VERSION ""

NS_ :

BS_:

BU_:

BO_ 2566785022 ET: 8 Vector__XXX
 SG_ EngnExhstMnfldBnk1Tmprtr1 : 16|16@1+ (0.03125,-273) [-273|1734.96875] "degC" Vector__XXX
 SG_ EngnExhstMnfldBnk1Tmprtr2 : 48|16@1+ (0.03125,-273) [-273|1734.96875] "degC" Vector__XXX
 SG_ EngnExhstMnfldBnk2Tmprtr1 : 0|16@1+ (0.03125,-273) [-273|1734.96875] "degC" Vector__XXX
 SG_ EngnExhstMnfldBnk2Tmprtr2 : 32|16@1+ (0.03125,-273) [-273|1734.96875] "degC" Vector__XXX

BO_ 2566799614 LD: 8 Vector__XXX
 SG_ AlternateBeamHeadLightData : 2|2@1+ (1,0) [0|3] "" Vector__XXX
 SG_ BackUpLightandAlarmHorn : 16|2@1+ (1,0) [0|3] "" Vector__XXX
 SG_ CenterStopLight : 18|2@1+ (1,0) [0|3] "" Vector__XXX
 SG_ HighBeamHeadLightData : 6|2@1+ (1,0) [0|3] "" Vector__XXX
 SG_ ImplementClearanceLight : 24|2@1+ (1,0) [0|3] "" Vector__XXX
 SG_ ImplementLeftFacingWorkLight : 60|2@1+ (1,0) [0|3] "" Vector__XXX
 SG_ ImplementLeftForwardWorkLight : 54|2@1+ (1,0) [0|3] "" Vector__XXX
 SG_ ImplementMarkerLight : 28|2@1+ (1,0) [0|3] "" Vector__XXX
 SG_ ImplementOEMOption1Light : 50|2@1+ (1,0) [0|3] "" Vector__XXX
 SG_ ImplementOEMOption2Light : 48|2@1+ (1,0) [0|3] "" Vector__XXX
 SG_ ImplementRearWorkLight : 62|2@1+ (1,0) [0|3] "" Vector__XXX
 SG_ ImplementRightFacingWorkLight : 52|2@1+ (1,0) [0|3] "" Vector__XXX
 SG_ ImplementRightForwardWorkLight : 58|2@1+ (1,0) [0|3] "" Vector__XXX
 SG_ LeftStopLight : 22|2@1+ (1,0) [0|3] "" Vector__XXX
 SG_ LeftTurnSignalLights : 14|2@1+ (1,0) [0|3] "" Vector__XXX
 SG_ LowBeamHeadLightData : 4|2@1+ (1,0) [0|3] "" Vector__XXX
 SG_ RearFogLights : 32|2@1+ (1,0) [0|3] "" Vector__XXX
 SG_ RightStopLight : 20|2@1+ (1,0) [0|3] "" Vector__XXX
 SG_ RightTurnSignalLights : 12|2@1+ (1,0) [0|3] "" Vector__XXX
 SG_ RotatingBeaconLight : 10|2@1+ (1,0) [0|3] "" Vector__XXX
 SG_ RunningLight : 0|2@1+ (1,0) [0|3] "" Vector__XXX
 SG_ TractorClearanceLight : 26|2@1+ (1,0) [0|3] "" Vector__XXX
 SG_ TractorFrontFogLights : 8|2@1+ (1,0) [0|3] "" Vector__XXX
 SG_ TractorMarkerLight : 30|2@1+ (1,0) [0|3] "" Vector__XXX
 SG_ TractorRearLowMountedWorkLights : 36|2@1+ (1,0) [0|3] "" Vector__XXX
 SG_ TractorSideLowMountedWorkLights : 40|2@1+ (1,0) [0|3] "" Vector__XXX
 SG_ TrtrFrntHghMntdWrkLghts : 46|2@1+ (1,0) [0|3] "" Vector__XXX
 SG_ TrtrFrntLwMntdWrkLghts : 44|2@1+ (1,0) [0|3] "" Vector__XXX
 SG_ TrtrRrHghMntdWrkLghts : 38|2@1+ (1,0) [0|3] "" Vector__XXX
 SG_ TrtrSdHghMntdWrkLghts : 42|2@1+ (1,0) [0|3] "" Vector__XXX
 SG_ TrtrUndrsdMntdWrkLghts : 34|2@1+ (1,0) [0|3] "" Vector__XXX

BO_ 2566802174 ETC7: 8 Vector__XXX
 SG_ ActiveShiftConsoleIndicator : 10|2@1+ (1,0) [0|3] "" Vector__XXX
 SG_ TransmissionEngineCrankEnable : 12|2@1+ (1,0) [0|3] "" Vector__XXX
 SG_ TransmissionManualModeIndicator : 54|2@1+ (1,0) [0|3] "" Vector__XXX
 SG_ TransmissionMode10Indicator : 46|2@1+ (1,0) [0|3] "" Vector__XXX
 SG_ TransmissionMode1Indicator : 22|2@1+ (1,0) [0|3] "" Vector__XXX
 SG_ TransmissionMode2Indicator : 20|2@1+ (1,0) [0|3] "" Vector__XXX
 SG_ TransmissionMode3Indicator : 18|2@1+ (1,0) [0|3] "" Vector__XXX
 SG_ TransmissionMode4Indicator : 16|2@1+ (1,0) [0|3] "" Vector__XXX
 SG_ TransmissionMode5Indicator : 32|2@1+ (1,0) [0|3] "" Vector__XXX
 SG_ TransmissionMode6Indicator : 34|2@1+ (1,0) [0|3] "" Vector__XXX
 SG_ TransmissionMode7Indicator : 36|2@1+ (1,0) [0|3] "" Vector__XXX
 SG_ TransmissionMode8Indicator : 38|2@1+ (1,0) [0|3] "" Vector__XXX
 SG_ TransmissionMode9Indicator : 44|2@1+ (1,0) [0|3] "" Vector__XXX
 SG_ TransmissionServiceIndicator : 2|2@1+ (1,0) [0|3] "" Vector__XXX
 SG_ TransmissionWarningIndicator : 42|2@1+ (1,0) [0|3] "" Vector__XXX
 SG_ TrnsmssnArSpplPrssrIndtr : 48|3@1+ (1,0) [0|7] "" Vector__XXX
 SG_ TrnsmssnAtNtrlMnlRtrnStt : 51|3@1+ (1,0) [0|7] "" Vector__XXX
 SG_ TrnsmssnCrrntRngDsplBlnkStt : 0|2@1+ (1,0) [0|3] "" Vector__XXX
 SG_ TrnsmssnRdfrBrkRls : 8|2@1+ (1,0) [0|3] "" Vector__XXX
 SG_ TrnsmssnRqstdGrFdk : 24|8@1+ (1,-125) [-125|125] "gear value" Vector__XXX
 SG_ TrnsmssnRqstdRngDsplBlnkStt : 4|2@1+ (1,0) [0|3] "" Vector__XXX
 SG_ TrnsmssnRqstdRngDsplFlshStt : 6|2@1+ (1,0) [0|3] "" Vector__XXX
 SG_ TrnsmssnRvrsGrShftInhtStts : 40|2@1+ (1,0) [0|3] "" Vector__XXX
 SG_ TrnsmssnShftInhtIndtr : 14|2@1+ (1,0) [0|3] "" Vector__XXX

BO_ 2566802430 TCFG2: 8 Vector__XXX
 SG_ TransmissionReferenceTorque : 16|16@1+ (1,0) [0|64255] "Nm" Vector__XXX
 SG_ TransmissionTorqueLimit : 0|16@1+ (1,0) [0|64255] "Nm" Vector__XXX
 SG_ TrnsmssnCmmntnsFlrIdlTrqLmt : 32|8@1+ (1,-125) [-125|125] "%" Vector__XXX

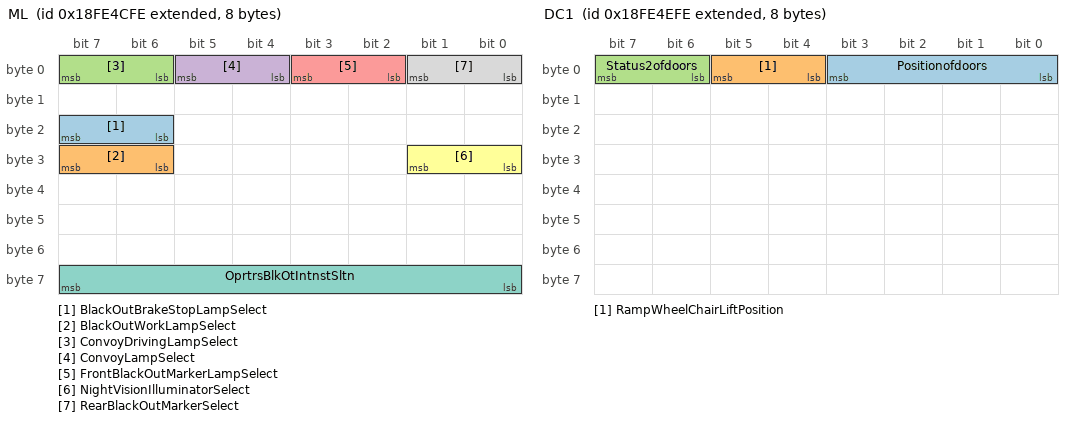
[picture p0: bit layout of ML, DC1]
BO_ 2566802686 ML: 8 Vector__XXX
 SG_ BlackOutBrakeStopLampSelect : 22|2@1+ (1,0) [0|3] "" Vector__XXX
 SG_ BlackOutWorkLampSelect : 30|2@1+ (1,0) [0|3] "" Vector__XXX
 SG_ ConvoyDrivingLampSelect : 6|2@1+ (1,0) [0|3] "" Vector__XXX
 SG_ ConvoyLampSelect : 4|2@1+ (1,0) [0|3] "" Vector__XXX
 SG_ FrontBlackOutMarkerLampSelect : 2|2@1+ (1,0) [0|3] "" Vector__XXX
 SG_ NightVisionIlluminatorSelect : 24|2@1+ (1,0) [0|3] "" Vector__XXX
 SG_ OprtrsBlkOtIntnstSltn : 56|8@1+ (0.4,0) [0|100] "%" Vector__XXX
 SG_ RearBlackOutMarkerSelect : 0|2@1+ (1,0) [0|3] "" Vector__XXX

BO_ 2566803198 DC1: 8 Vector__XXX
 SG_ Positionofdoors : 0|4@1+ (1,0) [0|15] "" Vector__XXX
 SG_ RampWheelChairLiftPosition : 4|2@1+ (1,0) [0|3] "" Vector__XXX
 SG_ Status2ofdoors : 6|2@1+ (1,0) [0|3] "" Vector__XXX

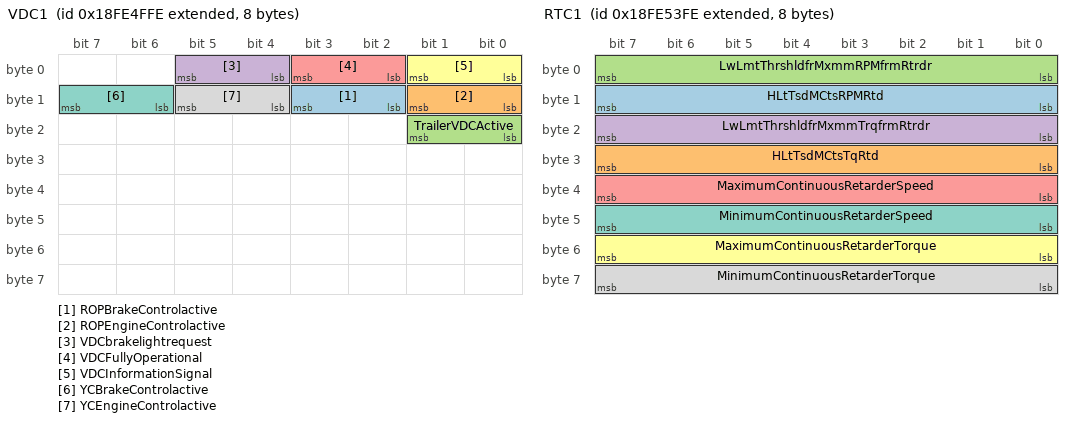
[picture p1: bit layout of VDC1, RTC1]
BO_ 2566803454 VDC1: 8 Vector__XXX
 SG_ ROPBrakeControlactive : 10|2@1+ (1,0) [0|3] "" Vector__XXX
 SG_ ROPEngineControlactive : 8|2@1+ (1,0) [0|3] "" Vector__XXX
 SG_ TrailerVDCActive : 16|2@1+ (1,0) [0|3] "" Vector__XXX
 SG_ VDCbrakelightrequest : 4|2@1+ (1,0) [0|3] "" Vector__XXX
 SG_ VDCFullyOperational : 2|2@1+ (1,0) [0|3] "" Vector__XXX
 SG_ VDCInformationSignal : 0|2@1+ (1,0) [0|3] "" Vector__XXX
 SG_ YCBrakeControlactive : 14|2@1+ (1,0) [0|3] "" Vector__XXX
 SG_ YCEngineControlactive : 12|2@1+ (1,0) [0|3] "" Vector__XXX

BO_ 2566803710 BT1: 8 Vector__XXX
 SG_ SLIBattery1Temperature : 0|8@1+ (1,-40) [-40|210] "degC" Vector__XXX
 SG_ SLIBattery2Temperature : 8|8@1+ (1,-40) [-40|210] "degC" Vector__XXX
 SG_ SLIBattery3Temperature : 16|8@1+ (1,-40) [-40|210] "degC" Vector__XXX
 SG_ SLIBattery4Temperature : 24|8@1+ (1,-40) [-40|210] "degC" Vector__XXX

BO_ 2566803966 ACC2: 8 Vector__XXX
 SG_ ACCusagedemand : 0|2@1+ (1,0) [0|3] "" Vector__XXX
 SG_ RequestedACCDistanceMode : 5|3@1+ (1,0) [0|7] "" Vector__XXX

BO_ 2566804222 VEP3: 8 Vector__XXX
 SG_ AltrntrCrrntHghRngRsltn : 0|16@1+ (0.05,-1600) [-1600|1612.75] "A" Vector__XXX
 SG_ SLIBattery2NetCurrent : 32|16@1+ (0.05,-1600) [-1600|1612.75] "A" Vector__XXX
 SG_ SLIBttr1NtCrrntHghRngRsltn : 16|16@1+ (0.05,-1600) [-1600|1612.75] "A" Vector__XXX

BO_ 2566804478 RTC1: 8 Vector__XXX
 SG_ HLtTsdMCtsRPMRtd : 8|8@1+ (32,0) [0|8000] "rpm" Vector__XXX
 SG_ HLtTsdMCtsTqRtd : 24|8@1+ (1,-125) [-125|125] "%" Vector__XXX
 SG_ LwLmtThrshldfrMxmmRPMfrmRtrdr : 0|8@1+ (32,0) [0|8000] "rpm" Vector__XXX
 SG_ LwLmtThrshldfrMxmmTrqfrmRtrdr : 16|8@1+ (1,-125) [-125|125] "%" Vector__XXX
 SG_ MaximumContinuousRetarderSpeed : 32|8@1+ (32,0) [0|8000] "rpm" Vector__XXX
 SG_ MaximumContinuousRetarderTorque : 48|8@1+ (1,-125) [-125|125] "%" Vector__XXX
 SG_ MinimumContinuousRetarderSpeed : 40|8@1+ (32,0) [0|8000] "rpm" Vector__XXX
 SG_ MinimumContinuousRetarderTorque : 56|8@1+ (1,-125) [-125|125] "%" Vector__XXX

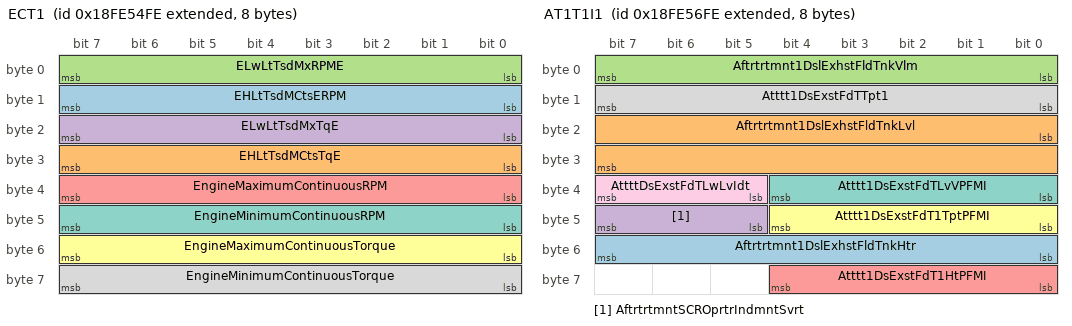
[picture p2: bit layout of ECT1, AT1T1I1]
BO_ 2566804734 ECT1: 8 Vector__XXX
 SG_ EHLtTsdMCtsERPM : 8|8@1+ (32,0) [0|8000] "rpm" Vector__XXX
 SG_ EHLtTsdMCtsTqE : 24|8@1+ (1,-125) [-125|125] "%" Vector__XXX
 SG_ ELwLtTsdMxRPME : 0|8@1+ (32,0) [0|8000] "rpm" Vector__XXX
 SG_ ELwLtTsdMxTqE : 16|8@1+ (1,-125) [-125|125] "%" Vector__XXX
 SG_ EngineMaximumContinuousRPM : 32|8@1+ (32,0) [0|8000] "rpm" Vector__XXX
 SG_ EngineMaximumContinuousTorque : 48|8@1+ (1,-125) [-125|125] "%" Vector__XXX
 SG_ EngineMinimumContinuousRPM : 40|8@1+ (32,0) [0|8000] "rpm" Vector__XXX
 SG_ EngineMinimumContinuousTorque : 56|8@1+ (1,-125) [-125|125] "%" Vector__XXX

BO_ 2566804990 GFD: 8 Vector__XXX
 SG_ Fuelenergycontent : 32|16@1+ (0.00390625,0) [0|250.996] "MJ/(Nm*Nm*Nm)" Vector__XXX
 SG_ ReferenceEngineGasMassFlowRate : 16|16@1+ (0.05,0) [0|3212.75] "kg/h" Vector__XXX
 SG_ SpecificHeatRatio : 0|16@1+ (0.001,0) [0|64.255] "Ratio" Vector__XXX

BO_ 2566805246 AT1T1I1: 8 Vector__XXX
 SG_ Aftrtrtmnt1DslExhstFldTnkHtr : 48|8@1+ (0.4,0) [0|100] "%" Vector__XXX
 SG_ Aftrtrtmnt1DslExhstFldTnkLvl : 16|16@1+ (0.1,0) [0|6425.5] "mm" Vector__XXX
 SG_ Aftrtrtmnt1DslExhstFldTnkVlm : 0|8@1+ (0.4,0) [0|100] "%" Vector__XXX
 SG_ AftrtrtmntSCROprtrIndmntSvrt : 45|3@1+ (1,0) [0|7] "" Vector__XXX
 SG_ Atttt1DsExstFdT1HtPFMI : 56|5@1+ (1,0) [0|31] "binary" Vector__XXX
 SG_ Atttt1DsExstFdT1TptPFMI : 40|5@1+ (1,0) [0|31] "binary" Vector__XXX
 SG_ Atttt1DsExstFdTLvVPFMI : 32|5@1+ (1,0) [0|31] "binary" Vector__XXX
 SG_ Atttt1DsExstFdTTpt1 : 8|8@1+ (1,-40) [-40|210] "degC" Vector__XXX
 SG_ AttttDsExstFdTLwLvIdt : 37|3@1+ (1,0) [0|7] "" Vector__XXX

BO_ 2566805758 ASC4: 8 Vector__XXX
 SG_ BellowPressureFrontAxleLeft : 0|16@1+ (0.1,0) [0|6425.5] "kPa" Vector__XXX
 SG_ BellowPressureFrontAxleRight : 16|16@1+ (0.1,0) [0|6425.5] "kPa" Vector__XXX
 SG_ BellowPressureRearAxleLeft : 32|16@1+ (0.1,0) [0|6425.5] "kPa" Vector__XXX
 SG_ BellowPressureRearAxleRight : 48|16@1+ (0.1,0) [0|6425.5] "kPa" Vector__XXX

BO_ 2566806014 ASC3: 8 Vector__XXX
 SG_ RelativeLevelFrontAxleLeft : 0|16@1+ (0.1,-3200) [-3200|3225.5] "mm" Vector__XXX
 SG_ RelativeLevelFrontAxleRight : 16|16@1+ (0.1,-3200) [-3200|3225.5] "mm" Vector__XXX
 SG_ RelativeLevelRearAxleLeft : 32|16@1+ (0.1,-3200) [-3200|3225.5] "mm" Vector__XXX
 SG_ RelativeLevelRearAxleRight : 48|16@1+ (0.1,-3200) [-3200|3225.5] "mm" Vector__XXX

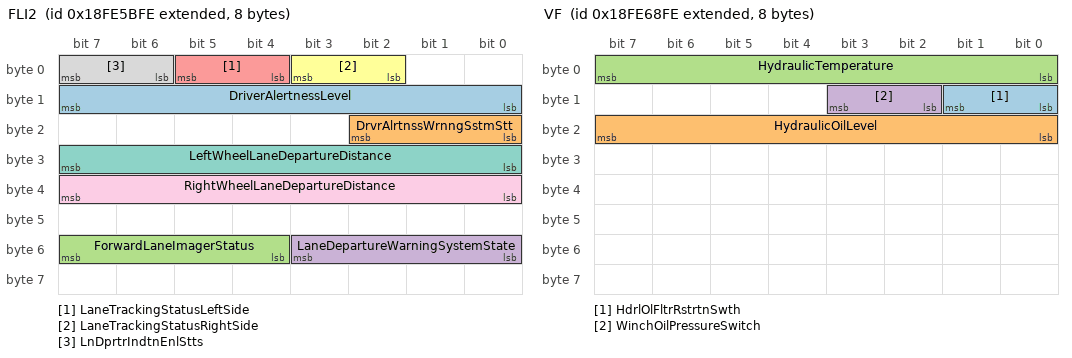
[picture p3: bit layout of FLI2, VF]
BO_ 2566806526 FLI2: 8 Vector__XXX
 SG_ DriverAlertnessLevel : 8|8@1+ (0.4,0) [0|100] "%" Vector__XXX
 SG_ DrvrAlrtnssWrnngSstmStt : 16|3@1+ (1,0) [0|7] "" Vector__XXX
 SG_ ForwardLaneImagerStatus : 52|4@1+ (1,0) [0|15] "" Vector__XXX
 SG_ LaneDepartureWarningSystemState : 48|4@1+ (1,0) [0|15] "" Vector__XXX
 SG_ LaneTrackingStatusLeftSide : 4|2@1+ (1,0) [0|3] "" Vector__XXX
 SG_ LaneTrackingStatusRightSide : 2|2@1+ (1,0) [0|3] "" Vector__XXX
 SG_ LeftWheelLaneDepartureDistance : 24|8@1+ (1,-125) [-125|125] "cm" Vector__XXX
 SG_ LnDprtrIndtnEnlStts : 6|2@1+ (1,0) [0|3] "" Vector__XXX
 SG_ RightWheelLaneDepartureDistance : 32|8@1+ (1,-125) [-125|125] "cm" Vector__XXX

BO_ 2566809342 BM: 8 Vector__XXX
 SG_ BatteryMainSwitchHoldState : 0|2@1+ (1,0) [0|3] "" Vector__XXX

BO_ 2566809598 CCC: 8 Vector__XXX
 SG_ AxlrHtrMxmmOtptPwr : 0|16@1+ (2,0) [0|128510] "W" Vector__XXX

BO_ 2566809854 VF: 8 Vector__XXX
 SG_ HdrlOlFltrRstrtnSwth : 8|2@1+ (1,0) [0|3] "" Vector__XXX
 SG_ HydraulicOilLevel : 16|8@1+ (0.4,0) [0|100] "%" Vector__XXX
 SG_ HydraulicTemperature : 0|8@1+ (1,-40) [-40|210] "degC" Vector__XXX
 SG_ WinchOilPressureSwitch : 10|2@1+ (1,0) [0|3] "" Vector__XXX

BO_ 2566810110 ET3: 8 Vector__XXX
 SG_ EngnChrgArClr1OtltTmprtr : 48|16@1+ (0.03125,-273) [-273|1734.96875] "degC" Vector__XXX
 SG_ EngnClntTmprtrHghRsltn : 16|16@1+ (0.03125,-273) [-273|1734.96875] "degC" Vector__XXX
 SG_ EngnIntkMnfld1TmprtrHghRsltn : 0|16@1+ (0.03125,-273) [-273|1734.96875] "degC" Vector__XXX
 SG_ EngnIntkVlvAttnSstmOlTmprtr : 32|16@1+ (0.03125,-273) [-273|1734.96875] "degC" Vector__XXX

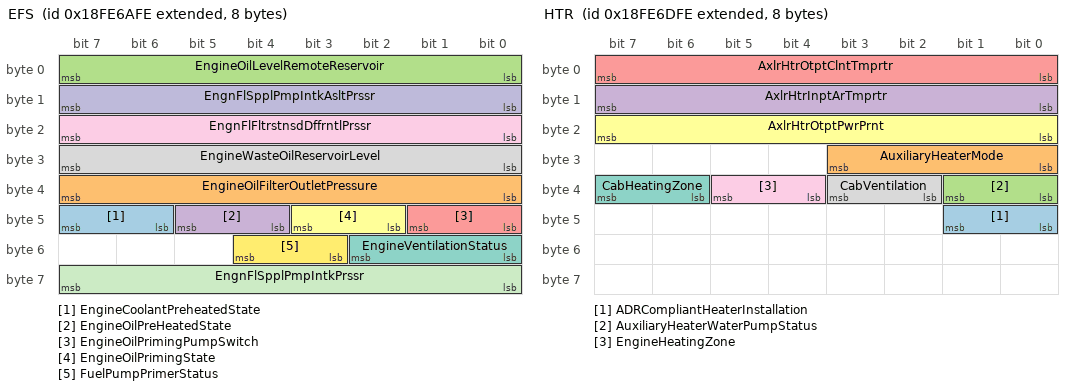
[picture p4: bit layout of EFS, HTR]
BO_ 2566810366 EFS: 8 Vector__XXX
 SG_ EngineCoolantPreheatedState : 46|2@1+ (1,0) [0|3] "" Vector__XXX
 SG_ EngineOilFilterOutletPressure : 32|8@1+ (4,0) [0|1000] "kPa" Vector__XXX
 SG_ EngineOilLevelRemoteReservoir : 0|8@1+ (0.4,0) [0|100] "%" Vector__XXX
 SG_ EngineOilPreHeatedState : 44|2@1+ (1,0) [0|3] "" Vector__XXX
 SG_ EngineOilPrimingPumpSwitch : 40|2@1+ (1,0) [0|3] "" Vector__XXX
 SG_ EngineOilPrimingState : 42|2@1+ (1,0) [0|3] "" Vector__XXX
 SG_ EngineVentilationStatus : 48|3@1+ (1,0) [0|7] "" Vector__XXX
 SG_ EngineWasteOilReservoirLevel : 24|8@1+ (0.4,0) [0|100] "%" Vector__XXX
 SG_ EngnFlFltrstnsdDffrntlPrssr : 16|8@1+ (2,0) [0|500] "kPa" Vector__XXX
 SG_ EngnFlSpplPmpIntkAsltPrssr : 8|8@1+ (2,0) [0|500] "kPa" Vector__XXX
 SG_ EngnFlSpplPmpIntkPrssr : 56|8@1+ (2,0) [0|500] "kPa" Vector__XXX
 SG_ FuelPumpPrimerStatus : 51|2@1+ (1,0) [0|3] "" Vector__XXX

BO_ 2566810622 DI: 8 Vector__XXX
 SG_ Driver1identification : 0|8@1+ (1,0) [0|255] "ASCII" Vector__XXX
 SG_ Driver2identification : 8|8@1+ (1,0) [0|255] "ASCII" Vector__XXX

BO_ 2566811134 HTR: 8 Vector__XXX
 SG_ ADRCompliantHeaterInstallation : 40|2@1+ (1,0) [0|3] "" Vector__XXX
 SG_ AuxiliaryHeaterMode : 24|4@1+ (1,0) [0|15] "" Vector__XXX
 SG_ AuxiliaryHeaterWaterPumpStatus : 32|2@1+ (1,0) [0|3] "" Vector__XXX
 SG_ AxlrHtrInptArTmprtr : 8|8@1+ (1,-40) [-40|210] "degC" Vector__XXX
 SG_ AxlrHtrOtptClntTmprtr : 0|8@1+ (1,-40) [-40|210] "degC" Vector__XXX
 SG_ AxlrHtrOtptPwrPrnt : 16|8@1+ (0.4,0) [0|100] "%" Vector__XXX
 SG_ CabHeatingZone : 38|2@1+ (1,0) [0|3] "" Vector__XXX
 SG_ CabVentilation : 34|2@1+ (1,0) [0|3] "" Vector__XXX
 SG_ EngineHeatingZone : 36|2@1+ (1,0) [0|3] "" Vector__XXX

BO_ 2566811902 CVW: 8 Vector__XXX
 SG_ GrossCombinationVehicleWeight : 16|16@1+ (10,0) [0|642550] "kg" Vector__XXX
 SG_ PoweredVehicleWeight : 0|16@1+ (10,0) [0|642550] "kg" Vector__XXX

BO_ 2566819326 VEP2: 8 Vector__XXX
 SG_ BatteryPotentialPowerInput2 : 0|16@1+ (0.05,0) [0|3212.75] "V" Vector__XXX
 SG_ ECUPowerOutputSupplyVoltage1 : 16|16@1+ (0.05,0) [0|3212.75] "V" Vector__XXX
 SG_ ECUPowerOutputSupplyVoltage2 : 32|16@1+ (0.05,0) [0|3212.75] "V" Vector__XXX
 SG_ ECUPowerOutputSupplyVoltage3 : 48|16@1+ (0.05,0) [0|3212.75] "V" Vector__XXX

BO_ 2566819838 SP2: 8 Vector__XXX
 SG_ EngnExtrnlShtdwnArSpplPrssr : 0|16@1+ (0.5,0) [0|32127.5] "kPa" Vector__XXX

BO_ 2566820094 ETH: 33 Vector__XXX
 SG_ CalibrationRecordDurationTime : 80|32@1+ (0.05,0) [0|210554060.75] "h" Vector__XXX
 SG_ CalibrationRecordStartDay : 64|8@1+ (0.25,0) [0|62.5] "days" Vector__XXX
 SG_ CalibrationRecordStartMonth : 56|8@1+ (1,0) [0|250] "months" Vector__XXX
 SG_ CalibrationRecordStartYear : 72|8@1+ (1,1985) [1985|2235] "years" Vector__XXX
 SG_ EnginePeakTorque1 : 24|16@1+ (1,0) [0|64255] "Nm" Vector__XXX
 SG_ EnginePeakTorque2 : 40|16@1+ (1,0) [0|64255] "Nm" Vector__XXX
 SG_ EnginePower : 8|16@1+ (0.5,0) [0|32127.5] "kW" Vector__XXX
 SG_ EngineTorqueLimit1Transmission : 136|16@1+ (1,0) [0|64255] "Nm" Vector__XXX
 SG_ EngineTorqueLimit2Transmission : 168|16@1+ (1,0) [0|64255] "Nm" Vector__XXX
 SG_ EngineTorqueLimit3Transmission : 200|16@1+ (1,0) [0|64255] "Nm" Vector__XXX
 SG_ EngineTorqueLimit4Transmission : 216|16@1+ (1,0) [0|64255] "Nm" Vector__XXX
 SG_ EngineTorqueLimit5Switch : 232|16@1+ (1,0) [0|64255] "Nm" Vector__XXX
 SG_ EngineTorqueLimit6AxleInput : 248|16@1+ (2,0) [0|128510] "Nm" Vector__XXX
 SG_ EngineTorqueLimitFeature : 114|3@1+ (1,0) [0|7] "" Vector__XXX
 SG_ NmrfEngnTrqHstrRrds : 0|8@1+ (1,0) [0|250] "Record" Vector__XXX
 SG_ TorqueLimitingFeatureStatus : 112|2@1+ (1,0) [0|3] "" Vector__XXX
 SG_ TransmissionGearRatio1 : 120|16@1+ (0.01,0) [0|642.55] "" Vector__XXX
 SG_ TransmissionGearRatio2 : 152|16@1+ (0.01,0) [0|642.55] "" Vector__XXX
 SG_ TransmissionGearRatio3 : 184|16@1+ (0.01,0) [0|642.55] "" Vector__XXX

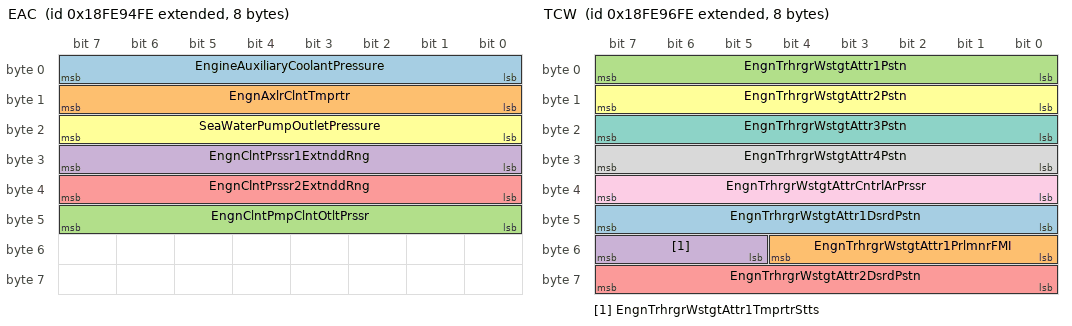
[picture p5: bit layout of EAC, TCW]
BO_ 2566821118 EAC: 8 Vector__XXX
 SG_ EngineAuxiliaryCoolantPressure : 0|8@1+ (4,0) [0|1000] "kPa" Vector__XXX
 SG_ EngnAxlrClntTmprtr : 8|8@1+ (1,-40) [-40|210] "degC" Vector__XXX
 SG_ EngnClntPmpClntOtltPrssr : 40|8@1+ (2,0) [0|500] "kPa" Vector__XXX
 SG_ EngnClntPrssr1ExtnddRng : 24|8@1+ (4,0) [0|1000] "kPa" Vector__XXX
 SG_ EngnClntPrssr2ExtnddRng : 32|8@1+ (4,0) [0|1000] "kPa" Vector__XXX
 SG_ SeaWaterPumpOutletPressure : 16|8@1+ (2,0) [0|500] "kPa" Vector__XXX

BO_ 2566821630 TCW: 8 Vector__XXX
 SG_ EngnTrhrgrWstgtAttr1DsrdPstn : 40|8@1+ (0.4,0) [0|100] "%" Vector__XXX
 SG_ EngnTrhrgrWstgtAttr1PrlmnrFMI : 48|5@1+ (1,0) [0|31] "binary" Vector__XXX
 SG_ EngnTrhrgrWstgtAttr1Pstn : 0|8@1+ (0.4,0) [0|100] "%" Vector__XXX
 SG_ EngnTrhrgrWstgtAttr1TmprtrStts : 53|3@1+ (1,0) [0|7] "" Vector__XXX
 SG_ EngnTrhrgrWstgtAttr2DsrdPstn : 56|8@1+ (0.4,0) [0|100] "%" Vector__XXX
 SG_ EngnTrhrgrWstgtAttr2Pstn : 8|8@1+ (0.4,0) [0|100] "%" Vector__XXX
 SG_ EngnTrhrgrWstgtAttr3Pstn : 16|8@1+ (0.4,0) [0|100] "%" Vector__XXX
 SG_ EngnTrhrgrWstgtAttr4Pstn : 24|8@1+ (0.4,0) [0|100] "%" Vector__XXX
 SG_ EngnTrhrgrWstgtAttrCntrlArPrssr : 32|8@1+ (4,0) [0|1000] "kPa" Vector__XXX

BO_ 2566821886 TCI5: 8 Vector__XXX
 SG_ EngnTrhrgr1TrnOtltTmprtr : 0|16@1+ (0.03125,-273) [-273|1734.96875] "degC" Vector__XXX
 SG_ EngnTrhrgr2TrnOtltTmprtr : 16|16@1+ (0.03125,-273) [-273|1734.96875] "degC" Vector__XXX
 SG_ EngnTrhrgr3TrnOtltTmprtr : 32|16@1+ (0.03125,-273) [-273|1734.96875] "degC" Vector__XXX
 SG_ EngnTrhrgr4TrnOtltTmprtr : 48|16@1+ (0.03125,-273) [-273|1734.96875] "degC" Vector__XXX

BO_ 2566822142 TCI4: 8 Vector__XXX
 SG_ EngnTrhrgr1TrnIntkTmprtr : 0|16@1+ (0.03125,-273) [-273|1734.96875] "degC" Vector__XXX
 SG_ EngnTrhrgr2TrnIntkTmprtr : 16|16@1+ (0.03125,-273) [-273|1734.96875] "degC" Vector__XXX
 SG_ EngnTrhrgr3TrnIntkTmprtr : 32|16@1+ (0.03125,-273) [-273|1734.96875] "degC" Vector__XXX
 SG_ EngnTrhrgr4TrnIntkTmprtr : 48|16@1+ (0.03125,-273) [-273|1734.96875] "degC" Vector__XXX

BO_ 2566822398 TCI3: 8 Vector__XXX
 SG_ EngnTrhrgr1CmprssrIntkPrssr : 0|16@1+ (0.0078125,-250) [-250|251.99] "kPa" Vector__XXX
 SG_ EngnTrhrgr2CmprssrIntkPrssr : 16|16@1+ (0.0078125,-250) [-250|251.99] "kPa" Vector__XXX
 SG_ EngnTrhrgr3CmprssrIntkPrssr : 32|16@1+ (0.0078125,-250) [-250|251.99] "kPa" Vector__XXX
 SG_ EngnTrhrgr4CmprssrIntkPrssr : 48|16@1+ (0.0078125,-250) [-250|251.99] "kPa" Vector__XXX

BO_ 2566822654 TCI2: 8 Vector__XXX
 SG_ EngnTrhrgr1CmprssrIntkTmprtr : 0|16@1+ (0.03125,-273) [-273|1734.96875] "degC" Vector__XXX
 SG_ EngnTrhrgr2CmprssrIntkTmprtr : 16|16@1+ (0.03125,-273) [-273|1734.96875] "degC" Vector__XXX
 SG_ EngnTrhrgr3CmprssrIntkTmprtr : 32|16@1+ (0.03125,-273) [-273|1734.96875] "degC" Vector__XXX
 SG_ EngnTrhrgr4CmprssrIntkTmprtr : 48|16@1+ (0.03125,-273) [-273|1734.96875] "degC" Vector__XXX

BO_ 2566823166 MBT3: 8 Vector__XXX
 SG_ EngineMainBearing10Temperature : 16|16@1+ (0.03125,-273) [-273|1734.96875] "degC" Vector__XXX
 SG_ EngineMainBearing11Temperature : 32|16@1+ (0.03125,-273) [-273|1734.96875] "degC" Vector__XXX
 SG_ EngineMainBearing12Temperature : 48|16@1+ (0.03125,-273) [-273|1734.96875] "degC" Vector__XXX
 SG_ EngineMainBearing9Temperature : 0|16@1+ (0.03125,-273) [-273|1734.96875] "degC" Vector__XXX

BO_ 2566823422 MBT2: 8 Vector__XXX
 SG_ EngineMainBearing5Temperature : 0|16@1+ (0.03125,-273) [-273|1734.96875] "degC" Vector__XXX
 SG_ EngineMainBearing6Temperature : 16|16@1+ (0.03125,-273) [-273|1734.96875] "degC" Vector__XXX
 SG_ EngineMainBearing7Temperature : 32|16@1+ (0.03125,-273) [-273|1734.96875] "degC" Vector__XXX
 SG_ EngineMainBearing8Temperature : 48|16@1+ (0.03125,-273) [-273|1734.96875] "degC" Vector__XXX

BO_ 2566823678 MBT1: 8 Vector__XXX
 SG_ EngineMainBearing1Temperature : 0|16@1+ (0.03125,-273) [-273|1734.96875] "degC" Vector__XXX
 SG_ EngineMainBearing2Temperature : 16|16@1+ (0.03125,-273) [-273|1734.96875] "degC" Vector__XXX
 SG_ EngineMainBearing3Temperature : 32|16@1+ (0.03125,-273) [-273|1734.96875] "degC" Vector__XXX
 SG_ EngineMainBearing4Temperature : 48|16@1+ (0.03125,-273) [-273|1734.96875] "degC" Vector__XXX

BO_ 2566824190 EPT4: 8 Vector__XXX
 SG_ EngnExhstGsPrt13Tmprtr : 0|16@1+ (0.03125,-273) [-273|1734.96875] "degC" Vector__XXX
 SG_ EngnExhstGsPrt14Tmprtr : 16|16@1+ (0.03125,-273) [-273|1734.96875] "degC" Vector__XXX
 SG_ EngnExhstGsPrt15Tmprtr : 32|16@1+ (0.03125,-273) [-273|1734.96875] "degC" Vector__XXX
 SG_ EngnExhstGsPrt16Tmprtr : 48|16@1+ (0.03125,-273) [-273|1734.96875] "degC" Vector__XXX

BO_ 2566825214 ET2: 8 Vector__XXX
 SG_ EngineECUTemperature : 16|16@1+ (0.03125,-273) [-273|1734.96875] "degC" Vector__XXX
 SG_ EngineOilTemperature2 : 0|16@1+ (0.03125,-273) [-273|1734.96875] "degC" Vector__XXX
 SG_ EngnExhstGsRrltn1DffrntlPrssr : 32|16@1+ (0.0078125,-250) [-250|251.99] "kPa" Vector__XXX
 SG_ EngnExhstGsRrltn1Tmprtr : 48|16@1+ (0.03125,-273) [-273|1734.96875] "degC" Vector__XXX

BO_ 2566825726 IMT1: 8 Vector__XXX
 SG_ EngnTrhrgr1BstPrssr : 0|16@1+ (0.125,0) [0|8031.875] "kPa" Vector__XXX
 SG_ EngnTrhrgr2BstPrssr : 16|16@1+ (0.125,0) [0|8031.875] "kPa" Vector__XXX
 SG_ EngnTrhrgr3BstPrssr : 32|16@1+ (0.125,0) [0|8031.875] "kPa" Vector__XXX
 SG_ EngnTrhrgr4BstPrssr : 48|16@1+ (0.125,0) [0|8031.875] "kPa" Vector__XXX

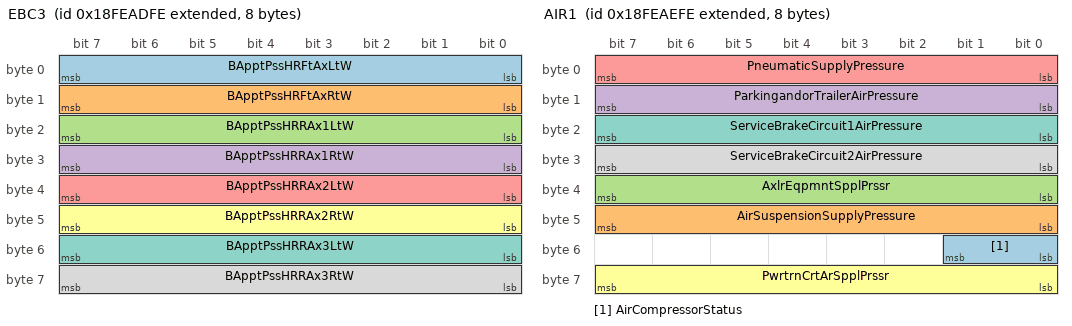
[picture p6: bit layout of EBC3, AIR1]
BO_ 2566827518 EBC3: 8 Vector__XXX
 SG_ BApptPssHRFtAxLtW : 0|8@1+ (5,0) [0|1250] "kPa" Vector__XXX
 SG_ BApptPssHRFtAxRtW : 8|8@1+ (5,0) [0|1250] "kPa" Vector__XXX
 SG_ BApptPssHRRAx1LtW : 16|8@1+ (5,0) [0|1250] "kPa" Vector__XXX
 SG_ BApptPssHRRAx1RtW : 24|8@1+ (5,0) [0|1250] "kPa" Vector__XXX
 SG_ BApptPssHRRAx2LtW : 32|8@1+ (5,0) [0|1250] "kPa" Vector__XXX
 SG_ BApptPssHRRAx2RtW : 40|8@1+ (5,0) [0|1250] "kPa" Vector__XXX
 SG_ BApptPssHRRAx3LtW : 48|8@1+ (5,0) [0|1250] "kPa" Vector__XXX
 SG_ BApptPssHRRAx3RtW : 56|8@1+ (5,0) [0|1250] "kPa" Vector__XXX

BO_ 2566827774 AIR1: 8 Vector__XXX
 SG_ AirCompressorStatus : 48|2@1+ (1,0) [0|3] "" Vector__XXX
 SG_ AirSuspensionSupplyPressure : 40|8@1+ (8,0) [0|2000] "kPa" Vector__XXX
 SG_ AxlrEqpmntSpplPrssr : 32|8@1+ (8,0) [0|2000] "kPa" Vector__XXX
 SG_ ParkingandorTrailerAirPressure : 8|8@1+ (8,0) [0|2000] "kPa" Vector__XXX
 SG_ PneumaticSupplyPressure : 0|8@1+ (8,0) [0|2000] "kPa" Vector__XXX
 SG_ PwrtrnCrtArSpplPrssr : 56|8@1+ (8,0) [0|2000] "kPa" Vector__XXX
 SG_ ServiceBrakeCircuit1AirPressure : 16|8@1+ (8,0) [0|2000] "kPa" Vector__XXX
 SG_ ServiceBrakeCircuit2AirPressure : 24|8@1+ (8,0) [0|2000] "kPa" Vector__XXX

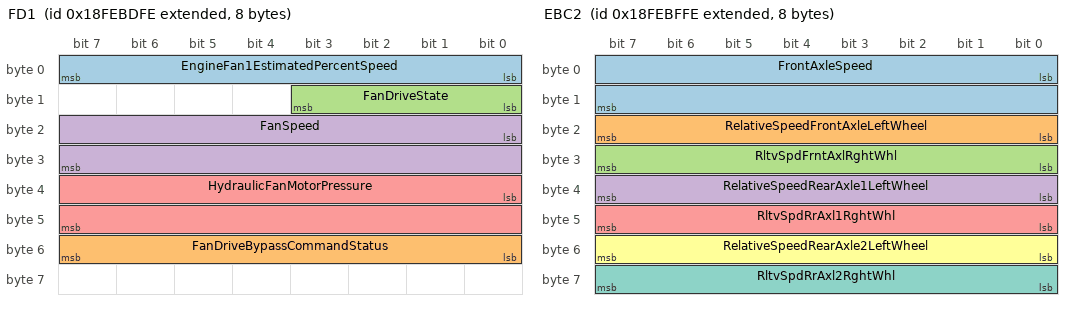
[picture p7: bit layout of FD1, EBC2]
BO_ 2566831614 FD1: 8 Vector__XXX
 SG_ EngineFan1EstimatedPercentSpeed : 0|8@1+ (0.4,0) [0|100] "%" Vector__XXX
 SG_ FanDriveBypassCommandStatus : 48|8@1+ (0.4,0) [0|100] "%" Vector__XXX
 SG_ FanDriveState : 8|4@1+ (1,0) [0|15] "" Vector__XXX
 SG_ FanSpeed : 16|16@1+ (0.125,0) [0|8031.875] "rpm" Vector__XXX
 SG_ HydraulicFanMotorPressure : 32|16@1+ (0.5,0) [0|32127.5] "kPa" Vector__XXX

BO_ 2566832126 EBC2: 8 Vector__XXX
 SG_ FrontAxleSpeed : 0|16@1+ (0.00390625,0) [0|250.996] "km/h" Vector__XXX
 SG_ RelativeSpeedFrontAxleLeftWheel : 16|8@1+ (0.0625,-7.8125) [-7.8125|7.8125] "km/h" Vector__XXX
 SG_ RltvSpdFrntAxlRghtWhl : 24|8@1+ (0.0625,-7.8125) [-7.8125|7.8125] "km/h" Vector__XXX
 SG_ RelativeSpeedRearAxle1LeftWheel : 32|8@1+ (0.0625,-7.8125) [-7.8125|7.8125] "km/h" Vector__XXX
 SG_ RltvSpdRrAxl1RghtWhl : 40|8@1+ (0.0625,-7.8125) [-7.8125|7.8125] "km/h" Vector__XXX
 SG_ RelativeSpeedRearAxle2LeftWheel : 48|8@1+ (0.0625,-7.8125) [-7.8125|7.8125] "km/h" Vector__XXX
 SG_ RltvSpdRrAxl2RghtWhl : 56|8@1+ (0.0625,-7.8125) [-7.8125|7.8125] "km/h" Vector__XXX

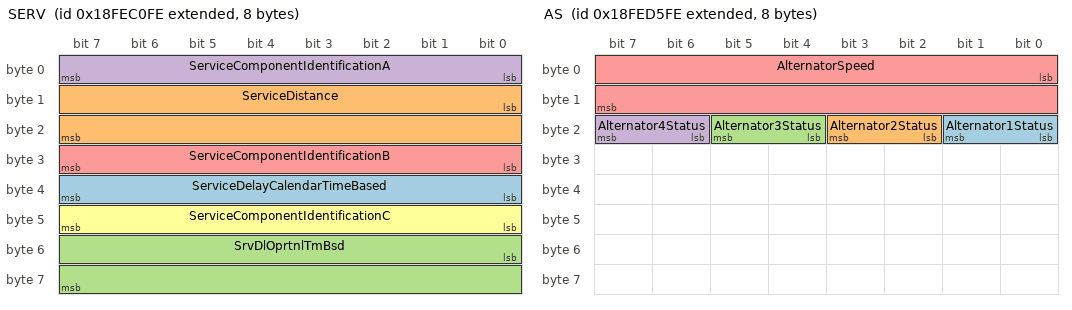
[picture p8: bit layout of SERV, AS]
BO_ 2566832382 SERV: 8 Vector__XXX
 SG_ ServiceDelayCalendarTimeBased : 32|8@1+ (1,-125) [-125|125] "weeks" Vector__XXX
 SG_ ServiceDistance : 8|16@1+ (5,-160635) [-160635|160640] "km" Vector__XXX
 SG_ SrvDlOprtnlTmBsd : 48|16@1+ (1,-32127) [-32127|32128] "h" Vector__XXX
 SG_ ServiceComponentIdentificationA : 0|8@1+ (1,0) [0|250] "ID" Vector__XXX
 SG_ ServiceComponentIdentificationB : 24|8@1+ (1,0) [0|250] "ID" Vector__XXX
 SG_ ServiceComponentIdentificationC : 40|8@1+ (1,0) [0|250] "ID" Vector__XXX

BO_ 2566832638 VDHR: 8 Vector__XXX
 SG_ TripDistanceHighResolution : 32|32@1+ (5,0) [0|21055406] "m" Vector__XXX
 SG_ TtlVhlDstnHghRsltn : 0|32@1+ (5,0) [0|21055406] "m" Vector__XXX

BO_ 2566837758 AS: 8 Vector__XXX
 SG_ Alternator1Status : 16|2@1+ (1,0) [0|3] "" Vector__XXX
 SG_ Alternator2Status : 18|2@1+ (1,0) [0|3] "" Vector__XXX
 SG_ Alternator3Status : 20|2@1+ (1,0) [0|3] "" Vector__XXX
 SG_ Alternator4Status : 22|2@1+ (1,0) [0|3] "" Vector__XXX
 SG_ AlternatorSpeed : 0|16@1+ (0.5,0) [0|32127.5] "rpm" Vector__XXX

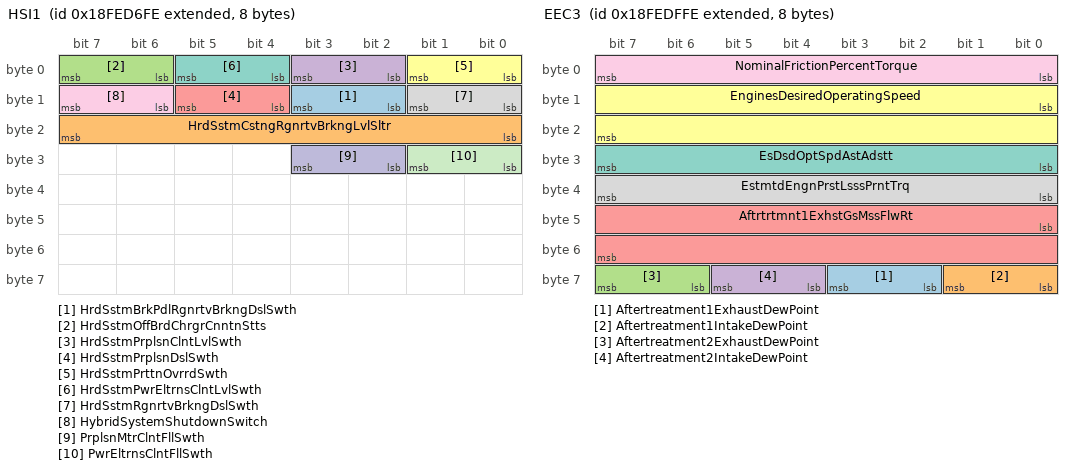
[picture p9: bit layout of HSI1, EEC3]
BO_ 2566838014 HSI1: 8 Vector__XXX
 SG_ HrdSstmBrkPdlRgnrtvBrkngDslSwth : 10|2@1+ (1,0) [0|3] "" Vector__XXX
 SG_ HrdSstmCstngRgnrtvBrkngLvlSltr : 16|8@1+ (0.4,0) [0|100] "%" Vector__XXX
 SG_ HrdSstmOffBrdChrgrCnntnStts : 6|2@1+ (1,0) [0|3] "" Vector__XXX
 SG_ HrdSstmPrplsnClntLvlSwth : 2|2@1+ (1,0) [0|3] "" Vector__XXX
 SG_ HrdSstmPrplsnDslSwth : 12|2@1+ (1,0) [0|3] "" Vector__XXX
 SG_ HrdSstmPrttnOvrrdSwth : 0|2@1+ (1,0) [0|3] "" Vector__XXX
 SG_ HrdSstmPwrEltrnsClntLvlSwth : 4|2@1+ (1,0) [0|3] "" Vector__XXX
 SG_ HrdSstmRgnrtvBrkngDslSwth : 8|2@1+ (1,0) [0|3] "" Vector__XXX
 SG_ HybridSystemShutdownSwitch : 14|2@1+ (1,0) [0|3] "" Vector__XXX
 SG_ PrplsnMtrClntFllSwth : 26|2@1+ (1,0) [0|3] "" Vector__XXX
 SG_ PwrEltrnsClntFllSwth : 24|2@1+ (1,0) [0|3] "" Vector__XXX

BO_ 2566838782 AUXIO1: 8 Vector__XXX
 SG_ AuxiliaryIO01 : 6|2@1+ (1,0) [0|3] "" Vector__XXX
 SG_ AuxiliaryIO02 : 4|2@1+ (1,0) [0|3] "" Vector__XXX
 SG_ AuxiliaryIO03 : 2|2@1+ (1,0) [0|3] "" Vector__XXX
 SG_ AuxiliaryIO04 : 0|2@1+ (1,0) [0|3] "" Vector__XXX
 SG_ AuxiliaryIO05 : 14|2@1+ (1,0) [0|3] "" Vector__XXX
 SG_ AuxiliaryIO06 : 12|2@1+ (1,0) [0|3] "" Vector__XXX
 SG_ AuxiliaryIO07 : 10|2@1+ (1,0) [0|3] "" Vector__XXX
 SG_ AuxiliaryIO08 : 8|2@1+ (1,0) [0|3] "" Vector__XXX
 SG_ AuxiliaryIO09 : 22|2@1+ (1,0) [0|3] "" Vector__XXX
 SG_ AuxiliaryIO10 : 20|2@1+ (1,0) [0|3] "" Vector__XXX
 SG_ AuxiliaryIO11 : 18|2@1+ (1,0) [0|3] "" Vector__XXX
 SG_ AuxiliaryIO12 : 16|2@1+ (1,0) [0|3] "" Vector__XXX
 SG_ AuxiliaryIO13 : 30|2@1+ (1,0) [0|3] "" Vector__XXX
 SG_ AuxiliaryIO14 : 28|2@1+ (1,0) [0|3] "" Vector__XXX
 SG_ AuxiliaryIO15 : 26|2@1+ (1,0) [0|3] "" Vector__XXX
 SG_ AuxiliaryIO16 : 24|2@1+ (1,0) [0|3] "" Vector__XXX
 SG_ AuxiliaryIOChannel1 : 32|16@1+ (1,0) [0|64255] "count" Vector__XXX
 SG_ AuxiliaryIOChannel2 : 48|16@1+ (1,0) [0|64255] "count" Vector__XXX

BO_ 2566839038 SOFT: 8 Vector__XXX
 SG_ NmrfSftwrIdntftnFlds : 0|8@1+ (1,0) [0|250] "step" Vector__XXX
 SG_ SoftwareIdentification : 8|8@1+ (1,0) [0|255] "ASCII" Vector__XXX

BO_ 2566839294 EFLP2: 8 Vector__XXX
 SG_ EngnFl1InjtrMtrngRl1Prssr : 16|16@1+ (0.00390625,0) [0|250.996] "MPa" Vector__XXX
 SG_ EngnFl1InjtrMtrngRl2Prssr : 48|16@1+ (0.00390625,0) [0|250.996] "MPa" Vector__XXX
 SG_ EngnFl1InjtrTmngRl1Prssr : 32|16@1+ (0.00390625,0) [0|250.996] "MPa" Vector__XXX
 SG_ EngnFlInjtnCntrlPrssr : 0|16@1+ (0.00390625,0) [0|250.996] "MPa" Vector__XXX

BO_ 2566839550 IO: 8 Vector__XXX
 SG_ EngineTotalIdleFuelUsed : 0|32@1+ (0.5,0) [0|2105540607.5] "l" Vector__XXX
 SG_ EngineTotalIdleHours : 32|32@1+ (0.05,0) [0|210554060.75] "h" Vector__XXX

BO_ 2566839806 TC: 8 Vector__XXX
 SG_ EngineTurbocharger1Speed : 8|16@1+ (4,0) [0|257020] "rpm" Vector__XXX
 SG_ EngnTrhrgrDffrntlSpd : 32|16@1+ (4,0) [0|257020] "rpm" Vector__XXX
 SG_ EngnTrhrgrLOlPrssr1 : 0|8@1+ (4,0) [0|1000] "kPa" Vector__XXX
 SG_ EngnTrhrgrOlLvlSwth : 30|2@1+ (1,0) [0|3] "" Vector__XXX

BO_ 2566840062 AIR2: 8 Vector__XXX
 SG_ EngineAirStartPressure : 0|8@1+ (4,0) [0|1000] "kPa" Vector__XXX
 SG_ EngineAirStopPressure : 16|8@1+ (4,0) [0|1000] "kPa" Vector__XXX
 SG_ EngnArStrtPrssrExtnddRng : 8|8@1+ (16,0) [0|4000] "kPa" Vector__XXX

BO_ 2566840318 EEC3: 8 Vector__XXX
 SG_ Aftertreatment1ExhaustDewPoint : 58|2@1+ (1,0) [0|3] "" Vector__XXX
 SG_ Aftertreatment1IntakeDewPoint : 56|2@1+ (1,0) [0|3] "" Vector__XXX
 SG_ Aftertreatment2ExhaustDewPoint : 62|2@1+ (1,0) [0|3] "" Vector__XXX
 SG_ Aftertreatment2IntakeDewPoint : 60|2@1+ (1,0) [0|3] "" Vector__XXX
 SG_ Aftrtrtmnt1ExhstGsMssFlwRt : 40|16@1+ (0.2,0) [0|12851] "kg/h" Vector__XXX
 SG_ EnginesDesiredOperatingSpeed : 8|16@1+ (0.125,0) [0|8031.875] "rpm" Vector__XXX
 SG_ EsDsdOptSpdAstAdstt : 24|8@1+ (1,0) [0|250] "Ratio" Vector__XXX
 SG_ EstmtdEngnPrstLsssPrntTrq : 32|8@1+ (1,-125) [-125|125] "%" Vector__XXX
 SG_ NominalFrictionPercentTorque : 0|8@1+ (1,-125) [-125|125] "%" Vector__XXX

BO_ 2566840574 VD: 8 Vector__XXX
 SG_ TotalVehicleDistance : 32|32@1+ (0.125,0) [0|526385151.875] "km" Vector__XXX
 SG_ TripDistance : 0|32@1+ (0.125,0) [0|526385151.875] "km" Vector__XXX

BO_ 2566840830 RC: 19 Vector__XXX
 SG_ MaximumRetarderSpeedPoint2 : 40|16@1+ (0.125,0) [0|8031.875] "rpm" Vector__XXX
 SG_ RetarderControlMethod : 8|8@1+ (1,0) [0|250] "step" Vector__XXX
 SG_ RetarderLocation : 4|4@1+ (1,0) [0|15] "" Vector__XXX
 SG_ RetarderPercentTorqueAtPoint3 : 80|8@1+ (1,-125) [-125|125] "%" Vector__XXX
 SG_ RetarderPercentTorqueAtPoint4 : 104|8@1+ (1,-125) [-125|125] "%" Vector__XXX
 SG_ RetarderReferenceTorque : 128|16@1+ (1,0) [0|64255] "Nm" Vector__XXX
 SG_ RetarderSpeedAtIdlePoint1 : 16|16@1+ (0.125,0) [0|8031.875] "rpm" Vector__XXX
 SG_ RetarderSpeedAtPeakTorquePoint5 : 112|16@1+ (0.125,0) [0|8031.875] "rpm" Vector__XXX
 SG_ RetarderSpeedAtPoint3 : 64|16@1+ (0.125,0) [0|8031.875] "rpm" Vector__XXX
 SG_ RetarderSpeedAtPoint4 : 88|16@1+ (0.125,0) [0|8031.875] "rpm" Vector__XXX
 SG_ RetarderType : 0|4@1+ (1,0) [0|15] "" Vector__XXX
 SG_ RtrdrPrntTrqAtIdlPnt1 : 32|8@1+ (1,-125) [-125|125] "%" Vector__XXX
 SG_ RtrdrPrntTrqAtMxmmSpdPnt2 : 56|8@1+ (1,-125) [-125|125] "%" Vector__XXX
 SG_ RtrdrPrntTrqAtPkTrqPnt5 : 144|8@1+ (1,-125) [-125|125] "%" Vector__XXX

BO_ 2566841086 TCFG: 8 Vector__XXX
 SG_ NumberofForwardGearRatios : 8|8@1+ (1,0) [0|250] "gear value" Vector__XXX
 SG_ NumberofReverseGearRatios : 0|8@1+ (1,0) [0|250] "gear value" Vector__XXX
 SG_ TransmissionGearRatio : 16|16@1+ (0.001,0) [0|64.255] "Ratio" Vector__XXX

BO_ 2566841342 EC1: 40 Vector__XXX
 SG_ EngineDefaultIdleTorqueLimit : 312|8@1+ (1,-125) [-125|125] "%" Vector__XXX
 SG_ EngineDefaultTorqueLimit : 256|16@1+ (1,0) [0|64255] "Nm" Vector__XXX
 SG_ EngineMomentofInertia : 240|16@1+ (0.004,0) [0|257.02] "kg*(m*m)" Vector__XXX
 SG_ EnginePercentTorqueAtIdlePoint1 : 16|8@1+ (1,-125) [-125|125] "%" Vector__XXX
 SG_ EnginePercentTorqueAtPoint2 : 40|8@1+ (1,-125) [-125|125] "%" Vector__XXX
 SG_ EnginePercentTorqueAtPoint3 : 64|8@1+ (1,-125) [-125|125] "%" Vector__XXX
 SG_ EnginePercentTorqueAtPoint4 : 88|8@1+ (1,-125) [-125|125] "%" Vector__XXX
 SG_ EnginePercentTorqueAtPoint5 : 112|8@1+ (1,-125) [-125|125] "%" Vector__XXX
 SG_ EngineReferenceTorque : 152|16@1+ (1,0) [0|64255] "Nm" Vector__XXX
 SG_ EngineSpeedAtHighIdlePoint6 : 120|16@1+ (0.125,0) [0|8031.875] "rpm" Vector__XXX
 SG_ EngineSpeedAtIdlePoint1 : 0|16@1+ (0.125,0) [0|8031.875] "rpm" Vector__XXX
 SG_ EngineSpeedAtPoint2 : 24|16@1+ (0.125,0) [0|8031.875] "rpm" Vector__XXX
 SG_ EngineSpeedAtPoint3 : 48|16@1+ (0.125,0) [0|8031.875] "rpm" Vector__XXX
 SG_ EngineSpeedAtPoint4 : 72|16@1+ (0.125,0) [0|8031.875] "rpm" Vector__XXX
 SG_ EngineSpeedAtPoint5 : 96|16@1+ (0.125,0) [0|8031.875] "rpm" Vector__XXX
 SG_ EngnGnKpOfThEndspdGvrnr : 136|16@1+ (0.00078125,0) [0|50.2] "%/rpm" Vector__XXX
 SG_ EngnMxmmMmntrOvrrdSpdPnt7 : 168|16@1+ (0.125,0) [0|8031.875] "rpm" Vector__XXX
 SG_ EngnMxmmMmntrOvrrdTmLmt : 184|8@1+ (0.1,0) [0|25] "s" Vector__XXX
 SG_ EngnRqstdSpdCntrlRngLwrLmt : 192|8@1+ (10,0) [0|2500] "rpm" Vector__XXX
 SG_ EngnRqstdSpdCntrlRngUpprLmt : 200|8@1+ (10,0) [0|2500] "rpm" Vector__XXX
 SG_ EngnRqstdTrqCntrlRngLwrLmt : 208|8@1+ (1,-125) [-125|125] "%" Vector__XXX
 SG_ EngnRqstdTrqCntrlRngUpprLmt : 216|8@1+ (1,-125) [-125|125] "%" Vector__XXX
 SG_ ERqstdSpdCtRUppLtExtddR : 224|16@1+ (0.125,0) [0|8031.875] "rpm" Vector__XXX
 SG_ SupportTSC1ControlPurposeGroup1 : 280|8@1+ (1,0) [0|255] "" Vector__XXX
 SG_ SupportTSC1ControlPurposeGroup2 : 288|8@1+ (1,0) [0|255] "" Vector__XXX
 SG_ SupportTSC1ControlPurposeGroup3 : 296|8@1+ (1,0) [0|255] "" Vector__XXX
 SG_ SupportTSC1ControlPurposeGroup4 : 304|8@1+ (1,0) [0|255] "" Vector__XXX
 SG_ SupportVariableRateTSC1Message : 272|8@1+ (1,0) [0|255] "" Vector__XXX

BO_ 2566841598 SHUTDN: 8 Vector__XXX
 SG_ ACHighPressureFanSwitch : 16|2@1+ (1,0) [0|3] "" Vector__XXX
 SG_ ClntLvlEngnPrttnShtdwnStts : 60|2@1+ (1,0) [0|3] "" Vector__XXX
 SG_ EngineAirShutoffCommandStatus : 52|2@1+ (1,0) [0|3] "" Vector__XXX
 SG_ EngineAirShutoffStatus : 56|2@1+ (1,0) [0|3] "" Vector__XXX
 SG_ EngineAlarmAcknowledge : 48|2@1+ (1,0) [0|3] "" Vector__XXX
 SG_ EngineAlarmOutputCommandStatus : 50|2@1+ (1,0) [0|3] "" Vector__XXX
 SG_ EngineIdleShutdownTimerFunction : 14|2@1+ (1,0) [0|3] "" Vector__XXX
 SG_ EngineIdleShutdownTimerOverride : 4|2@1+ (1,0) [0|3] "" Vector__XXX
 SG_ EngineIdleShutdownTimerState : 6|2@1+ (1,0) [0|3] "" Vector__XXX
 SG_ EngineOilPressureSwitch : 62|2@1+ (1,0) [0|3] "" Vector__XXX
 SG_ EngineOverspeedTest : 54|2@1+ (1,0) [0|3] "" Vector__XXX
 SG_ EngineWaittoStartLamp : 24|2@1+ (1,0) [0|3] "" Vector__XXX
 SG_ EngnIdlShtdwnDrvrAlrtMd : 2|2@1+ (1,0) [0|3] "" Vector__XXX
 SG_ EngnIdlShtdwnhsShtdwnEngn : 0|2@1+ (1,0) [0|3] "" Vector__XXX
 SG_ EngnPrttnSstmApprhngShtdwn : 34|2@1+ (1,0) [0|3] "" Vector__XXX
 SG_ EngnPrttnSstmCnfgrtn : 46|2@1+ (1,0) [0|3] "" Vector__XXX
 SG_ EngnPrttnSstmhsShtdwnEngn : 32|2@1+ (1,0) [0|3] "" Vector__XXX
 SG_ EngnPrttnSstmTmrOvrrd : 36|2@1+ (1,0) [0|3] "" Vector__XXX
 SG_ EngnPrttnSstmTmrStt : 38|2@1+ (1,0) [0|3] "" Vector__XXX
 SG_ PTOShutdownhasShutdownEngine : 58|2@1+ (1,0) [0|3] "" Vector__XXX
 SG_ RefrigerantHighPressureSwitch : 20|2@1+ (1,0) [0|3] "" Vector__XXX
 SG_ RefrigerantLowPressureSwitch : 18|2@1+ (1,0) [0|3] "" Vector__XXX

BO_ 2566841854 HOURS: 8 Vector__XXX
 SG_ EngineTotalHoursofOperation : 0|32@1+ (0.05,0) [0|210554060.75] "h" Vector__XXX
 SG_ EngineTotalRevolutions : 32|32@1+ (1000,0) [0|4E+12] "r" Vector__XXX

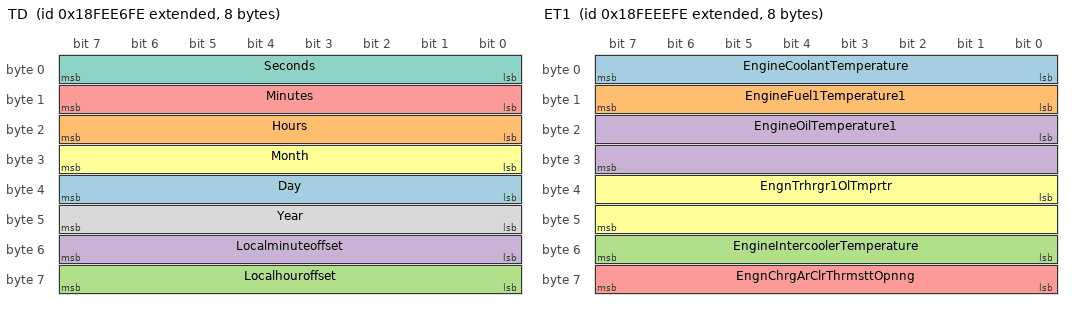
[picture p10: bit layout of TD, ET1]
BO_ 2566842110 TD: 8 Vector__XXX
 SG_ Day : 32|8@1+ (0.25,0) [0|62.5] "days" Vector__XXX
 SG_ Hours : 16|8@1+ (1,0) [0|250] "h" Vector__XXX
 SG_ Localhouroffset : 56|8@1+ (1,-125) [-125|125] "h" Vector__XXX
 SG_ Localminuteoffset : 48|8@1+ (1,-125) [-125|125] "min" Vector__XXX
 SG_ Minutes : 8|8@1+ (1,0) [0|250] "min" Vector__XXX
 SG_ Month : 24|8@1+ (1,0) [0|250] "months" Vector__XXX
 SG_ Seconds : 0|8@1+ (0.25,0) [0|62.5] "s" Vector__XXX
 SG_ Year : 40|8@1+ (1,1985) [1985|2235] "years" Vector__XXX

BO_ 2566842366 VH: 8 Vector__XXX
 SG_ TotalPowerTakeoffHours : 32|32@1+ (0.05,0) [0|210554060.75] "h" Vector__XXX
 SG_ TotalVehicleHours : 0|32@1+ (0.05,0) [0|210554060.75] "h" Vector__XXX

BO_ 2566842622 VDS: 8 Vector__XXX
 SG_ Altitude : 48|16@1+ (0.125,-2500) [-2500|5531.875] "m" Vector__XXX
 SG_ CompassBearing : 0|16@1+ (0.0078125,0) [0|501.99] "deg" Vector__XXX
 SG_ NavigationBasedVehicleSpeed : 16|16@1+ (0.00390625,0) [0|250.996] "km/h" Vector__XXX
 SG_ Pitch : 32|16@1+ (0.0078125,-200) [-200|301.99] "deg" Vector__XXX

BO_ 2566842878 LFC1: 8 Vector__XXX
 SG_ EngineTotalFuelUsed : 32|32@1+ (0.5,0) [0|2105540607.5] "l" Vector__XXX
 SG_ EngineTripFuel : 0|32@1+ (0.5,0) [0|2105540607.5] "l" Vector__XXX

BO_ 2566843134 VW: 8 Vector__XXX
 SG_ AxleLocation : 0|8@1+ (1,0) [0|255] "" Vector__XXX
 SG_ AxleWeight : 8|16@1+ (0.5,0) [0|32127.5] "kg" Vector__XXX
 SG_ CargoWeight : 40|16@1+ (2,0) [0|128510] "kg" Vector__XXX
 SG_ TrailerWeight : 24|16@1+ (2,0) [0|128510] "kg" Vector__XXX

BO_ 2566843390 CI: 8 Vector__XXX
 SG_ Make : 0|8@1+ (1,0) [0|255] "ASCII" Vector__XXX
 SG_ Model : 8|8@1+ (1,0) [0|255] "ASCII" Vector__XXX
 SG_ SerialNumber : 16|8@1+ (1,0) [0|255] "ASCII" Vector__XXX
 SG_ UnitNumberPowerUnit : 24|8@1+ (1,0) [0|255] "ASCII" Vector__XXX

BO_ 2566843646 VI: 8 Vector__XXX
 SG_ VehicleIdentificationNumber : 0|8@1+ (1,0) [0|255] "ASCII" Vector__XXX

BO_ 2566843902 CCSS: 8 Vector__XXX
 SG_ CruiseControlHighSetLimitSpeed : 8|8@1+ (1,0) [0|250] "km/h" Vector__XXX
 SG_ CruiseControlLowSetLimitSpeed : 16|8@1+ (1,0) [0|250] "km/h" Vector__XXX
 SG_ MaximumVehicleSpeedLimit : 0|8@1+ (1,0) [0|250] "km/h" Vector__XXX
 SG_ MxmmVhlSpdLmtHghRsltn : 24|16@1+ (0.00390625,0) [0|250.996] "km/h" Vector__XXX

BO_ 2566844158 ET1: 8 Vector__XXX
 SG_ EngineCoolantTemperature : 0|8@1+ (1,-40) [-40|210] "degC" Vector__XXX
 SG_ EngineFuel1Temperature1 : 8|8@1+ (1,-40) [-40|210] "degC" Vector__XXX
 SG_ EngineIntercoolerTemperature : 48|8@1+ (1,-40) [-40|210] "degC" Vector__XXX
 SG_ EngineOilTemperature1 : 16|16@1+ (0.03125,-273) [-273|1734.96875] "degC" Vector__XXX
 SG_ EngnChrgArClrThrmsttOpnng : 56|8@1+ (0.4,0) [0|100] "%" Vector__XXX
 SG_ EngnTrhrgr1OlTmprtr : 32|16@1+ (0.03125,-273) [-273|1734.96875] "degC" Vector__XXX

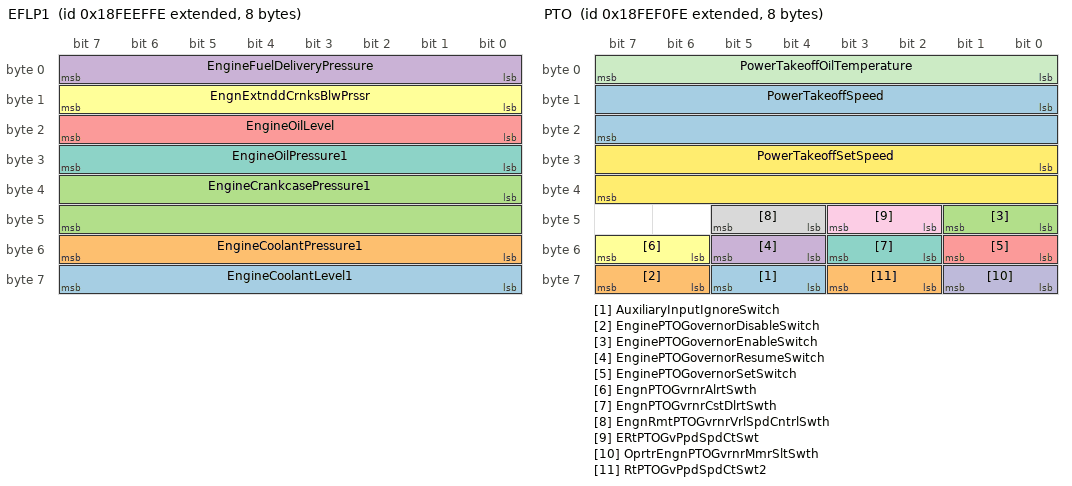
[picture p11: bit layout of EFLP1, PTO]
BO_ 2566844414 EFLP1: 8 Vector__XXX
 SG_ EngineCoolantLevel1 : 56|8@1+ (0.4,0) [0|100] "%" Vector__XXX
 SG_ EngineCoolantPressure1 : 48|8@1+ (2,0) [0|500] "kPa" Vector__XXX
 SG_ EngineCrankcasePressure1 : 32|16@1+ (0.0078125,-250) [-250|251.99] "kPa" Vector__XXX
 SG_ EngineFuelDeliveryPressure : 0|8@1+ (4,0) [0|1000] "kPa" Vector__XXX
 SG_ EngineOilLevel : 16|8@1+ (0.4,0) [0|100] "%" Vector__XXX
 SG_ EngnExtnddCrnksBlwPrssr : 8|8@1+ (0.05,0) [0|12.5] "kPa" Vector__XXX
 SG_ EngineOilPressure1 : 24|8@1+ (4,0) [0|1000] "kPa" Vector__XXX

BO_ 2566844670 PTO: 8 Vector__XXX
 SG_ AuxiliaryInputIgnoreSwitch : 60|2@1+ (1,0) [0|3] "" Vector__XXX
 SG_ EnginePTOGovernorDisableSwitch : 62|2@1+ (1,0) [0|3] "" Vector__XXX
 SG_ EnginePTOGovernorEnableSwitch : 40|2@1+ (1,0) [0|3] "" Vector__XXX
 SG_ EnginePTOGovernorResumeSwitch : 52|2@1+ (1,0) [0|3] "" Vector__XXX
 SG_ EnginePTOGovernorSetSwitch : 48|2@1+ (1,0) [0|3] "" Vector__XXX
 SG_ EngnPTOGvrnrAlrtSwth : 54|2@1+ (1,0) [0|3] "" Vector__XXX
 SG_ EngnPTOGvrnrCstDlrtSwth : 50|2@1+ (1,0) [0|3] "" Vector__XXX
 SG_ EngnRmtPTOGvrnrVrlSpdCntrlSwth : 44|2@1+ (1,0) [0|3] "" Vector__XXX
 SG_ ERtPTOGvPpdSpdCtSwt : 42|2@1+ (1,0) [0|3] "" Vector__XXX
 SG_ OprtrEngnPTOGvrnrMmrSltSwth : 56|2@1+ (1,0) [0|3] "" Vector__XXX
 SG_ PowerTakeoffOilTemperature : 0|8@1+ (1,-40) [-40|210] "degC" Vector__XXX
 SG_ PowerTakeoffSetSpeed : 24|16@1+ (0.125,0) [0|8031.875] "rpm" Vector__XXX
 SG_ PowerTakeoffSpeed : 8|16@1+ (0.125,0) [0|8031.875] "rpm" Vector__XXX
 SG_ RtPTOGvPpdSpdCtSwt2 : 58|2@1+ (1,0) [0|3] "" Vector__XXX

BO_ 2566844926 CCVS1: 8 Vector__XXX
 SG_ BrakeSwitch : 28|2@1+ (1,0) [0|3] "" Vector__XXX
 SG_ ClutchSwitch : 30|2@1+ (1,0) [0|3] "" Vector__XXX
 SG_ CrsCntrlCstDlrtSwth : 34|2@1+ (1,0) [0|3] "" Vector__XXX
 SG_ CruiseControlAccelerateSwitch : 38|2@1+ (1,0) [0|3] "" Vector__XXX
 SG_ CruiseControlActive : 24|2@1+ (1,0) [0|3] "" Vector__XXX
 SG_ CruiseControlEnableSwitch : 26|2@1+ (1,0) [0|3] "" Vector__XXX
 SG_ CruiseControlPauseSwitch : 4|2@1+ (1,0) [0|3] "" Vector__XXX
 SG_ CruiseControlResumeSwitch : 36|2@1+ (1,0) [0|3] "" Vector__XXX
 SG_ CruiseControlSetSpeed : 40|8@1+ (1,0) [0|250] "km/h" Vector__XXX
 SG_ CruiseControlSetSwitch : 32|2@1+ (1,0) [0|3] "" Vector__XXX
 SG_ CruiseControlStates : 53|3@1+ (1,0) [0|7] "" Vector__XXX
 SG_ EngineDiagnosticTestModeSwitch : 60|2@1+ (1,0) [0|3] "" Vector__XXX
 SG_ EngineIdleDecrementSwitch : 58|2@1+ (1,0) [0|3] "" Vector__XXX
 SG_ EngineIdleIncrementSwitch : 56|2@1+ (1,0) [0|3] "" Vector__XXX
 SG_ EngineShutdownOverrideSwitch : 62|2@1+ (1,0) [0|3] "" Vector__XXX
 SG_ ParkBrakeReleaseInhibitRequest : 6|2@1+ (1,0) [0|3] "" Vector__XXX
 SG_ ParkingBrakeSwitch : 2|2@1+ (1,0) [0|3] "" Vector__XXX
 SG_ PTOGovernorState : 48|5@1+ (1,0) [0|31] "" Vector__XXX
 SG_ TwoSpeedAxleSwitch : 0|2@1+ (1,0) [0|3] "" Vector__XXX
 SG_ WheelBasedVehicleSpeed : 8|16@1+ (0.00390625,0) [0|250.996] "km/h" Vector__XXX

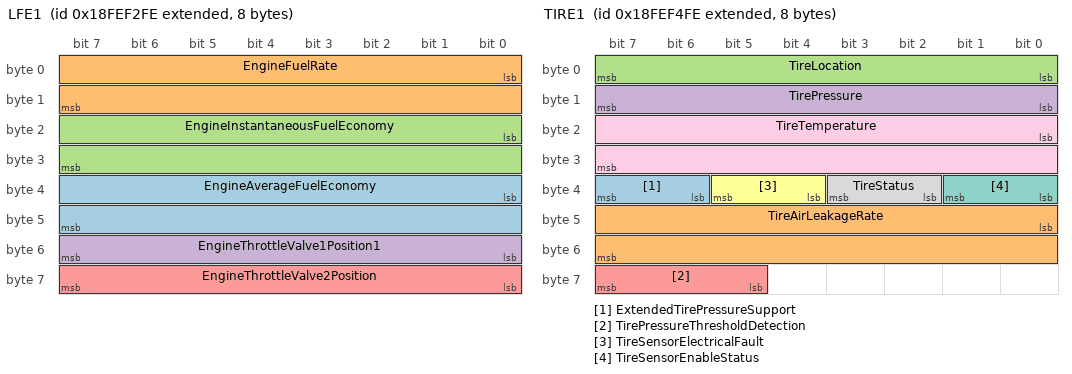
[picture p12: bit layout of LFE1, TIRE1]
BO_ 2566845182 LFE1: 8 Vector__XXX
 SG_ EngineAverageFuelEconomy : 32|16@1+ (0.001953125,0) [0|125.498046875] "km/L" Vector__XXX
 SG_ EngineFuelRate : 0|16@1+ (0.05,0) [0|3212.75] "l/h" Vector__XXX
 SG_ EngineInstantaneousFuelEconomy : 16|16@1+ (0.001953125,0) [0|125.498046875] "km/L" Vector__XXX
 SG_ EngineThrottleValve1Position1 : 48|8@1+ (0.4,0) [0|100] "%" Vector__XXX
 SG_ EngineThrottleValve2Position : 56|8@1+ (0.4,0) [0|100] "%" Vector__XXX

BO_ 2566845438 VP1: 8 Vector__XXX
 SG_ Latitude : 0|32@1+ (0.0000001,-210) [-210|211.1081215] "deg" Vector__XXX
 SG_ Longitude : 32|32@1+ (0.0000001,-210) [-210|211.1081215] "deg" Vector__XXX

BO_ 2566845694 TIRE1: 8 Vector__XXX
 SG_ ExtendedTirePressureSupport : 38|2@1+ (1,0) [0|3] "" Vector__XXX
 SG_ TireAirLeakageRate : 40|16@1+ (0.1,0) [0|6425.5] "Pa/s" Vector__XXX
 SG_ TireLocation : 0|8@1+ (1,0) [0|255] "" Vector__XXX
 SG_ TirePressure : 8|8@1+ (4,0) [0|1000] "kPa" Vector__XXX
 SG_ TirePressureThresholdDetection : 61|3@1+ (1,0) [0|7] "" Vector__XXX
 SG_ TireSensorElectricalFault : 36|2@1+ (1,0) [0|3] "" Vector__XXX
 SG_ TireSensorEnableStatus : 32|2@1+ (1,0) [0|3] "" Vector__XXX
 SG_ TireStatus : 34|2@1+ (1,0) [0|3] "" Vector__XXX
 SG_ TireTemperature : 16|16@1+ (0.03125,-273) [-273|1734.96875] "degC" Vector__XXX

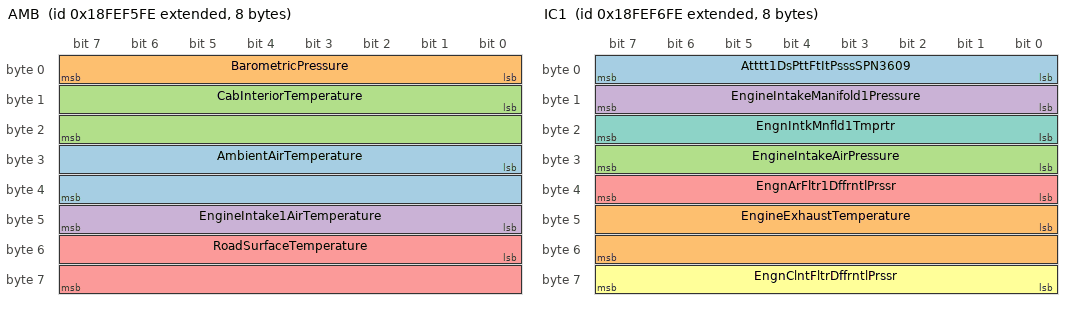
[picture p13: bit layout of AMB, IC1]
BO_ 2566845950 AMB: 8 Vector__XXX
 SG_ AmbientAirTemperature : 24|16@1+ (0.03125,-273) [-273|1734.96875] "degC" Vector__XXX
 SG_ BarometricPressure : 0|8@1+ (0.5,0) [0|125] "kPa" Vector__XXX
 SG_ CabInteriorTemperature : 8|16@1+ (0.03125,-273) [-273|1734.96875] "degC" Vector__XXX
 SG_ EngineIntake1AirTemperature : 40|8@1+ (1,-40) [-40|210] "degC" Vector__XXX
 SG_ RoadSurfaceTemperature : 48|16@1+ (0.03125,-273) [-273|1734.96875] "degC" Vector__XXX

BO_ 2566846206 IC1: 8 Vector__XXX
 SG_ Atttt1DsPttFtItPsssSPN3609 : 0|8@1+ (0.5,0) [0|125] "kPa" Vector__XXX
 SG_ EngineExhaustTemperature : 40|16@1+ (0.03125,-273) [-273|1734.96875] "degC" Vector__XXX
 SG_ EngineIntakeAirPressure : 24|8@1+ (2,0) [0|500] "kPa" Vector__XXX
 SG_ EngineIntakeManifold1Pressure : 8|8@1+ (2,0) [0|500] "kPa" Vector__XXX
 SG_ EngnArFltr1DffrntlPrssr : 32|8@1+ (0.05,0) [0|12.5] "kPa" Vector__XXX
 SG_ EngnClntFltrDffrntlPrssr : 56|8@1+ (0.5,0) [0|125] "kPa" Vector__XXX
 SG_ EngnIntkMnfld1Tmprtr : 16|8@1+ (1,-40) [-40|210] "degC" Vector__XXX

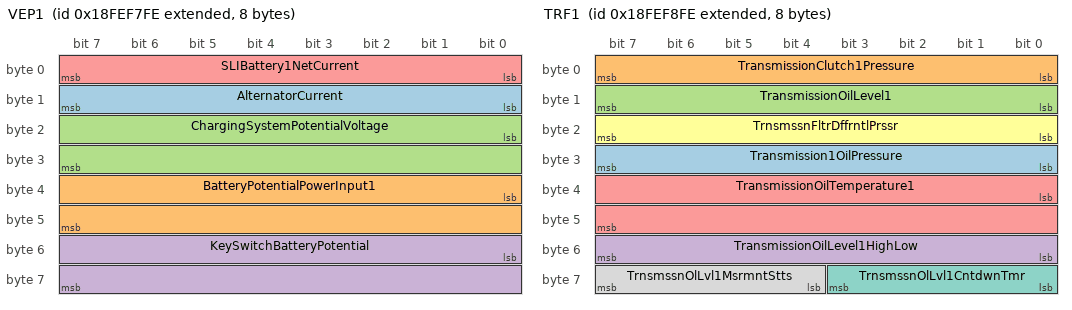
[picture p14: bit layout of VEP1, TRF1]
BO_ 2566846462 VEP1: 8 Vector__XXX
 SG_ AlternatorCurrent : 8|8@1+ (1,0) [0|250] "A" Vector__XXX
 SG_ BatteryPotentialPowerInput1 : 32|16@1+ (0.05,0) [0|3212.75] "V" Vector__XXX
 SG_ ChargingSystemPotentialVoltage : 16|16@1+ (0.05,0) [0|3212.75] "V" Vector__XXX
 SG_ KeySwitchBatteryPotential : 48|16@1+ (0.05,0) [0|3212.75] "V" Vector__XXX
 SG_ SLIBattery1NetCurrent : 0|8@1+ (1,-125) [-125|125] "A" Vector__XXX

BO_ 2566846718 TRF1: 8 Vector__XXX
 SG_ Transmission1OilPressure : 24|8@1+ (16,0) [0|4000] "kPa" Vector__XXX
 SG_ TransmissionClutch1Pressure : 0|8@1+ (16,0) [0|4000] "kPa" Vector__XXX
 SG_ TransmissionOilLevel1 : 8|8@1+ (0.4,0) [0|100] "%" Vector__XXX
 SG_ TransmissionOilLevel1HighLow : 48|8@1+ (0.5,-62.5) [-62.5|62.5] "l" Vector__XXX
 SG_ TransmissionOilTemperature1 : 32|16@1+ (0.03125,-273) [-273|1734.96875] "degC" Vector__XXX
 SG_ TrnsmssnFltrDffrntlPrssr : 16|8@1+ (2,0) [0|500] "kPa" Vector__XXX
 SG_ TrnsmssnOlLvl1CntdwnTmr : 56|4@1+ (1,0) [0|15] "" Vector__XXX
 SG_ TrnsmssnOlLvl1MsrmntStts : 60|4@1+ (1,0) [0|15] "" Vector__XXX

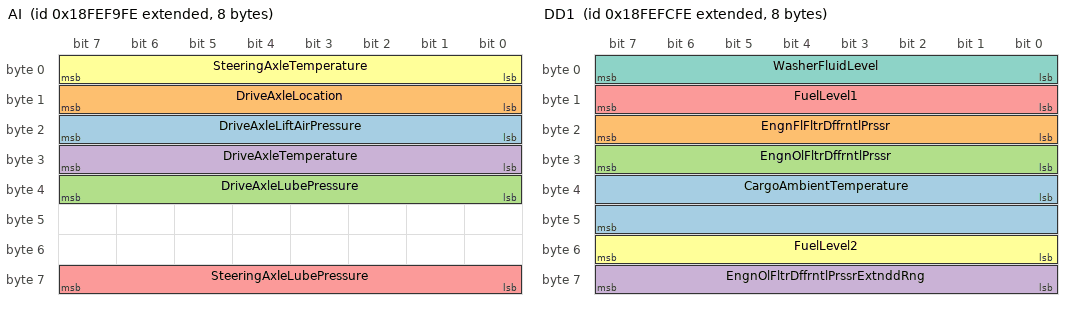
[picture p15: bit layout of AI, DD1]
BO_ 2566846974 AI: 8 Vector__XXX
 SG_ DriveAxleLiftAirPressure : 16|8@1+ (4,0) [0|1000] "kPa" Vector__XXX
 SG_ DriveAxleLocation : 8|8@1+ (1,0) [0|255] "" Vector__XXX
 SG_ DriveAxleLubePressure : 32|8@1+ (4,0) [0|1000] "kPa" Vector__XXX
 SG_ DriveAxleTemperature : 24|8@1+ (1,-40) [-40|210] "degC" Vector__XXX
 SG_ SteeringAxleLubePressure : 56|8@1+ (4,0) [0|1000] "kPa" Vector__XXX
 SG_ SteeringAxleTemperature : 0|8@1+ (1,-40) [-40|210] "degC" Vector__XXX

BO_ 2566847230 B1: 8 Vector__XXX
 SG_ BrakeApplicationPressure : 0|8@1+ (4,0) [0|1000] "kPa" Vector__XXX
 SG_ BrakePrimaryPressure : 8|8@1+ (4,0) [0|1000] "kPa" Vector__XXX
 SG_ BrakeSecondaryPressure : 16|8@1+ (4,0) [0|1000] "kPa" Vector__XXX
 SG_ ParkBrakeReleaseInhibitStatus : 28|2@1+ (1,0) [0|3] "" Vector__XXX
 SG_ ParkingBrakeActuator : 24|2@1+ (1,0) [0|3] "" Vector__XXX
 SG_ ParkingBrakeRedWarningSignal : 26|2@1+ (1,0) [0|3] "" Vector__XXX

BO_ 2566847486 RF: 8 Vector__XXX
 SG_ DrvlnRtrdrOvrhtIndtr : 16|2@1+ (1,0) [0|3] "" Vector__XXX
 SG_ HydraulicRetarderOilTemperature : 8|8@1+ (1,-40) [-40|210] "degC" Vector__XXX
 SG_ HydraulicRetarderPressure : 0|8@1+ (16,0) [0|4000] "kPa" Vector__XXX
 SG_ RtrdrClntOtltTmprtr : 24|8@1+ (1,-40) [-40|210] "degC" Vector__XXX

BO_ 2566847742 DD1: 8 Vector__XXX
 SG_ CargoAmbientTemperature : 32|16@1+ (0.03125,-273) [-273|1734.96875] "degC" Vector__XXX
 SG_ EngnFlFltrDffrntlPrssr : 16|8@1+ (2,0) [0|500] "kPa" Vector__XXX
 SG_ EngnOlFltrDffrntlPrssr : 24|8@1+ (0.5,0) [0|125] "kPa" Vector__XXX
 SG_ EngnOlFltrDffrntlPrssrExtnddRng : 56|8@1+ (5,0) [0|1250] "kPa" Vector__XXX
 SG_ FuelLevel1 : 8|8@1+ (0.4,0) [0|100] "%" Vector__XXX
 SG_ FuelLevel2 : 48|8@1+ (0.4,0) [0|100] "%" Vector__XXX
 SG_ WasherFluidLevel : 0|8@1+ (0.4,0) [0|100] "%" Vector__XXX

BO_ 2566847998 AF1: 8 Vector__XXX
 SG_ EngineBlowerBypassValvePosition : 0|8@1+ (0.4,0) [0|100] "%" Vector__XXX
 SG_ EngineGaseousFuelVentPressure : 24|16@1+ (0.5,0) [0|32127.5] "kPa" Vector__XXX
 SG_ EngnGssFlPrssrRgltrIntkPrssr : 48|16@1+ (1,0) [0|64255] "kPa" Vector__XXX
 SG_ EngnGssFlSpplPrssr1 : 8|16@1+ (0.5,0) [0|32127.5] "kPa" Vector__XXX
 SG_ LNGVprzrClntOtltTmprtr : 40|8@1+ (1,-40) [-40|210] "degC" Vector__XXX

BO_ 2566848254 AWPP: 8 Vector__XXX
 SG_ AuxiliaryPumpPressure : 0|8@1+ (16,0) [0|4000] "kPa" Vector__XXX

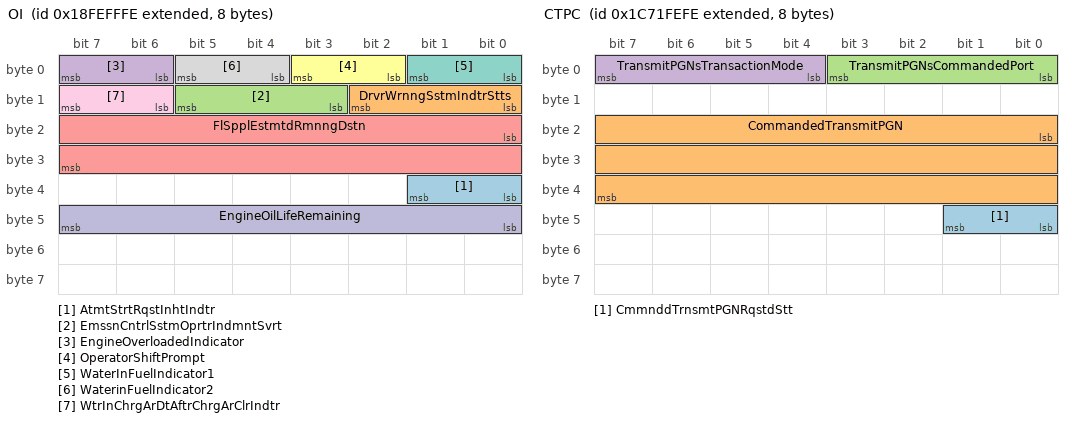
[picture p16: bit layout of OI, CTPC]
BO_ 2566848510 OI: 8 Vector__XXX
 SG_ AtmtStrtRqstInhtIndtr : 32|2@1+ (1,0) [0|3] "" Vector__XXX
 SG_ DrvrWrnngSstmIndtrStts : 8|3@1+ (1,0) [0|7] "" Vector__XXX
 SG_ EmssnCntrlSstmOprtrIndmntSvrt : 11|3@1+ (1,0) [0|7] "" Vector__XXX
 SG_ EngineOverloadedIndicator : 6|2@1+ (1,0) [0|3] "" Vector__XXX
 SG_ FlSpplEstmtdRmnngDstn : 16|16@1+ (1,0) [0|64255] "km" Vector__XXX
 SG_ OperatorShiftPrompt : 2|2@1+ (1,0) [0|3] "" Vector__XXX
 SG_ WaterInFuelIndicator1 : 0|2@1+ (1,0) [0|3] "" Vector__XXX
 SG_ WaterinFuelIndicator2 : 4|2@1+ (1,0) [0|3] "" Vector__XXX
 SG_ WtrInChrgArDtAftrChrgArClrIndtr : 14|2@1+ (1,0) [0|3] "" Vector__XXX
 SG_ EngineOilLifeRemaining : 40|8@1+ (0.4,0) [0|100] "%" Vector__XXX

BO_ 2624716542 CTPC: 8 Vector__XXX
 SG_ CmmnddTrnsmtPGNRqstdStt : 40|2@1+ (1,0) [0|3] "" Vector__XXX
 SG_ CommandedTransmitPGN : 16|24@1+ (1,0) [0|1.67772E+07] "binary" Vector__XXX
 SG_ TransmitPGNsCommandedPort : 0|4@1+ (1,0) [0|15] "" Vector__XXX
 SG_ TransmitPGNsTransactionMode : 4|4@1+ (1,0) [0|15] "" Vector__XXX

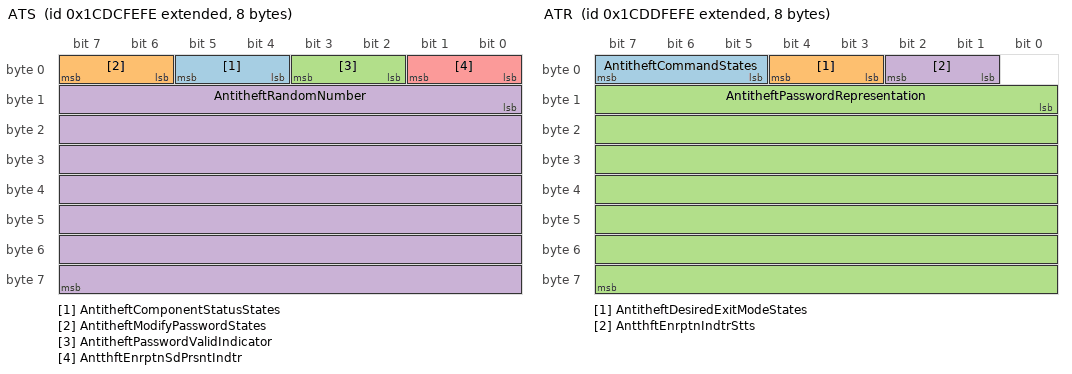
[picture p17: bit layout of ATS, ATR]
BO_ 2631728894 ATS: 8 Vector__XXX
 SG_ AntitheftComponentStatusStates : 4|2@1+ (1,0) [0|3] "" Vector__XXX
 SG_ AntitheftModifyPasswordStates : 6|2@1+ (1,0) [0|3] "" Vector__XXX
 SG_ AntitheftPasswordValidIndicator : 2|2@1+ (1,0) [0|3] "" Vector__XXX
 SG_ AntitheftRandomNumber : 8|56@1+ (1,0) [0|255] "ASCII" Vector__XXX
 SG_ AntthftEnrptnSdPrsntIndtr : 0|2@1+ (1,0) [0|3] "" Vector__XXX

BO_ 2631794430 ATR: 8 Vector__XXX
 SG_ AntitheftCommandStates : 5|3@1+ (1,0) [0|7] "" Vector__XXX
 SG_ AntitheftDesiredExitModeStates : 3|2@1+ (1,0) [0|3] "" Vector__XXX
 SG_ AntitheftPasswordRepresentation : 8|56@1+ (1,0) [0|255] "ASCII" Vector__XXX
 SG_ AntthftEnrptnIndtrStts : 1|2@1+ (1,0) [0|3] "" Vector__XXX

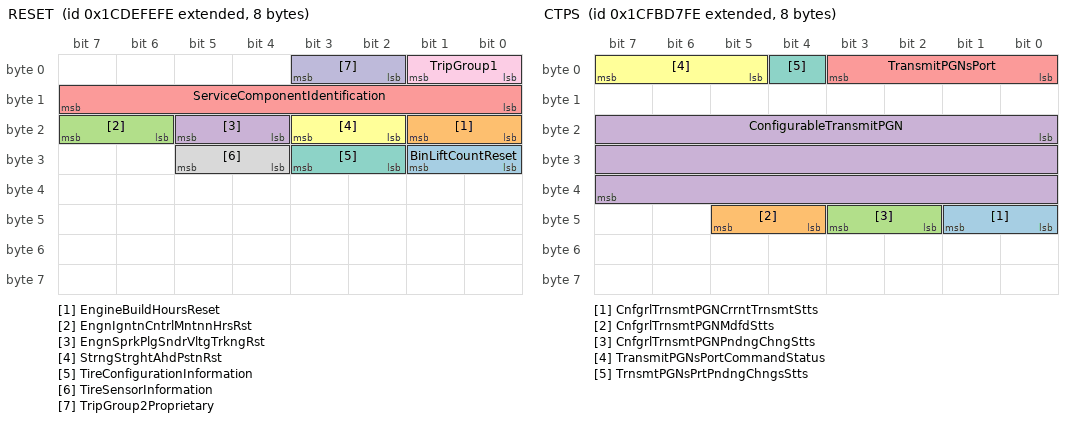
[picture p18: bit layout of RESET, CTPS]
BO_ 2631859966 RESET: 8 Vector__XXX
 SG_ BinLiftCountReset : 24|2@1+ (1,0) [0|3] "" Vector__XXX
 SG_ EngineBuildHoursReset : 16|2@1+ (1,0) [0|3] "" Vector__XXX
 SG_ EngnIgntnCntrlMntnnHrsRst : 22|2@1+ (1,0) [0|3] "" Vector__XXX
 SG_ EngnSprkPlgSndrVltgTrkngRst : 20|2@1+ (1,0) [0|3] "" Vector__XXX
 SG_ ServiceComponentIdentification : 8|8@1+ (1,0) [0|250] "ID" Vector__XXX
 SG_ StrngStrghtAhdPstnRst : 18|2@1+ (1,0) [0|3] "" Vector__XXX
 SG_ TireConfigurationInformation : 26|2@1+ (1,0) [0|3] "" Vector__XXX
 SG_ TireSensorInformation : 28|2@1+ (1,0) [0|3] "" Vector__XXX
 SG_ TripGroup1 : 0|2@1+ (1,0) [0|3] "" Vector__XXX
 SG_ TripGroup2Proprietary : 2|2@1+ (1,0) [0|3] "" Vector__XXX

BO_ 2633734398 EO2: 8 Vector__XXX
 SG_ EngineActualExhaust2Oxygen : 0|16@1+ (0.0025,0) [0|160.6375] "%" Vector__XXX

BO_ 2633749502 WSPT: 16 Vector__XXX
 SG_ WellStimulationPumpCycleCount : 96|32@1+ (1,0) [0|4.21108E+09] "count" Vector__XXX
 SG_ WellStimulationPumpWorkingHours : 64|32@1+ (1,0) [0|4.21108E+09] "s" Vector__XXX
 SG_ WllStmltnPmpFldEndWrkngHrs : 0|32@1+ (1,0) [0|4.21108E+09] "s" Vector__XXX
 SG_ WllStmltnPmpPwrEndWrkngHrs : 32|32@1+ (1,0) [0|4.21108E+09] "s" Vector__XXX

BO_ 2633749758 WSPC: 8 Vector__XXX
 SG_ WellStimulationPumpGearRatio : 32|16@1+ (0.001,0) [0|64.255] "Ratio" Vector__XXX
 SG_ WellStimulationPumpRatedSpeed : 48|16@1+ (0.125,0) [0|8031.875] "rpm" Vector__XXX
 SG_ WellStimulationPumpStrokeLength : 16|16@1+ (1,0) [0|64255] "mm" Vector__XXX
 SG_ WllStmltnPmpPlngrDmtr : 0|16@1+ (1,0) [0|64255] "mm" Vector__XXX

BO_ 2633750526 CTPS: 8 Vector__XXX
 SG_ CnfgrlTrnsmtPGNCrrntTrnsmtStts : 40|2@1+ (1,0) [0|3] "" Vector__XXX
 SG_ CnfgrlTrnsmtPGNMdfdStts : 44|2@1+ (1,0) [0|3] "" Vector__XXX
 SG_ CnfgrlTrnsmtPGNPndngChngStts : 42|2@1+ (1,0) [0|3] "" Vector__XXX
 SG_ ConfigurableTransmitPGN : 16|24@1+ (1,0) [0|1.67772E+07] "binary" Vector__XXX
 SG_ TransmitPGNsPort : 0|4@1+ (1,0) [0|15] "" Vector__XXX
 SG_ TransmitPGNsPortCommandStatus : 5|3@1+ (1,0) [0|7] "" Vector__XXX
 SG_ TrnsmtPGNsPrtPndngChngsStts : 4|1@1+ (1,0) [0|1] "" Vector__XXX

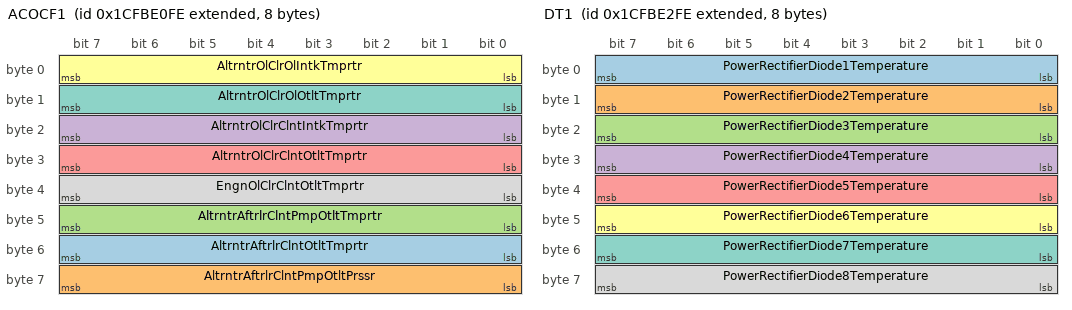
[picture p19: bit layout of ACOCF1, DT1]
BO_ 2633752830 ACOCF1: 8 Vector__XXX
 SG_ AltrntrAftrlrClntOtltTmprtr : 48|8@1+ (1,-40) [-40|210] "degC" Vector__XXX
 SG_ AltrntrAftrlrClntPmpOtltPrssr : 56|8@1+ (2,0) [0|500] "kPa" Vector__XXX
 SG_ AltrntrAftrlrClntPmpOtltTmprtr : 40|8@1+ (1,-40) [-40|210] "degC" Vector__XXX
 SG_ AltrntrOlClrClntIntkTmprtr : 16|8@1+ (1,-40) [-40|210] "degC" Vector__XXX
 SG_ AltrntrOlClrClntOtltTmprtr : 24|8@1+ (1,-40) [-40|210] "degC" Vector__XXX
 SG_ AltrntrOlClrOlIntkTmprtr : 0|8@1+ (1,-40) [-40|210] "degC" Vector__XXX
 SG_ AltrntrOlClrOlOtltTmprtr : 8|8@1+ (1,-40) [-40|210] "degC" Vector__XXX
 SG_ EngnOlClrClntOtltTmprtr : 32|8@1+ (1,-40) [-40|210] "degC" Vector__XXX

BO_ 2633753086 DT2: 8 Vector__XXX
 SG_ PowerRectifierDiode9Temperature : 0|8@1+ (1,-40) [-40|210] "degC" Vector__XXX
 SG_ PwrRtfrDd10Tmprtr : 8|8@1+ (1,-40) [-40|210] "degC" Vector__XXX
 SG_ PwrRtfrDd11Tmprtr : 16|8@1+ (1,-40) [-40|210] "degC" Vector__XXX
 SG_ PwrRtfrDd12Tmprtr : 24|8@1+ (1,-40) [-40|210] "degC" Vector__XXX

BO_ 2633753342 DT1: 8 Vector__XXX
 SG_ PowerRectifierDiode1Temperature : 0|8@1+ (1,-40) [-40|210] "degC" Vector__XXX
 SG_ PowerRectifierDiode2Temperature : 8|8@1+ (1,-40) [-40|210] "degC" Vector__XXX
 SG_ PowerRectifierDiode3Temperature : 16|8@1+ (1,-40) [-40|210] "degC" Vector__XXX
 SG_ PowerRectifierDiode4Temperature : 24|8@1+ (1,-40) [-40|210] "degC" Vector__XXX
 SG_ PowerRectifierDiode5Temperature : 32|8@1+ (1,-40) [-40|210] "degC" Vector__XXX
 SG_ PowerRectifierDiode6Temperature : 40|8@1+ (1,-40) [-40|210] "degC" Vector__XXX
 SG_ PowerRectifierDiode7Temperature : 48|8@1+ (1,-40) [-40|210] "degC" Vector__XXX
 SG_ PowerRectifierDiode8Temperature : 56|8@1+ (1,-40) [-40|210] "degC" Vector__XXX

CM_ BO_ 2566785022 "Exhaust Temperature";
CM_ SG_ 2566785022 EngnExhstMnfldBnk1Tmprtr1 "Temperature of combustion byproducts measured in engine bank 1 (left bank) exhaust manifold.  Single manifold engines should use exhaust temperature (SPN 173).…";
CM_ SG_ 2566785022 EngnExhstMnfldBnk1Tmprtr2 "Temperature of combustion byproducts measured by a second sensor in engine bank 1 (left bank) exhaust manifold. This should be used for the sensor toward the re…";
CM_ SG_ 2566785022 EngnExhstMnfldBnk2Tmprtr1 "Temperature of combustion byproducts measured in engine bank 2 (right bank) exhaust manifold.  Single manifold engines should use exhaust temperature (SPN 173).…";
CM_ SG_ 2566785022 EngnExhstMnfldBnk2Tmprtr2 "Temperature of combustion byproducts measured by a second sensor in engine bank 2 (right bank) exhaust manifold. This should be used for the sensor toward the r…";
CM_ BO_ 2566799614 "Lighting Data";
CM_ SG_ 2566799614 AlternateBeamHeadLightData "This parameter provides measured data from the tractor alternate beam head light lamps. 00b = De-activated01b = Activated10b = Fault Detected11b = Not Available…";
CM_ SG_ 2566799614 BackUpLightandAlarmHorn "This parameter provides measured data from the back up lights and/ or associated alarm.00b = De-activated01b = Activated10b = Fault Detected11b = Not Available…";
CM_ SG_ 2566799614 CenterStopLight "This parameter provides measured data from the tractor and attached implement center stop lights.00b = De-activated01b = Activated10b = Fault Detected11b = Not …";
CM_ SG_ 2566799614 HighBeamHeadLightData "This parameter provides measured data from the tractor high beam head light lamps. 00b = De-activated01b = Activated10b = Fault Detected11b = Not Available…";
CM_ SG_ 2566799614 ImplementClearanceLight "This parameter provides measured data from an attached implement high mounted clearance lights.00b = De-activated01b = Activated10b = Fault Detected11b = Not Av…";
CM_ SG_ 2566799614 ImplementLeftFacingWorkLight "This parameter provides measured data from the left facing work lights toward the left end of the implement.00b = De-activated01b = Activated10b = Fault Detecte…";
CM_ SG_ 2566799614 ImplementLeftForwardWorkLight "This parameter provides measured data from the work lights mounted on an implement to illuminate the forward left end of the implement.00b = De-activate01b = Ac…";
CM_ SG_ 2566799614 ImplementMarkerLight "This parameter provides measured data from an attached implement marker lights, including front position lights, rear tail lights, side running lights, license …";
CM_ SG_ 2566799614 ImplementOEMOption1Light "This parameter provides measured data from the implement OEM option 1 light.00b = De-activated01b = Activated10b = Fault Detected11b = Not Available…";
CM_ SG_ 2566799614 ImplementOEMOption2Light "This parameter provides measured data from the implement OEM option 2 light.00b = De-activated01b = Activated10b = Fault Detected11b = Not Available…";
CM_ SG_ 2566799614 ImplementRearWorkLight "This parameter provides measured data from the implement rear work lamps.00b = De-activated01b = Activated10b = Fault Detected11b = Not Available…";
CM_ SG_ 2566799614 ImplementRightFacingWorkLight "This parameter provides measured data from the work lights mounted on an implement to illuminate beyond right end of the implement.00b = De-activated01b = Activ…";
CM_ SG_ 2566799614 ImplementRightForwardWorkLight "This parameter provides measured data from the forward facing work lights toward the right end of the implement.00b = De-activated01b = Activated10b = Fault Det…";
CM_ SG_ 2566799614 LeftStopLight "This parameter provides measured data from the tractor and attached implement left stop lights.00b = De-activated01b = Activated10b = Fault Detected11b = Not Av…";
CM_ SG_ 2566799614 LeftTurnSignalLights "This parameter provides measured data from the tractor and attached implement left turn signal lights.00b = De-activated01b = Activated10b = Fault Detected11b =…";
CM_ SG_ 2566799614 LowBeamHeadLightData "This parameter provides measured data from the tractor low beam head light lamps. 00b = De-activated01b = Activated10b = Fault Detected11b = Not Available…";
CM_ SG_ 2566799614 RearFogLights "This parameter provides measured data from the tractor and/or implement rear fog lights.00b = De-activated01b = Activated10b = Fault Detected11b = Not Available…";
CM_ SG_ 2566799614 RightStopLight "This parameter provides measured data from the tractor and attached implement right stop lights.00b = De-activated01b = Activated10b = Fault Detected11b = Not A…";
CM_ SG_ 2566799614 RightTurnSignalLights "This parameter provides measured data from the tractor and attached implement right turn signal lights.00b = De-activated01b = Activated10b = Fault Detected11b …";
CM_ SG_ 2566799614 RotatingBeaconLight "This parameter provides measured data from the beacon light on tractor or attached implements.00b = De-activated01b = Activated10b = Fault Detected11b = Not Ava…";
CM_ SG_ 2566799614 RunningLight "This parameter provides measured data from the vehicle's running lights.00b = De-activated01b = Activated10b = Fault Detected11b = Not Available…";
CM_ SG_ 2566799614 TractorClearanceLight "This parameter provides measured data from the tractor high mounted clearance and center ID lights.00b = De-activated01b = Activated10b = Fault Detected11b = No…";
CM_ SG_ 2566799614 TractorFrontFogLights "This parameter provides measured data from the tractor front fog lights.00b = De-activated01b = Activated10b = Fault Detected11b = Not Available…";
CM_ SG_ 2566799614 TractorMarkerLight "This parameter provides measured data from the tractor and attached implement marker lights, including front position lights, rear tail lights, side running lig…";
CM_ SG_ 2566799614 TractorRearLowMountedWorkLights "This parameter provides measured data from the tractor rear low mounted work lights.00b = De-activated01b = Activated10b = Fault Detected11b = Not Available…";
CM_ SG_ 2566799614 TractorSideLowMountedWorkLights "This parameter provides measured data from the tractor side low mounted work lights. 00b = De-activated01b = Activated10b = Fault Detected11b = Not Available…";
CM_ SG_ 2566799614 TrtrFrntHghMntdWrkLghts "This parameter provides measured data from the tractor front high mounted work lights. 00b = De-activated01b = Activated10b = Fault Detected11b = Not Available…";
CM_ SG_ 2566799614 TrtrFrntLwMntdWrkLghts "This parameter provides measured data from the tractor front low mounted work lights. 00b = De-activated01b = Activated10b = Fault Detected11b = Not Available…";
CM_ SG_ 2566799614 TrtrRrHghMntdWrkLghts "This parameter provides measured data from the tractor rear high mounted work lights. 00b = De-activated01b = Activated10b = Fault Detected11b = Not Available…";
CM_ SG_ 2566799614 TrtrSdHghMntdWrkLghts "This parameter provides measured data from the tractor side high mounted work lights. 00b = De-activated01b = Activated10b = Fault Detected11b = Not Available…";
CM_ SG_ 2566799614 TrtrUndrsdMntdWrkLghts "This parameter provides measured data from the tractor underside mounted work lights. 00b = De-activated01b = Activated10b = Fault Detected11b = Not Available…";
CM_ BO_ 2566802174 "Electronic Transmission Controller 7";
CM_ SG_ 2566802174 ActiveShiftConsoleIndicator "Signal from transmission control unit indicating which shift console (primary or secondary) it currently considers as the active shift selector input.00b = Prim…";
CM_ SG_ 2566802174 TransmissionEngineCrankEnable "State signal from the transmission indicating if the transmission's status is such that engine cranking is allowed (i.e.  at a minimum, transmission is in neutr…";
CM_ SG_ 2566802174 TransmissionManualModeIndicator "This parameter indicates if the operator has selected a Manual Mode of the transmission. When a Manual Mode is active, the operator has directly and intentional…";
CM_ SG_ 2566802174 TransmissionMode10Indicator "Indicates that the transmission is operating under transmission mode 10 (SPN 6570) as commanded via the TC2 message (PGN 3328). The definition of the transmissi…";
CM_ SG_ 2566802174 TransmissionMode1Indicator "This state signal is the transmission's indication that it is operating under transmission mode 1 (SPN 1852) as commanded via the TC1 message (PGN 256).  The de…";
CM_ SG_ 2566802174 TransmissionMode2Indicator "This state signal is the transmission's indication that it is operating under transmission mode 2 (SPN 1853) as commanded via the TC1 message (PGN 256).  The de…";
CM_ SG_ 2566802174 TransmissionMode3Indicator "This state signal is the transmission's indication that it is operating under transmission mode 3 (SPN 1854) as commanded via the TC1 message (PGN 256).  The de…";
CM_ SG_ 2566802174 TransmissionMode4Indicator "This state signal is the transmission's indication that it is operating under transmission mode 4 (SPN 1855) as commanded via the TC1 message (PGN 256).  The de…";
CM_ SG_ 2566802174 TransmissionMode5Indicator "This state signal is the transmission's indication that it is operating under transmission mode 5 (SPN 4246) as commanded via the TC1 message (PGN 256).  The de…";
CM_ SG_ 2566802174 TransmissionMode6Indicator "This state signal is the transmission's indication that it is operating under transmission mode 6 (SPN 4247) as commanded via the TC1 message (PGN 256).  The de…";
CM_ SG_ 2566802174 TransmissionMode7Indicator "This state signal is the transmission's indication that it is operating under transmission mode 7 (SPN 4248) as commanded via the TC1 message (PGN 256).  The de…";
CM_ SG_ 2566802174 TransmissionMode8Indicator "This state signal is the transmission's indication that it is operating under transmission mode 8 (SPN 4249) as commanded via the TC1 message (PGN 256).  The de…";
CM_ SG_ 2566802174 TransmissionMode9Indicator "Indicates that the transmission is operating under transmission mode 9 (SPN 6569) as commanded via the TC2 message (PGN 3328). The definition of the transmissio…";
CM_ SG_ 2566802174 TransmissionServiceIndicator "Signal from transmission indicating that some aspect of the gearbox requires servicing, such as the oil, filter, clutch(es) or other component.00b = Transmissio…";
CM_ SG_ 2566802174 TransmissionWarningIndicator "Signal from transmission indicating that some aspect of its operation is not functioning correctly, and as a result, transmission operation may be altered or re…";
CM_ SG_ 2566802174 TrnsmssnArSpplPrssrIndtr "Indicates whether transmission air supply is sufficient000b = Normal Pressure Range - The transmission supply air pressure is within the normal operational rang…";
CM_ SG_ 2566802174 TrnsmssnAtNtrlMnlRtrnStt "Indicates the transmission response to a Neutral request from SPN 7695 [Transmission Auto-Neutral (Manual Return) Request] or other vehicle input configured for…";
CM_ SG_ 2566802174 TrnsmssnCrrntRngDsplBlnkStt "State signal indicating a transmission request for the display of the Transmission Current Range parameter (SPN 163) to be blanked or not blanked.  The 'Transmi…";
CM_ SG_ 2566802174 TrnsmssnRdfrBrkRls "This parameter indicates that enough torque / motive force is available at the transmission output shaft to release all the brakes without a risk of unintention…";
CM_ SG_ 2566802174 TrnsmssnRqstdGrFdk "Feedback of the SPN 525 Transmission Requested Gear input as received from the shift selector, ABS or engine via PGN 256, Transmission Control 1 (TC1) or other …";
CM_ SG_ 2566802174 TrnsmssnRqstdRngDsplBlnkStt "State signal indicating a transmission request for the display of the Transmission Requested Range parameter (SPN162) to be blanked or not blanked.  The 'Transm…";
CM_ SG_ 2566802174 TrnsmssnRqstdRngDsplFlshStt "State signal indicating a transmission request for the display of the Transmission Requested Range parameter (SPN 162) to flash or not to flash. The 'Transmissi…";
CM_ SG_ 2566802174 TrnsmssnRvrsGrShftInhtStts "Reflects the status of transmission reverse inhibit activity in response to requests via SPN 4242 - Transmission Reverse Gear Shift Inhibit Request.  Typically …";
CM_ SG_ 2566802174 TrnsmssnShftInhtIndtr "State signal indicating a transmission request for the Shift Inhibit Indicator to be active or inactive. The shift inhibit indicator can be of lamp or text form…";
CM_ BO_ 2566802430 "Transmission Configuration 2";
CM_ SG_ 2566802430 TransmissionReferenceTorque "This parameter is the 100% reference value for all defined transmission output torque parameters.  For a given vehicle application, it is only defined once and …";
CM_ SG_ 2566802430 TransmissionTorqueLimit "Parameter provided to the engine from the transmission as a torque limit to be invoked by the engine in the event that J1939 communication with the transmission…";
CM_ SG_ 2566802430 TrnsmssnCmmntnsFlrIdlTrqLmt "This parameter is provided to the engine from the transmission as an idle governor torque limit to be invoked by the engine in the event that CAN communication …";
CM_ BO_ 2566802686 "Military Lighting Command";
CM_ SG_ 2566802686 BlackOutBrakeStopLampSelect "Black Out Brake/Stop Lamp Selection00b = Off01b = On10b = Reserved11b = Not Supported…";
CM_ SG_ 2566802686 BlackOutWorkLampSelect "Black Out Work Lamp Selection00b = Off01b = On10b = Reserved11b = Not Supported…";
CM_ SG_ 2566802686 ConvoyDrivingLampSelect "Black Out Convoy Driving Lamp Selection00b = Off01b = On10b = Reserved11b = Not Supported…";
CM_ SG_ 2566802686 ConvoyLampSelect "Black Out Convoy Lamp Selection00b = Off01b = On10b = Reserved11b = Not Supported…";
CM_ SG_ 2566802686 FrontBlackOutMarkerLampSelect "Front Black Out Marker Lamp Selection00b = Off01b = On10b = Reserved11b = Not Supported…";
CM_ SG_ 2566802686 NightVisionIlluminatorSelect "Night Vision Illuminator Selection00b = Off01b = On10b = Reserved11b = Not Supported…";
CM_ SG_ 2566802686 OprtrsBlkOtIntnstSltn "Operators Selection of lamp intensity in black out mode.  This parameter provides the operators selected illumination intensity as a percentage of available ful…";
CM_ SG_ 2566802686 RearBlackOutMarkerSelect "Rear Black Out Marker Selection00b = Off01b = On10b = Reserved11b = Not Supported…";
CM_ BO_ 2566803198 "Door Control 1";
CM_ SG_ 2566803198 Positionofdoors "Signal which indicates the actual position of the doors.0000b = At least 1 door is open0001b = Closing last door0010b = All doors closed0011b to 1101b = Not def…";
CM_ SG_ 2566803198 RampWheelChairLiftPosition "Signal which indicates the actual position of the ramp / wheel chair lift.00b = Inside bus01b = Outside bus10b = Error11b = Not available…";
CM_ SG_ 2566803198 Status2ofdoors "Composite indication of all bus door statuses. Enabled means the bus doors are able to be automatically opened or closed.00b = all bus doors are disabled01b = a…";
CM_ BO_ 2566803454 "Vehicle Dynamic Stability Control 1";
CM_ SG_ 2566803454 ROPBrakeControlactive "State signal which indicates that Roll over Prevention (ROP) has activated brake control. Active means that ROP actually controls wheel brake pressure at one or…";
CM_ SG_ 2566803454 ROPEngineControlactive "State Signal which indicates that the Roll Over Prevention (ROP) has commanded engine control to be active. Within the physical limits, ROP attempts to prevent …";
CM_ SG_ 2566803454 TrailerVDCActive "The trailer-VDC (Vehicle Dynamic Control) is an electronic vehicle stability function within the (semi) trailer braking system. It acts to stabilize the (semi) …";
CM_ SG_ 2566803454 VDCbrakelightrequest "Indicates whether VDC requests to turn the vehicle brake lights on00b = Turn brake light not on01b = Turn brake light on10b = Reserved11b = Don't care/Take no a…";
CM_ SG_ 2566803454 VDCFullyOperational "Signal that indicates whether VDC is fully operational or whether its functionality is reduced by a permanent or temporary (e.g. low voltage) defect, by intende…";
CM_ SG_ 2566803454 VDCInformationSignal "This parameter commands the VDC information signal, for example a dash lamp.00b = Off01b = On10b = Reserved11b = Don't care/Take no action…";
CM_ SG_ 2566803454 YCBrakeControlactive "State signal which indicates that Yaw Control (YC) has activated brake control. Active means that YC actually controls wheel brake pressure at one or more wheel…";
CM_ SG_ 2566803454 YCEngineControlactive "State Signal which indicates that the Yaw Control (YC) has commanded engine control to be active. Within the physical limits, YC attempts to prevent yawing of t…";
CM_ BO_ 2566803710 "Battery Temperature";
CM_ SG_ 2566803710 SLIBattery1Temperature "Temperature of the battery 1 used for starting the engine, for lighting, and for ignition (SLI). The relation to physical location is determined by the equipmen…";
CM_ SG_ 2566803710 SLIBattery2Temperature "Temperature of the second battery or second set of batteries used for starting the engine, for lighting, and for ignition (SLI). The relation to physical locati…";
CM_ SG_ 2566803710 SLIBattery3Temperature "Temperature of the third battery or third set of batteries used for starting the engine, for lighting, and for ignition (SLI). The relation to physical location…";
CM_ SG_ 2566803710 SLIBattery4Temperature "Temperature of the fourth battery or fourth set of batteries used for starting the engine, for lighting, and for ignition (SLI). The relation to physical locati…";
CM_ BO_ 2566803966 "Adaptive Cruise Control, Operator Input";
CM_ SG_ 2566803966 ACCusagedemand "This parameter indicates the drivers demand to activate or deactivate ACC keeping distance control.00b = driver demand for not using ACC distance keeping contro…";
CM_ SG_ 2566803966 RequestedACCDistanceMode "The Requested Distance Control Mode to the ACC system from the operators interface.The ACC Set Distance Mode (SPN 1589) indicates the selected Distance Control …";
CM_ BO_ 2566804222 "Vehicle Electrical Power 3";
CM_ SG_ 2566804222 AltrntrCrrntHghRngRsltn "This parameter indicates the amount of electrical current output from the alternator of the main vehicle.  Alternator Current (SPN 115) has a lower range and re…";
CM_ SG_ 2566804222 SLIBattery2NetCurrent "Net flow of electrical current into/out of the second battery or second set of batteries used for starting the engine, for lighting, and for ignition (SLI).…";
CM_ SG_ 2566804222 SLIBttr1NtCrrntHghRngRsltn "Net flow of electrical current into/out of the first battery or first set of batteries used for starting the engine, for lighting, and for ignition (SLI).  If m…";
CM_ BO_ 2566804478 "Retarder Continuous Torque & Speed Limit";
CM_ SG_ 2566804478 HLtTsdMCtsRPMRtd "Maximum allowable value for minimum continuous retarder speed…";
CM_ SG_ 2566804478 HLtTsdMCtsTqRtd "Maximum allowable value for minimum continuous retarder torque.…";
CM_ SG_ 2566804478 LwLmtThrshldfrMxmmRPMfrmRtrdr "Minimum allowable value for maximum continuous retarder speed…";
CM_ SG_ 2566804478 LwLmtThrshldfrMxmmTrqfrmRtrdr "Minimum allowable value for maximum continuous retarder torque.…";
CM_ SG_ 2566804478 MaximumContinuousRetarderSpeed "Applied limit for maximum continuous retarder RPM…";
CM_ SG_ 2566804478 MaximumContinuousRetarderTorque "Applied limit for maximum continuous retarder torque.…";
CM_ SG_ 2566804478 MinimumContinuousRetarderSpeed "Applied limit for minimum continuous retarder RPM…";
CM_ SG_ 2566804478 MinimumContinuousRetarderTorque "Applied limit for minimum continuous retarder torque…";
CM_ BO_ 2566804734 "Engine Continuous Torque & Speed Limit";
CM_ SG_ 2566804734 EHLtTsdMCtsERPM "Maximum allowable value for minimum continuous RPM from engine…";
CM_ SG_ 2566804734 EHLtTsdMCtsTqE "Maximum allowable value for minimum continuous torque from engine…";
CM_ SG_ 2566804734 ELwLtTsdMxRPME "Minimum allowable value for maximum continuous RPM from engine…";
CM_ SG_ 2566804734 ELwLtTsdMxTqE "Minimum allowable value for maximum continuous torque from engine…";
CM_ SG_ 2566804734 EngineMaximumContinuousRPM "Applied limit for maximum continuous engine RPM…";
CM_ SG_ 2566804734 EngineMaximumContinuousTorque "Applied limit for maximum continuous engine torque.…";
CM_ SG_ 2566804734 EngineMinimumContinuousRPM "Applied limit for minimum continuous engine RPM…";
CM_ SG_ 2566804734 EngineMinimumContinuousTorque "Applied limit for minimum continuous engine torque…";
CM_ BO_ 2566804990 "Gaseous Fuel Properties";
CM_ SG_ 2566804990 Fuelenergycontent "Energy content (lower heating value) of the gaseous fuel.Note:  For gaseous fuels, the fuel's energy content (lower heating value) is commonly defined in terms …";
CM_ SG_ 2566804990 ReferenceEngineGasMassFlowRate "Configuration of the mass flow rate of gaseous fuel expected for 100% engine fuel valve control command.Note:  The actuator will request this parameter from the…";
CM_ SG_ 2566804990 SpecificHeatRatio "The specific heat ratio of the fuel.…";
CM_ BO_ 2566805246 "Aftertreatment 1 Diesel Exhaust Fluid Tank 1 Information 1";
CM_ SG_ 2566805246 Aftrtrtmnt1DslExhstFldTnkHtr "Percentage of heating applied to the aftertreatment 1 diesel exhaust fluid tank heater.  A value of 0% means no heating applied, a value of 100% means full heat…";
CM_ SG_ 2566805246 Aftrtrtmnt1DslExhstFldTnkLvl "The diesel exhaust fluid level height in mm in the diesel exhaust fluid storage container for aftertreatment system 1 (exhaust bank 1).  See SPN 1761 and SPN 75…";
CM_ SG_ 2566805246 Aftrtrtmnt1DslExhstFldTnkVlm "Ratio of volume of diesel exhaust fluid to the total volume of diesel exhaust fluid storage container for aftertreatment system 1 (exhaust bank 1).  0% is empty…";
CM_ SG_ 2566805246 AftrtrtmntSCROprtrIndmntSvrt "Severity status of the operator inducement system for anomalies with the SCR system, such as tampering, low DEF quality, and DEF tank level.  Higher numerical l…";
CM_ SG_ 2566805246 Atttt1DsExstFdT1HtPFMI "Used to identify the applicable J1939-73 FMI detected for the heater of the diesel exhaust fluid tank for aftertreatment system 1 (exhaust bank 1), as detected …";
CM_ SG_ 2566805246 Atttt1DsExstFdT1TptPFMI "Used to identify the applicable J1939-73 FMI detected for the diesel exhaust fluid tank temperature for aftertreatment system 1 (exhaust bank 1), as detected by…";
CM_ SG_ 2566805246 Atttt1DsExstFdTLvVPFMI "Used to identify the applicable J1939-73 FMI detected in the diesel exhaust fluid tank level sensor by the manufacturer's sensor control software.  This FMI is …";
CM_ SG_ 2566805246 Atttt1DsExstFdTTpt1 "Temperature of the diesel exhaust fluid in the storage tank.…";
CM_ SG_ 2566805246 AttttDsExstFdTLwLvIdt "The desired illumination of the driver's warning indicator for diesel exhaust fluid (DEF) tank low level.000b = Off -  indicates adequate DEF level   e.g., for …";
CM_ BO_ 2566805758 "Air Suspension Control 4";
CM_ SG_ 2566805758 BellowPressureFrontAxleLeft "Information of the pressure of the air suspension bellow at the left side of the front axle…";
CM_ SG_ 2566805758 BellowPressureFrontAxleRight "Information of the pressure of the air suspension bellow at the right side of the front axle…";
CM_ SG_ 2566805758 BellowPressureRearAxleLeft "Information of the pressure of the air suspension bellow at the left side of the rear axle…";
CM_ SG_ 2566805758 BellowPressureRearAxleRight "Information of the pressure of the air suspension bellow at the right side of the rear axle…";
CM_ BO_ 2566806014 "Air Suspension Control 3";
CM_ SG_ 2566806014 RelativeLevelFrontAxleLeft "Information of the height at the left side of the front axle referred to normal level 1.  For explanations of normal level 1 see SPN 1734 - Nominal Level Front …";
CM_ SG_ 2566806014 RelativeLevelFrontAxleRight "Information of the height at the right side of the front axle referred to normal level 1.  For explanations of normal level 1 see SPN 1734 - Nominal Level Front…";
CM_ SG_ 2566806014 RelativeLevelRearAxleLeft "Information of the height at the left side of the rear axle referred to normal level 1.  For explanations of normal level 1 see parameter SPN 1734 - Nominal Lev…";
CM_ SG_ 2566806014 RelativeLevelRearAxleRight "Information of the height at the left side of the rear axle referred to normal level 1.  For explanations of normal level 1 see parameter SPN 1734 - Nominal Lev…";
CM_ BO_ 2566806526 "Forward Lane Image 2";
CM_ SG_ 2566806526 DriverAlertnessLevel "Indicates the alertness level of the driver measured by the driver alertness warning system. 100 % means driver is fully attentive. This signal can be used inde…";
CM_ SG_ 2566806526 DrvrAlrtnssWrnngSstmStt "Indicates the various system state in the driver alertness warning system. This signal can be used independent of the technology and ECU used to estimate the dr…";
CM_ SG_ 2566806526 ForwardLaneImagerStatus "Indicates the status of the Forward Looking Imager.0000b = Imager fully operational0001b = Imager warming up / initializing0010b = Imager partially blocked / pa…";
CM_ SG_ 2566806526 LaneDepartureWarningSystemState "Indicates the status of Lane Departure Warning system.0000b = System is not ready (initialization not finished)0001b = System is temporarily not available (not …";
CM_ SG_ 2566806526 LaneTrackingStatusLeftSide "Indicates whether the left side is tracking lane.00b = Not Tracking Left side01b = Tracking Left side10b = Reserved11b = Don't care/Take no action…";
CM_ SG_ 2566806526 LaneTrackingStatusRightSide "Indicates whether right side is tracking lane.00b = Not Tracking Right side01b = Tracking Right side10b = Reserved11b = Don't Care/take no action…";
CM_ SG_ 2566806526 LeftWheelLaneDepartureDistance "The measured distance of departure of the left wheel on the left side of the lane, as measured from the left edge of the left tire to the right edge of the curr…";
CM_ SG_ 2566806526 LnDprtrIndtnEnlStts "Indicates whether lane departure indication is active.00b = Lane Departure indication disabled01b = Lane Departure Indication enabled 10b = Reserved11b = Not Us…";
CM_ SG_ 2566806526 RightWheelLaneDepartureDistance "The measured distance of departure of the right wheel on the right side of the lane, as measured from the right edge of the right tire to the left edge of the c…";
CM_ BO_ 2566809342 "Battery Main Switch Information";
CM_ SG_ 2566809342 BatteryMainSwitchHoldState "Parameter indicating whether the battery main switch is held due to an external request or not. The state battery main switch held indicates that the battery ma…";
CM_ BO_ 2566809598 "Climate Control Configuration";
CM_ SG_ 2566809598 AxlrHtrMxmmOtptPwr "The maximum output power of the auxiliary heater.…";
CM_ BO_ 2566809854 "Vehicle Fluids";
CM_ SG_ 2566809854 HdrlOlFltrRstrtnSwth "This switch indicates whether hydraulic oil filter is clogged. This is not the transmission oil filter restriction switch, which is SPN 3359.00b = No restrictio…";
CM_ SG_ 2566809854 HydraulicOilLevel "This parameter indicates the level of the hydraulic fluid in tank as a ratio of current volume to total tank volume.  This parameter is intended for reporting t…";
CM_ SG_ 2566809854 HydraulicTemperature "Temperature of hydraulic fluid.…";
CM_ SG_ 2566809854 WinchOilPressureSwitch "State of switch used to determine if Winch Oil Pressure is above desired minimum00b = NOT OK- Oil pressure is too low01b = OK - Oil pressure is above minimum10b…";
CM_ BO_ 2566810110 "Engine Temperature 3";
CM_ SG_ 2566810110 EngnChrgArClr1OtltTmprtr "Temperature of combustion air after it exits from the Charge Air Cooler 1 but before any mixing of recirculated exhaust gas.…";
CM_ SG_ 2566810110 EngnClntTmprtrHghRsltn "Temperature of liquid found in engine cooling system. The higher resolution is required for control purposes.…";
CM_ SG_ 2566810110 EngnIntkMnfld1TmprtrHghRsltn "Temperature of pre-combustion air found in intake manifold of engine air supply system. The higher resolution is required for control purposes.…";
CM_ SG_ 2566810110 EngnIntkVlvAttnSstmOlTmprtr "The temperature of the oil in the hydraulic system that powers the intake valve actuation system.…";
CM_ BO_ 2566810366 "Engine Fuel/Lube Systems";
CM_ SG_ 2566810366 EngineCoolantPreheatedState "Indicates whether the engine coolant is pre-heated sufficiently for starting purposes.00b = Not sufficiently pre-heated01b = Sufficiently pre-heated10b = Unable…";
CM_ SG_ 2566810366 EngineOilFilterOutletPressure "Oil pressure (gage) measured just downstream of oil filter.Used in conjunction with SPN1208 (pre-filter oil pressure) to determine oil filter health.…";
CM_ SG_ 2566810366 EngineOilLevelRemoteReservoir "Ratio of current volume of engine oil in a remote reservoir to the maximum required volume.  If a single switch (on/off) is used, 20% and 100% respectively will…";
CM_ SG_ 2566810366 EngineOilPreHeatedState "Indicates whether the engine oil pre-heated sufficiently for starting purposes.00b = Not sufficiently pre-heated01b = Sufficiently pre-heated10b = Unable to det…";
CM_ SG_ 2566810366 EngineOilPrimingPumpSwitch "Switch input for activating the engine oil priming pump.00b = Off01b = On10b = Error11b = Not available or not installed…";
CM_ SG_ 2566810366 EngineOilPrimingState "Determination of whether or not the engine is (or has recently been) sufficiently lubricated for starting purposes.00b = Not sufficiently lubricated01b = Suffic…";
CM_ SG_ 2566810366 EngineVentilationStatus "Engine ventilation control states.000b = Sufficiently vented (all combustible gases have been evacuated from intake and exhaust systems)001b = Ventilation neede…";
CM_ SG_ 2566810366 EngineWasteOilReservoirLevel "Level of crankcase blowby emulsion collected by a container.  Normalized to percent, 0% represents completely empty and 100% represents completely full.…";
CM_ SG_ 2566810366 EngnFlFltrstnsdDffrntlPrssr "Differential pressure measured across the fuel filter located between the fuel tank and the supply pump.  See Figures SPN16_A and SPN16_B.…";
CM_ SG_ 2566810366 EngnFlSpplPmpIntkAsltPrssr "Absolute pressure of fuel at the fuel supply pump intake.  See Figures SPN16_A & SPN16_B.  See SPN 7472 for alternate resolution.…";
CM_ SG_ 2566810366 EngnFlSpplPmpIntkPrssr "Gage pressure of fuel at the fuel supply pump intake.  See Figures SPN16_A & SPN16_B.See also SPN 1381.…";
CM_ SG_ 2566810366 FuelPumpPrimerStatus "Parameter used to transmit the actual status of the fuel priming system.  The fuel priming system is a system that purges air in the fuel lines and may assist f…";
CM_ BO_ 2566810622 "Driver's Identification";
CM_ SG_ 2566810622 Driver1identification "Used to obtain the driver identity.…";
CM_ SG_ 2566810622 Driver2identification "Used to obtain the driver identity.…";
CM_ BO_ 2566811134 "Heater Information";
CM_ SG_ 2566811134 ADRCompliantHeaterInstallation "Indicates that the heater is installed in an ADR compliant vehicle.   00b = Heater installation is not ADR compliant01b = Heater installation is ADR compliant10…";
CM_ SG_ 2566811134 AuxiliaryHeaterMode "State of the auxiliary heater0000b = Heater not active0001b = Off due to ADR per European Regulations for Transport of hazardous materials0010b = Economy mode00…";
CM_ SG_ 2566811134 AuxiliaryHeaterWaterPumpStatus "Parameter indicating whether the auxiliary heater water pump is running00b = Water Pump is not running01b = Water Pump is  running10b = Reserved11b = Not availa…";
CM_ SG_ 2566811134 AxlrHtrInptArTmprtr "Temperature of the input air in an auxiliary heater system.…";
CM_ SG_ 2566811134 AxlrHtrOtptClntTmprtr "Temperature of the auxiliary heater output coolant (I.e. water in a water heater system.)…";
CM_ SG_ 2566811134 AxlrHtrOtptPwrPrnt "Current auxiliary heater output power, relative to the auxiliary heater maximum output power.…";
CM_ SG_ 2566811134 CabHeatingZone "Parameter indicating whether the cab zone is being heated.00b = Cab heating zone off01b = Cab heating zone on10b = Reserved11b = Not available…";
CM_ SG_ 2566811134 CabVentilation "Indicates whether the cab is being ventilated or not.00b = Cab not ventilated01b = Cab is ventilated10b = Reserved11b = Not available…";
CM_ SG_ 2566811134 EngineHeatingZone "Parameter indicating whether the engine zone is being heated.00b = Engine heating zone off01b = Engine heating zone on10b = Reserved11b = Not available…";
CM_ BO_ 2566811902 "Combination Vehicle Weight";
CM_ SG_ 2566811902 GrossCombinationVehicleWeight "The total weight of the truck and all attached trailers.…";
CM_ SG_ 2566811902 PoweredVehicleWeight "Total mass imposed by the tires of the powered vehicle on the road surface.  Does not include the trailer.…";
CM_ BO_ 2566819326 "Vehicle Electrical Power 2";
CM_ SG_ 2566819326 BatteryPotentialPowerInput2 "This parameter measures the second source of battery potential as measured at the input of the ECU/actuator etc. coming from one or more batteries, irrespective…";
CM_ SG_ 2566819326 ECUPowerOutputSupplyVoltage1 "The first power output from an ECU.…";
CM_ SG_ 2566819326 ECUPowerOutputSupplyVoltage2 "The second power output from an ECU.…";
CM_ SG_ 2566819326 ECUPowerOutputSupplyVoltage3 "The third power output from an ECU.…";
CM_ BO_ 2566819838 "Supply Pressure 2";
CM_ SG_ 2566819838 EngnExtrnlShtdwnArSpplPrssr "Pressure of the air used to shut off the fuel supply to the engine.…";
CM_ BO_ 2566820094 "Engine Torque History";
CM_ SG_ 2566820094 CalibrationRecordDurationTime "Duration in hours for which the engine operated in the conditions captured in the current record.…";
CM_ SG_ 2566820094 CalibrationRecordStartDay "Calendar day timestamp when an ECU record was established.NOTE - A value of 0 for the date is null.  The values 1, 2, 3, and 4 are used to identify the first da…";
CM_ SG_ 2566820094 CalibrationRecordStartMonth "Calendar month timestamp when an ECU record was established.NOTE - A value of 0 for the month is null.  The value 1 identifies January; 2 identifies February; e…";
CM_ SG_ 2566820094 CalibrationRecordStartYear "Calendar year timestamp when an ECU record was established.NOTE - A value of 0 for the year identifies the year 1985; a value of 1 identifies 1986; etc.…";
CM_ SG_ 2566820094 EnginePeakTorque1 "Maximum torque output of the current ECU calibration when the engine operates on torque curve 1.  For calibrations that support two torque curves, this paramete…";
CM_ SG_ 2566820094 EnginePeakTorque2 "Maximum torque output of the current ECU calibration when the engine operates on torque curve 2.  For calibrations that support two torque curves, this paramete…";
CM_ SG_ 2566820094 EnginePower "Advertised engine power capability.  Advertised power is what a customer will find on a sales sheet for an engine with a certain calibration.…";
CM_ SG_ 2566820094 EngineTorqueLimit1Transmission "Limit applied to the engine output torque during vehicle operation in transmission gear ratios numerically greater than transmission gear ratio 1 (see SPN 1255)…";
CM_ SG_ 2566820094 EngineTorqueLimit2Transmission "Limit applied to the engine output torque during vehicle operation in transmission gear ratios numerically less than or equal to transmission gear ratio 1 (see …";
CM_ SG_ 2566820094 EngineTorqueLimit3Transmission "Limit applied to the engine output torque during vehicle operation in transmission gear ratios numerically less than or equal to transmission gear ratio 2 (see …";
CM_ SG_ 2566820094 EngineTorqueLimit4Transmission "Limit applied to the engine output torque during vehicle operation in transmission gear ratios numerically less than or equal to transmission gear ratio 3 (see …";
CM_ SG_ 2566820094 EngineTorqueLimit5Switch "Limit applied to the engine output torque based on activation of an ECU switch input.…";
CM_ SG_ 2566820094 EngineTorqueLimit6AxleInput "Limit applied to the engine output torque based on the maximum allowable axle input torque.  Axle input torque is calculated as the current engine torque output…";
CM_ SG_ 2566820094 EngineTorqueLimitFeature "Torque limit rating described in the current record. 000b = Reserved001b = Highest torque rating010b = First torque rating011b = Previous torque rating (rating …";
CM_ SG_ 2566820094 NmrfEngnTrqHstrRrds "Number of torque history records contained in the engine torque history PGN.  A value of 0 is broadcast if no torque history records are stored in the ECU.…";
CM_ SG_ 2566820094 TorqueLimitingFeatureStatus "Status of an ECU feature which limits the torque output of the engine. 00b = Disabled01b = Enabled10b = Error11b = Not available…";
CM_ SG_ 2566820094 TransmissionGearRatio1 "Gear ratio value stored in the ECU that is used to define a range of transmission gears for which a limit is applied to the engine output torque.  Transmission …";
CM_ SG_ 2566820094 TransmissionGearRatio2 "Gear ratio value stored in the ECU that is used to define a range of transmission gears for which a limit is applied to the engine output torque.  Transmission …";
CM_ SG_ 2566820094 TransmissionGearRatio3 "Gear ratio value stored in the ECU that is used to define a range of transmission gears for which a limit is applied to the engine output torque.  Transmission …";
CM_ BO_ 2566821118 "Engine Auxiliary Coolant";
CM_ SG_ 2566821118 EngineAuxiliaryCoolantPressure "Gage pressure of coolant found in the intercooler which is located after the turbocharger.…";
CM_ SG_ 2566821118 EngnAxlrClntTmprtr "Temperature of coolant found in the intercooler which is located after the turbocharger.…";
CM_ SG_ 2566821118 EngnClntPmpClntOtltPrssr "Engine coolant pressure at the coolant pump outlet.…";
CM_ SG_ 2566821118 EngnClntPrssr1ExtnddRng "Gage pressure of liquid found in engine cooling system.See also SPN 109 for alternate range and resolution.…";
CM_ SG_ 2566821118 EngnClntPrssr2ExtnddRng "Gage pressure of liquid found in engine coolant system - second instance.See also SPN 5708 for alternate range and resolution.…";
CM_ SG_ 2566821118 SeaWaterPumpOutletPressure "Gauge pressure of liquid found at outlet of sea water pump in sea water cooling system.…";
CM_ BO_ 2566821630 "Turbocharger Wastegate";
CM_ SG_ 2566821630 EngnTrhrgrWstgtAttr1DsrdPstn "The Requested Valve position of the Turbocharger Wastegate Valve 1, commanded by the engine ECU. A value of 0% represents fully closed and a value of 100% repre…";
CM_ SG_ 2566821630 EngnTrhrgrWstgtAttr1PrlmnrFMI "Used to identify the applicable J1939-73 FMI detected in the Engine Turbocharger Wastegate Actuator 1 by the manufacturers software.  When there is multiple fai…";
CM_ SG_ 2566821630 EngnTrhrgrWstgtAttr1Pstn "Position of the wastegate drive.  A value of 0% represents fully closed and a value of 100% represents fully open.…";
CM_ SG_ 2566821630 EngnTrhrgrWstgtAttr1TmprtrStts "Used to identify the status of the Engine Turbocharger Wastegate Actuator 1 drive circuitry temperature.  Temperature excursions may affect the torque output.00…";
CM_ SG_ 2566821630 EngnTrhrgrWstgtAttr2DsrdPstn "The Requested Valve position of the Turbocharger Wastegate Valve 2, commanded by the engine ECU. A value of 0% represents fully closed and a value of 100% repre…";
CM_ SG_ 2566821630 EngnTrhrgrWstgtAttr2Pstn "Position of the wastegate drive.  A value of 0% represents fully closed and a value of 100% represents fully open.…";
CM_ SG_ 2566821630 EngnTrhrgrWstgtAttr3Pstn "Position of the wastegate drive.  A value of 0% represents fully closed and a value of 100% represents fully open.…";
CM_ SG_ 2566821630 EngnTrhrgrWstgtAttr4Pstn "Position of the wastegate drive.  A value of 0% represents fully closed and a value of 100% represents fully open.…";
CM_ SG_ 2566821630 EngnTrhrgrWstgtAttrCntrlArPrssr "Gage pressure of the air used to control the actuator which opens and closes the wastegate valve.…";
CM_ BO_ 2566821886 "Turbocharger Information 5";
CM_ SG_ 2566821886 EngnTrhrgr1TrnOtltTmprtr "Temperature of the combustion by-products exiting the turbine side of the turbocharger.…";
CM_ SG_ 2566821886 EngnTrhrgr2TrnOtltTmprtr "Temperature of the combustion by-products exiting the turbine side of the turbocharger.…";
CM_ SG_ 2566821886 EngnTrhrgr3TrnOtltTmprtr "Temperature of the combustion by-products exiting the turbine side of the turbocharger.…";
CM_ SG_ 2566821886 EngnTrhrgr4TrnOtltTmprtr "Temperature of the combustion by-products exiting the turbine side of the turbocharger.…";
CM_ BO_ 2566822142 "Turbocharger Information 4";
CM_ SG_ 2566822142 EngnTrhrgr1TrnIntkTmprtr "Temperature of the combustion by-products entering the turbine side of the turbocharger.…";
CM_ SG_ 2566822142 EngnTrhrgr2TrnIntkTmprtr "Temperature of the combustion by-products entering the turbine side of the turbocharger.…";
CM_ SG_ 2566822142 EngnTrhrgr3TrnIntkTmprtr "Temperature of the combustion by-products entering the turbine side of the turbocharger.…";
CM_ SG_ 2566822142 EngnTrhrgr4TrnIntkTmprtr "Temperature of the combustion by-products entering the turbine side of the turbocharger.…";
CM_ BO_ 2566822398 "Turbocharger Information 3";
CM_ SG_ 2566822398 EngnTrhrgr1CmprssrIntkPrssr "Gage pressure of the air entering the compressor side of the turbocharger.…";
CM_ SG_ 2566822398 EngnTrhrgr2CmprssrIntkPrssr "Gage pressure of the air entering the compressor side of the turbocharger.…";
CM_ SG_ 2566822398 EngnTrhrgr3CmprssrIntkPrssr "Gage pressure of the air entering the compressor side of the turbocharger.…";
CM_ SG_ 2566822398 EngnTrhrgr4CmprssrIntkPrssr "Gage pressure of the air entering the compressor side of the turbocharger.…";
CM_ BO_ 2566822654 "Turbocharger Information 2";
CM_ SG_ 2566822654 EngnTrhrgr1CmprssrIntkTmprtr "Temperature of the air entering the compressor side of the turbocharger.…";
CM_ SG_ 2566822654 EngnTrhrgr2CmprssrIntkTmprtr "Temperature of the air entering the compressor side of the turbocharger.…";
CM_ SG_ 2566822654 EngnTrhrgr3CmprssrIntkTmprtr "Temperature of the air entering the compressor side of the turbocharger.…";
CM_ SG_ 2566822654 EngnTrhrgr4CmprssrIntkTmprtr "Temperature of the air entering the compressor side of the turbocharger.…";
CM_ BO_ 2566823166 "Main Bearing Temperature 3";
CM_ SG_ 2566823166 EngineMainBearing10Temperature "Temperature of the main bearing which supports the crankshaft of the engine.…";
CM_ SG_ 2566823166 EngineMainBearing11Temperature "Temperature of the main bearing which supports the crankshaft of the engine.…";
CM_ SG_ 2566823166 EngineMainBearing12Temperature "Temperature of the main bearing which supports the crankshaft of the engine.…";
CM_ SG_ 2566823166 EngineMainBearing9Temperature "Temperature of the main bearing which supports the crankshaft of the engine.…";
CM_ BO_ 2566823422 "Main Bearing Temperature 2";
CM_ SG_ 2566823422 EngineMainBearing5Temperature "Temperature of the main bearing which supports the crankshaft of the engine.…";
CM_ SG_ 2566823422 EngineMainBearing6Temperature "Temperature of the main bearing which supports the crankshaft of the engine.…";
CM_ SG_ 2566823422 EngineMainBearing7Temperature "Temperature of the main bearing which supports the crankshaft of the engine.…";
CM_ SG_ 2566823422 EngineMainBearing8Temperature "Temperature of the main bearing which supports the crankshaft of the engine.…";
CM_ BO_ 2566823678 "Main Bearing Temperature 1";
CM_ SG_ 2566823678 EngineMainBearing1Temperature "Temperature of the main bearing which supports the crankshaft of the engine.…";
CM_ SG_ 2566823678 EngineMainBearing2Temperature "Temperature of the main bearing which supports the crankshaft of the engine.…";
CM_ SG_ 2566823678 EngineMainBearing3Temperature "Temperature of the main bearing which supports the crankshaft of the engine.…";
CM_ SG_ 2566823678 EngineMainBearing4Temperature "Temperature of the main bearing which supports the crankshaft of the engine.…";
CM_ BO_ 2566824190 "Exhaust Port Temperature 4";
CM_ SG_ 2566824190 EngnExhstGsPrt13Tmprtr "Temperature at the cylinder exhaust port of the engine.…";
CM_ SG_ 2566824190 EngnExhstGsPrt14Tmprtr "Temperature at the cylinder exhaust port of the engine.…";
CM_ SG_ 2566824190 EngnExhstGsPrt15Tmprtr "Temperature at the cylinder exhaust port of the engine.…";
CM_ SG_ 2566824190 EngnExhstGsPrt16Tmprtr "Temperature at the cylinder exhaust port of the engine.…";
CM_ BO_ 2566825214 "Engine Temperature 2";
CM_ SG_ 2566825214 EngineECUTemperature "Temperature of the engine electronic control unit.…";
CM_ SG_ 2566825214 EngineOilTemperature2 "Temperature of the engine lubricant.Note:  If there is only one engine oil temperature measurement, SPN 175 should be used. See also SPNs 175 and 5925 for addit…";
CM_ SG_ 2566825214 EngnExhstGsRrltn1DffrntlPrssr "Differential pressure across the Exhaust Gas Recirculation (EGR) system…";
CM_ SG_ 2566825214 EngnExhstGsRrltn1Tmprtr "Temperature of Recirculated Exhaust Gas.  This should not be used for Exhaust Gas Recirculation Mixer Intake Temperature.  See SPN 5020.…";
CM_ BO_ 2566825726 "Intake Manifold Information 1";
CM_ SG_ 2566825726 EngnTrhrgr1BstPrssr "Gage pressure of air measured downstream of the compressor discharge side of the turbocharger.  See also SPN 102 for alternate range and resolution. If there is…";
CM_ SG_ 2566825726 EngnTrhrgr2BstPrssr "Gage pressure of air measured downstream of the compressor discharge side of the turbocharger.  See also SPN 102 for alternate range and resolution. If there is…";
CM_ SG_ 2566825726 EngnTrhrgr3BstPrssr "Gage pressure of air measured downstream of the compressor discharge side of the turbocharger.  See also SPN 102 for alternate range and resolution. If there is…";
CM_ SG_ 2566825726 EngnTrhrgr4BstPrssr "Gage pressure of air measured downstream of the compressor discharge side of the turbocharger.  See also SPN 102 for alternate range and resolution. If there is…";
CM_ BO_ 2566827518 "Wheel Application Pressure High Range Information";
CM_ SG_ 2566827518 BApptPssHRFtAxLtW "The brake application pressure for the left wheel on the front axle.…";
CM_ SG_ 2566827518 BApptPssHRFtAxRtW "The brake application pressure for the right wheel on the front axle.…";
CM_ SG_ 2566827518 BApptPssHRRAx1LtW "The brake application pressure for the left wheel on the rear axle #1.…";
CM_ SG_ 2566827518 BApptPssHRRAx1RtW "The brake application pressure for the right wheel on the rear axle #1.…";
CM_ SG_ 2566827518 BApptPssHRRAx2LtW "The brake application pressure for the left wheel on the rear axle #2.…";
CM_ SG_ 2566827518 BApptPssHRRAx2RtW "The brake application pressure for the right wheel on the rear axle #2.…";
CM_ SG_ 2566827518 BApptPssHRRAx3LtW "The brake application pressure for the left wheel on the rear axle #3.…";
CM_ SG_ 2566827518 BApptPssHRRAx3RtW "The brake application pressure for the right wheel on the rear axle #3.…";
CM_ BO_ 2566827774 "Air Supply Pressure";
CM_ SG_ 2566827774 AirCompressorStatus "Indicates whether the air compressor is actively compressing air.  00b = Compressor not active01b = Compressor active10b = Error indicator11b = Not available…";
CM_ SG_ 2566827774 AirSuspensionSupplyPressure "The pneumatic pressure in the circuit for the electronically controlled air suspension system.…";
CM_ SG_ 2566827774 AxlrEqpmntSpplPrssr "The pneumatic pressure in the auxiliary circuit.…";
CM_ SG_ 2566827774 ParkingandorTrailerAirPressure "The pneumatic pressure in the circuit or reservoir for the parking brake and/or the trailer supply.…";
CM_ SG_ 2566827774 PneumaticSupplyPressure "The pneumatic pressure in the main reservoir, sometimes referred to as the wet tank.…";
CM_ SG_ 2566827774 PwrtrnCrtArSpplPrssr "Supply pressure to carry the pressure information for the powertrain circuit. This circuit typically would feed powertrain components such as throttles, gearbox…";
CM_ SG_ 2566827774 ServiceBrakeCircuit1AirPressure "The pneumatic pressure in the primary service brake circuit or reservoir, supplying the rear axle.…";
CM_ SG_ 2566827774 ServiceBrakeCircuit2AirPressure "The pneumatic pressure in the secondary service brake circuit or reservoir, supplying the front axle.…";
CM_ BO_ 2566831614 "Fan Drive #1";
CM_ SG_ 2566831614 EngineFan1EstimatedPercentSpeed "Estimated fan speed as a ratio of the fan drive (current speed) to the fully engaged fan drive (maximum fan speed).  A two state fan (off/on) will use 0% and 10…";
CM_ SG_ 2566831614 FanDriveBypassCommandStatus "Status of the Fan Drive Bypass Command as being commanded by the ECU.  The fan drive bypass diverts pump pressure away from the hydraulic motor to maintain the …";
CM_ SG_ 2566831614 FanDriveState "This parameter is used to indicate the current state or mode of operation by the fan drive.0000b = Fan off0001b = Engine system–General0010b = Excessive engine …";
CM_ SG_ 2566831614 FanSpeed "The speed of the fan associated with engine coolant system.…";
CM_ SG_ 2566831614 HydraulicFanMotorPressure "The hydraulic pressure used to drive the fan system, sensed before the hydraulic fan motor.…";
CM_ BO_ 2566832126 "Wheel Speed Information";
CM_ SG_ 2566832126 FrontAxleSpeed "The average speed of the two front wheels.…";
CM_ SG_ 2566832126 RelativeSpeedFrontAxleLeftWheel "The speed of the front axle, left wheel relative to the front axle speed, SPN 904.…";
CM_ SG_ 2566832126 RltvSpdFrntAxlRghtWhl "The speed of the front axle, right wheel relative to the front axle speed, SPN 904.…";
CM_ SG_ 2566832126 RelativeSpeedRearAxle1LeftWheel "The speed of the rear axle #1, left wheel relative to the front axle speed, SPN 904.…";
CM_ SG_ 2566832126 RltvSpdRrAxl1RghtWhl "The speed of the rear axle #1, right wheel relative to the front axle speed, SPN 904.…";
CM_ SG_ 2566832126 RelativeSpeedRearAxle2LeftWheel "The speed of the rear axle #2, left wheel relative to the front axle speed, SPN 904.…";
CM_ SG_ 2566832126 RltvSpdRrAxl2RghtWhl "The speed of the rear axle #2, right wheel relative to the front axle speed, SPN 904.…";
CM_ BO_ 2566832382 "Service Information";
CM_ SG_ 2566832382 ServiceDelayCalendarTimeBased "The time in weeks until the next vehicle service inspection is required.  A negative value is transmitted if the service inspection has been passed.  The compon…";
CM_ SG_ 2566832382 ServiceDistance "The distance which can be traveled by the vehicle before the next service inspection is required.  A negative distance is transmitted if the service inspection …";
CM_ SG_ 2566832382 SrvDlOprtnlTmBsd "The time in vehicle operational time until the next vehicle service inspection is required.  A negative value is transmitted if the service inspection has been …";
CM_ SG_ 2566832382 ServiceComponentIdentificationA "Identification of component needing service.  See Table SPN911_A.…";
CM_ SG_ 2566832382 ServiceComponentIdentificationB "Identification of component needing service.  See Table SPN911_A.…";
CM_ SG_ 2566832382 ServiceComponentIdentificationC "Identification of component needing service.  See Table SPN911_A.…";
CM_ BO_ 2566832638 "High Resolution Vehicle Distance";
CM_ SG_ 2566832638 TripDistanceHighResolution "Distance traveled during all or part of a journey.NOTE - See SPN 244 for alternate resolution.…";
CM_ SG_ 2566832638 TtlVhlDstnHghRsltn "Accumulated distance traveled by the vehicle during its operation.NOTE - See SPN 245 for alternate resolution.…";
CM_ BO_ 2566837758 "Alternator Information";
CM_ SG_ 2566837758 Alternator1Status "Alternator 1 operating status.00b = Alternator 1 not charging01b = Alternator 1 charging10b = error11b = not available…";
CM_ SG_ 2566837758 Alternator2Status "Alternator 2 operating status.00b = Alternator 2 not charging01b = Alternator 2 charging10b = error11b = not available…";
CM_ SG_ 2566837758 Alternator3Status "Alternator 3 operating status.00b = Alternator 3 not charging01b = Alternator 3 charging10b = error11b = not available…";
CM_ SG_ 2566837758 Alternator4Status "Alternator 4 operating status.00b = Alternator 4 not charging01b = Alternator 4 charging10b = error11b = not available…";
CM_ SG_ 2566837758 AlternatorSpeed "Actual rotation speed of the alternator.…";
CM_ BO_ 2566838014 "Hybrid System Inputs 1";
CM_ SG_ 2566838014 HrdSstmBrkPdlRgnrtvBrkngDslSwth "Indicates the brake pedal regenerative braking disable switch position.  This switch allows the operator to disable regenerative braking (e.g. such as during sl…";
CM_ SG_ 2566838014 HrdSstmCstngRgnrtvBrkngLvlSltr "Indicates the coasting regenerative braking level selector position.  Coasting regenerative braking occurs when neither the accelerator nor the brake pedal are …";
CM_ SG_ 2566838014 HrdSstmOffBrdChrgrCnntnStts "Indicates the off-board plug-in charger connection status.  One of the uses of this signal is to protect against vehicle motion while a charger is plugged in.00…";
CM_ SG_ 2566838014 HrdSstmPrplsnClntLvlSwth "Indicates the coolant level switch position in the hybrid system propulsion (e.g. electric motor, generator) cooling system.00b = Coolant Level is not sufficien…";
CM_ SG_ 2566838014 HrdSstmPrplsnDslSwth "When the operator enables this switch, the propulsion aspect of hybrid system operation will be disabled.  However, hybrid powered accessories may be on and the…";
CM_ SG_ 2566838014 HrdSstmPrttnOvrrdSwth "Indicates the Protection Override switch position.  This switch allows the operator to override hybrid system protection features and failure modes allowing hyb…";
CM_ SG_ 2566838014 HrdSstmPwrEltrnsClntLvlSwth "Indicates the coolant level switch position in the hybrid system power electronics (e.g. Inverters, DC/DC converters) cooling system.00b = Coolant Level is not …";
CM_ SG_ 2566838014 HrdSstmRgnrtvBrkngDslSwth "Indicates the regenerative braking disable switch position.  This switch gives the operator the ability to disable all regenerative braking from all inputs (e.g…";
CM_ SG_ 2566838014 HybridSystemShutdownSwitch "When the operator enables this switch, all hybrid system functionality is disabled including propulsion, regenerative braking, and hybrid powered accessories.  …";
CM_ SG_ 2566838014 PrplsnMtrClntFllSwth "Indicates the coolant fill switch position for the propulsion motor cooling system.  This switch is used to enable the pump for filling the cooling system.  Whe…";
CM_ SG_ 2566838014 PwrEltrnsClntFllSwth "Indicates the coolant fill switch position for the power electronics cooling system.  This switch is used to enable the pump for filling the cooling system.  Wh…";
CM_ BO_ 2566838782 "Auxiliary Input/Output Status 1";
CM_ SG_ 2566838782 AuxiliaryIO01 "Identifies the current status of auxiliary input/output functions that are configured uniquely per application.00b = Auxiliary channel off01b = Auxiliary channe…";
CM_ SG_ 2566838782 AuxiliaryIO02 "Identifies the current status of auxiliary input/output functions that are configured uniquely per application.00b = Auxiliary channel off01b = Auxiliary channe…";
CM_ SG_ 2566838782 AuxiliaryIO03 "Identifies the current status of auxiliary input/output functions that are configured uniquely per application.00b = Auxiliary channel off01b = Auxiliary channe…";
CM_ SG_ 2566838782 AuxiliaryIO04 "Identifies the current status of auxiliary input/output functions that are configured uniquely per application.00b = Auxiliary channel off01b = Auxiliary channe…";
CM_ SG_ 2566838782 AuxiliaryIO05 "Identifies the current status of auxiliary input/output functions that are configured uniquely per application.00b = Auxiliary channel off01b = Auxiliary channe…";
CM_ SG_ 2566838782 AuxiliaryIO06 "Identifies the current status of auxiliary input/output functions that are configured uniquely per application.00b = Auxiliary channel off01b = Auxiliary channe…";
CM_ SG_ 2566838782 AuxiliaryIO07 "Identifies the current status of auxiliary input/output functions that are configured uniquely per application.00b = Auxiliary channel off01b = Auxiliary channe…";
CM_ SG_ 2566838782 AuxiliaryIO08 "Identifies the current status of auxiliary input/output functions that are configured uniquely per application.00b = Auxiliary channel off01b = Auxiliary channe…";
CM_ SG_ 2566838782 AuxiliaryIO09 "Identifies the current status of auxiliary input/output functions that are configured uniquely per application.00b = Auxiliary channel off01b = Auxiliary channe…";
CM_ SG_ 2566838782 AuxiliaryIO10 "Identifies the current status of auxiliary input/output functions that are configured uniquely per application.00b = Auxiliary channel off01b = Auxiliary channe…";
CM_ SG_ 2566838782 AuxiliaryIO11 "Identifies the current status of auxiliary input/output functions that are configured uniquely per application.00b = Auxiliary channel off01b = Auxiliary channe…";
CM_ SG_ 2566838782 AuxiliaryIO12 "Identifies the current status of auxiliary input/output functions that are configured uniquely per application.00b = Auxiliary channel off01b = Auxiliary channe…";
CM_ SG_ 2566838782 AuxiliaryIO13 "Identifies the current status of auxiliary input/output functions that are configured uniquely per application.00b = Auxiliary channel off01b = Auxiliary channe…";
CM_ SG_ 2566838782 AuxiliaryIO14 "Identifies the current status of auxiliary input/output functions that are configured uniquely per application.00b = Auxiliary channel off01b = Auxiliary channe…";
CM_ SG_ 2566838782 AuxiliaryIO15 "Identifies the current status of auxiliary input/output functions that are configured uniquely per application.00b = Auxiliary channel off01b = Auxiliary channe…";
CM_ SG_ 2566838782 AuxiliaryIO16 "Identifies the current status of auxiliary input/output functions that are configured uniquely per application.00b = Auxiliary channel off01b = Auxiliary channe…";
CM_ SG_ 2566838782 AuxiliaryIOChannel1 "Auxiliary channel of data (16 bit) read by the ECU.  This data is in A/D counts and is manufacturer specific.  It may be configured uniquely per application.…";
CM_ SG_ 2566838782 AuxiliaryIOChannel2 "Auxiliary channel of data (16 bit) read by the ECU.  This data is in A/D counts and is manufacturer specific.  It may be configured uniquely per application.…";
CM_ BO_ 2566839038 "Software Identification";
CM_ SG_ 2566839038 NmrfSftwrIdntftnFlds "Number of software identification designators represented in the software identification parameter group.…";
CM_ SG_ 2566839038 SoftwareIdentification "Software identification of an electronic module.  As an example, this parameter may be represented with ASCII characters MMDDYYaa where MM is the month, DD is t…";
CM_ BO_ 2566839294 "Engine Fluid Level/Pressure 2";
CM_ SG_ 2566839294 EngnFl1InjtrMtrngRl1Prssr "The gage pressure of fuel in the primary, or first, metering rail as delivered from the supply pump to the injector metering intake.…";
CM_ SG_ 2566839294 EngnFl1InjtrMtrngRl2Prssr "The gage pressure of fuel in the metering rail #2 as delivered from the supply pump to the injector metering intake.  See Figure SPN16_A for fuel system related…";
CM_ SG_ 2566839294 EngnFl1InjtrTmngRl1Prssr "The gage pressure of fuel in the timing rail delivered from the supply pump to the injector timing intake.…";
CM_ SG_ 2566839294 EngnFlInjtnCntrlPrssr "The gage pressure of the engine oil in the hydraulic accumulator that powers an intensifier used for fuel injection.…";
CM_ BO_ 2566839550 "Idle Operation";
CM_ SG_ 2566839550 EngineTotalIdleFuelUsed "Accumulated amount of fuel used during vehicle operation while under idle conditions.…";
CM_ SG_ 2566839550 EngineTotalIdleHours "Accumulated time of operation of the engine while under idle conditions.…";
CM_ BO_ 2566839806 "Turbocharger";
CM_ SG_ 2566839806 EngineTurbocharger1Speed "Rotational velocity of rotor in the turbocharger.…";
CM_ SG_ 2566839806 EngnTrhrgrDffrntlSpd "The difference between turbocharger speeds on engine systems with 2 or more turbochargers. If there are are more than 2 turbochargers, it will be the difference…";
CM_ SG_ 2566839806 EngnTrhrgrLOlPrssr1 "Gage pressure of oil in turbocharger lubrication system.…";
CM_ SG_ 2566839806 EngnTrhrgrOlLvlSwth "Switch signal which indicates the presence of oil at the turbocharger00b = No oil present at turbocharger01b = Oil present at turbocharger10b = Error11b = Not a…";
CM_ BO_ 2566840062 "Engine Air Start Pressure";
CM_ SG_ 2566840062 EngineAirStartPressure "Gage pressure of air in an engine starting system that utilizes compressed air to provide the force required to rotate the crankshaft.…";
CM_ SG_ 2566840062 EngineAirStopPressure "Gage pressure of air in an engine stopping system that utilizes compressed air to provide the force required to stop the crankshaft. Engine stopping air is typi…";
CM_ SG_ 2566840062 EngnArStrtPrssrExtnddRng "Gage pressure of air in an engine starting system that utilizes compressed air to provide the force required to rotate the crankshaft.See SPN 82 for higher reso…";
CM_ BO_ 2566840318 "Electronic Engine Controller 3";
CM_ SG_ 2566840318 Aftertreatment1ExhaustDewPoint "Indicates that the temperature on the exhaust side of the aftertreatment has exceeded the dew point, as estimated by the ECU in exhaust bank 1.00b = Not exceede…";
CM_ SG_ 2566840318 Aftertreatment1IntakeDewPoint "Indicates that the temperature on the intake side of the aftertreatment system has exceeded the dew point, as estimated by the ECU in exhaust bank 1.00b = Not e…";
CM_ SG_ 2566840318 Aftertreatment2ExhaustDewPoint "Indicates that the temperature on the exhaust side of the aftertreatment has exceeded the dew point, as estimated by the ECU in exhaust bank 2.00b = Not exceede…";
CM_ SG_ 2566840318 Aftertreatment2IntakeDewPoint "Indicates that the temperature on the intake side of the aftertreatment system has exceeded the dew point, as estimated by the ECU in exhaust bank 2.00b = Not e…";
CM_ SG_ 2566840318 Aftrtrtmnt1ExhstGsMssFlwRt "Measured/calculated exhaust gas mass upstream of the aftertreatment system in exhaust bank 1 and 2.…";
CM_ SG_ 2566840318 EnginesDesiredOperatingSpeed "An indication by the engine of the optimal operating speed of the engine for the current existing conditions.  These conditions may include the torque generated…";
CM_ SG_ 2566840318 EsDsdOptSpdAstAdstt "This byte is utilized in transmission gear selection routines and indicates the engine's preference of lower versus higher engine speeds should its desired spee…";
CM_ SG_ 2566840318 EstmtdEngnPrstLsssPrntTrq "The calculated torque that indicates the estimated amount of torque loss due to engine parasitics, such as cooling fan, air compressor, air conditioning, etc. I…";
CM_ SG_ 2566840318 NominalFrictionPercentTorque "The calculated torque that indicates the amount of torque required by the basic engine itself added by the loss torque of accessories.  It contains the friction…";
CM_ BO_ 2566840574 "Vehicle Distance";
CM_ SG_ 2566840574 TotalVehicleDistance "Accumulated distance traveled by vehicle during its operation.NOTE See SPN 917 for alternate resolution.…";
CM_ SG_ 2566840574 TripDistance "Distance traveled during all or part of a journey.NOTE See SPN 918 for alternate resolution.…";
CM_ BO_ 2566840830 "Retarder Configuration";
CM_ SG_ 2566840830 MaximumRetarderSpeedPoint2 "Maximum speed of retarder (Please reference PGN 65249).…";
CM_ SG_ 2566840830 RetarderControlMethod "This parameter identifies the number of steps used by the retarder.…";
CM_ SG_ 2566840830 RetarderLocation "This parameter defines whether the torque/speed curve defined by the retarder configuration message (PGN 65249) is dependent on engine rpm, output shaft rpm, or…";
CM_ SG_ 2566840830 RetarderPercentTorqueAtPoint3 "The torque limit that indicates the available retarder torque which can be provided by the retarder at points 3 and 4 of the retarder torque map.  Please refere…";
CM_ SG_ 2566840830 RetarderPercentTorqueAtPoint4 "The torque limit that indicates the available retarder torque which can be provided by the retarder at points 3 and 4 of the retarder torque map.  Please refere…";
CM_ SG_ 2566840830 RetarderReferenceTorque "This parameter is the 100% reference value for all defined indicated retarder torque parameters.  It is only defined once and doesn't change if a different reta…";
CM_ SG_ 2566840830 RetarderSpeedAtIdlePoint1 "Please reference PGN 65249…";
CM_ SG_ 2566840830 RetarderSpeedAtPeakTorquePoint5 "Please reference PGN 65249…";
CM_ SG_ 2566840830 RetarderSpeedAtPoint3 "Retarder speed of point 3 of the engine retarder torque map.  Please reference PGN 65249.…";
CM_ SG_ 2566840830 RetarderSpeedAtPoint4 "Retarder speed of point 4 of the engine retarder torque map.  Please reference PGN 65249.…";
CM_ SG_ 2566840830 RetarderType "A vehicle retarder is a supplementary device to the wheel brakes for the driver to better control the vehicle.  The wheel brakes used in the vehicle are not des…";
CM_ SG_ 2566840830 RtrdrPrntTrqAtIdlPnt1 "The torque limit that indicates the available retarder torque which can be provided by the retarder at idle speed.  The data is transmitted in indicated torque …";
CM_ SG_ 2566840830 RtrdrPrntTrqAtMxmmSpdPnt2 "The torque limit that indicates the available retarder torque which can be provided by the retarder at its maximum speed.  Please reference PGN 65249.  The data…";
CM_ SG_ 2566840830 RtrdrPrntTrqAtPkTrqPnt5 "The torque limit that indicates the available retarder torque which can be provided by the retarder at point 5 of the retarder torque map.  Please reference PGN…";
CM_ BO_ 2566841086 "Transmission Configuration";
CM_ SG_ 2566841086 NumberofForwardGearRatios "Number of forward gear ratios in the transmission, provided as part of the configuration.…";
CM_ SG_ 2566841086 NumberofReverseGearRatios "Number of reverse gear ratios in the transmission, provided as part of the transmission configuration.…";
CM_ SG_ 2566841086 TransmissionGearRatio "The transmission configuration describes the number of forward gears, the number of reverse gears, and the ratio of each gear with the following resolution.…";
CM_ BO_ 2566841342 "Engine Configuration 1";
CM_ SG_ 2566841342 EngineDefaultIdleTorqueLimit "Companion parameter to Transmission Communications Failure Idle Torque Limit (SPN 7827).  This echo parameter provides confirmation to the transmission that the…";
CM_ SG_ 2566841342 EngineDefaultTorqueLimit "Companion parameter to Transmission Torque Limit (SPN 1845).  This echo parameter provides confirmation to the transmission that the engine has received and wil…";
CM_ SG_ 2566841342 EngineMomentofInertia "Moment of inertia for the engine, including items driven full-time by the engine such as fuel, oil and cooling pumps.  The inertia from the following items are …";
CM_ SG_ 2566841342 EnginePercentTorqueAtIdlePoint1 "The torque limit that indicates the available engine torque which can be provided by the engine at idle speed.  This parameter may be influenced by engine tempe…";
CM_ SG_ 2566841342 EnginePercentTorqueAtPoint2 "The torque limit that indicates the available engine torque which can be provided by the engine at point 2 of the engine map (see PGN 65251 and supporting docum…";
CM_ SG_ 2566841342 EnginePercentTorqueAtPoint3 "The torque limit that indicates the available engine torque which can be provided by the engine at point 3, 4, and 5 of the engine map (see PGN 65251 and suppor…";
CM_ SG_ 2566841342 EnginePercentTorqueAtPoint4 "The torque limit that indicates the available engine torque which can be provided by the engine at point 3, 4, and 5 of the engine map (see PGN 65251 and suppor…";
CM_ SG_ 2566841342 EnginePercentTorqueAtPoint5 "The torque limit that indicates the available engine torque which can be provided by the engine at point 3, 4, and 5 of the engine map (see PGN 65251 and suppor…";
CM_ SG_ 2566841342 EngineReferenceTorque "This parameter is the 100% reference value for all defined indicated engine torque parameters.  It is only defined once and doesn't change if a different engine…";
CM_ SG_ 2566841342 EngineSpeedAtHighIdlePoint6 "Engine speed of high idle (point 6) of the engine torque map (see PGN 65251 and supporting document).  In engine configuration mode 3 (see Figure PGN65251_C), p…";
CM_ SG_ 2566841342 EngineSpeedAtIdlePoint1 "Stationary low idle speed of engine which includes influences due to engine temperature (after power up) and other stationary changes (calibration offsets, sens…";
CM_ SG_ 2566841342 EngineSpeedAtPoint2 "Engine speed of point 2 of the engine torque map (see PGN 65251 and supporting document).  In engine configuration mode 1 and 3, point 2 is defined as the kick-…";
CM_ SG_ 2566841342 EngineSpeedAtPoint3 "Engine speed of point 3, 4, and 5 of the engine torque map (see PGN 65251 and supporting document).  It is recommended that one of these points indicate the pea…";
CM_ SG_ 2566841342 EngineSpeedAtPoint4 "Engine speed of point 3, 4, and 5 of the engine torque map (see PGN 65251 and supporting document).  It is recommended that one of these points indicate the pea…";
CM_ SG_ 2566841342 EngineSpeedAtPoint5 "Engine speed of point 3, 4, and 5 of the engine torque map (see PGN 65251 and supporting document).  It is recommended that one of these points indicate the pea…";
CM_ SG_ 2566841342 EngnGnKpOfThEndspdGvrnr "The endspeed governor is defined as a linear line with the following equations (Capital letters mean physical values, small letters mean normalized values).  Re…";
CM_ SG_ 2566841342 EngnMxmmMmntrOvrrdSpdPnt7 "The maximum engine speed above high idle allowed by the engine control during a momentary high idle override.  This duration of the override is limited by the m…";
CM_ SG_ 2566841342 EngnMxmmMmntrOvrrdTmLmt "The maximum time limit allowed to override the engine's high idle speed.…";
CM_ SG_ 2566841342 EngnRqstdSpdCntrlRngLwrLmt "The minimum engine speed that the engine will allow when operating in a speed control/limit mode.…";
CM_ SG_ 2566841342 EngnRqstdSpdCntrlRngUpprLmt "The maximum engine speed regardless of load that the engine will allow when operating in a speed control/limit mode, excluding any maximum momentary engine over…";
CM_ SG_ 2566841342 EngnRqstdTrqCntrlRngLwrLmt "The minimum engine torque that the engine will allow when operating in a torque control/limit mode.…";
CM_ SG_ 2566841342 EngnRqstdTrqCntrlRngUpprLmt "The maximum engine torque that the engine will allow when operating in a torque control/limit mode.…";
CM_ SG_ 2566841342 ERqstdSpdCtRUppLtExtddR "The maximum engine speed regardless of load that the engine will allow when operating in a speed control/limit mode, excluding any maximum momentary engine over…";
CM_ SG_ 2566841342 SupportTSC1ControlPurposeGroup1 "This parameter indicates which TSC1 control purposes are supported in group 1 of 4. One bit is used to convey the support of each Control Purpose. A value of 0 …";
CM_ SG_ 2566841342 SupportTSC1ControlPurposeGroup2 "This parameter indicates which TSC1 control purposes are supported in group 2 of 4. One bit is used to convey the support of each Control Purpose. A value of 0 …";
CM_ SG_ 2566841342 SupportTSC1ControlPurposeGroup3 "This parameter indicates which TSC1 control purposes are supported in group 3 of 4. One bit is used to convey the support of each Control Purpose. A value of 0 …";
CM_ SG_ 2566841342 SupportTSC1ControlPurposeGroup4 "This parameter indicates which TSC1 control purposes are supported in group 4 of 4. One bit is used to convey the support of each Control Purpose. A value of 0 …";
CM_ SG_ 2566841342 SupportVariableRateTSC1Message "This parameter indicates which TSC1 transmission rates are supported by the engine ECU in addition to the required 10ms transmission rate for temporary powertra…";
CM_ BO_ 2566841598 "Shutdown";
CM_ SG_ 2566841598 ACHighPressureFanSwitch "Switch signal which indicates that the pressure in the coolant circuit of an air conditioning system is high and the fan may be engaged.00b = Pressure normal01b…";
CM_ SG_ 2566841598 ClntLvlEngnPrttnShtdwnStts "Parameter which indicates the configuration of the coolant level engine protection shutdown.00b = Disabled - calibration does not allow engine protection due to…";
CM_ SG_ 2566841598 EngineAirShutoffCommandStatus "State signal which indicates when the Air Shutoff  driver output is being driven. Disabled means controller wants air flowing to the engine. Status of the airfl…";
CM_ SG_ 2566841598 EngineAirShutoffStatus "State signal which indicates the actual measured position of the Air Shutoff.00b = Air flow allowed to engine01b = Air flow restricted10b = Error11b = Not Avail…";
CM_ SG_ 2566841598 EngineAlarmAcknowledge "The Engine Alarm Acknowledge Input signal as measured by the reporting ECU.  The Engine Alarm Acknowledge is a mechanism for external acknowledgement of the SPN…";
CM_ SG_ 2566841598 EngineAlarmOutputCommandStatus "State signal which indicates when the Alarm driver output is being driven. Not active means the Controller has no alarm level conditions.00b = Engine Alarm Outp…";
CM_ SG_ 2566841598 EngineIdleShutdownTimerFunction "Parameter which indicates the configuration of the idle shutdown timer system.00b = Disabled in calibration01b = Enabled in calibration10b = Error11b = Not avai…";
CM_ SG_ 2566841598 EngineIdleShutdownTimerOverride "Status signal which indicates the status of the override feature of the idle shutdown timer system.  See Figure SPN590_A.00b = Inactive01b = Active10b = Error11…";
CM_ SG_ 2566841598 EngineIdleShutdownTimerState "Status signal which indicates the current mode of operation of the idle shutdown timer system.  See Figure SPN590_A.00b = Inactive01b = Active10b = Error11b = N…";
CM_ SG_ 2566841598 EngineOilPressureSwitch "Measured engine oil pressure with respect to the pre-set threshold.00b = OK (Engine Oil Pressure Above Min Threshold)01b = Not OK (Engine Oil Pressure Below Min…";
CM_ SG_ 2566841598 EngineOverspeedTest "The engine overspeed test signal as measured by the reporting ECM.  Engine Overspeed Test is a mechanism to simulate engine overspeed situations, while operatin…";
CM_ SG_ 2566841598 EngineWaittoStartLamp "Lamp signal which indicates that the engine is too cold to start and the operator should wait until the signal becomes inactive (turns off).  See SPN 5416 for t…";
CM_ SG_ 2566841598 EngnIdlShtdwnDrvrAlrtMd "Status signal which indicates the status of the driver alert mode of the idle shutdown timer system.  While the driver alert mode is active, the idle shutdown t…";
CM_ SG_ 2566841598 EngnIdlShtdwnhsShtdwnEngn "Status signal which identifies whether or not the engine has been shutdown by the idle shutdown timer system.  See Figure SPN590_A.00b = No01b = Yes10b = Error1…";
CM_ SG_ 2566841598 EngnPrttnSstmApprhngShtdwn "Status signal which indicates that engine shutdown is imminent.  This engine protection signal can be a result of different systems failing, i.e., engine overhe…";
CM_ SG_ 2566841598 EngnPrttnSstmCnfgrtn "Parameter which indicates the configuration of the engine shutdown system.00b = Disabled in calibration01b = Enabled in calibration10b = Error11b = Not availabl…";
CM_ SG_ 2566841598 EngnPrttnSstmhsShtdwnEngn "Status signal which indicates whether or not the engine protection system has shutdown the engine.  See Figure SPN1107_A.00b = No01b = Yes10b = Error11b = Not a…";
CM_ SG_ 2566841598 EngnPrttnSstmTmrOvrrd "Status signal which indicates the status of the override feature of the engine protection system timer. See Figure SPN1107_A.00b = Inactive01b = Active10b = Err…";
CM_ SG_ 2566841598 EngnPrttnSstmTmrStt "Status signal which indicates the current mode of the engine protection system timer system.  See Figure SPN1107_A.00b = Inactive01b = Active10b = Error11b = No…";
CM_ SG_ 2566841598 PTOShutdownhasShutdownEngine "Status signal which identifies whether or not the engine has been shutdown by the PTO shutdown system.00b = No01b = Yes10b = Error11b = Not available…";
CM_ SG_ 2566841598 RefrigerantHighPressureSwitch "Switch signal which indicates the position of the high pressure switch in the coolant circuit of an air conditioning system.  When the switch is enabled, the pr…";
CM_ SG_ 2566841598 RefrigerantLowPressureSwitch "Switch signal which indicates the position of the low pressure switch in the coolant circuit of an air conditioning system.  When the switch is enabled, the pre…";
CM_ BO_ 2566841854 "Engine Hours, Revolutions";
CM_ SG_ 2566841854 EngineTotalHoursofOperation "Accumulated time of operation of engine.…";
CM_ SG_ 2566841854 EngineTotalRevolutions "Accumulated number of revolutions of engine crankshaft during its operation.…";
CM_ BO_ 2566842110 "Time/Date";
CM_ SG_ 2566842110 Day "The day component of the current calendar date.  This should be reported as the day component of the current date at UTC (Universal Time Coordinate), a.k.a. GMT…";
CM_ SG_ 2566842110 Hours "The hour component of the current time of day.  This should be reported as the hour component of the current time at UTC (Universal Time Coordinate), a.k.a. GMT…";
CM_ SG_ 2566842110 Localhouroffset "The hour component of the offset between the UTC (Universal Time Coordinate) time and date and a local time zone time and date.  This is the number of hours to …";
CM_ SG_ 2566842110 Localminuteoffset "The minute component of the offset between the UTC time and date and a local time zone time and date.  This is the number of minutes to add to UTC (Universal Ti…";
CM_ SG_ 2566842110 Minutes "The minutes component of the current time of day.  This should be reported as the minutes component of the current time at UTC (Universal Time Coordinate), a.k.…";
CM_ SG_ 2566842110 Month "The month component of the current calendar date.  This should be reported as the month component of the current date at UTC (Universal Time Coordinate), a.k.a.…";
CM_ SG_ 2566842110 Seconds "The seconds component of the current time of day.  This should be reported as the seconds component of the current time at UTC (Universal Time Coordinate), a.k.…";
CM_ SG_ 2566842110 Year "The year component of the current calendar date.  This should be reported as the year component of the current date at UTC (Universal Time Coordinate), a.k.a. G…";
CM_ BO_ 2566842366 "Vehicle Hours";
CM_ SG_ 2566842366 TotalPowerTakeoffHours "Accumulated time of operation of power takeoff device.…";
CM_ SG_ 2566842366 TotalVehicleHours "Accumulated time of operation of vehicle.…";
CM_ BO_ 2566842622 "Vehicle Direction/Speed";
CM_ SG_ 2566842622 Altitude "Altitude of the vehicle referenced to sea level at standard atmospheric pressure and temperature.…";
CM_ SG_ 2566842622 CompassBearing "Present compass bearing of vehicle.…";
CM_ SG_ 2566842622 NavigationBasedVehicleSpeed "Speed of the vehicle as calculated from a device such as a Global Positioning System (GPS).…";
CM_ SG_ 2566842622 Pitch "Pitch (rotation about the y-axis) of the vehicle as calculated by the navigation device(s).  The pitch angle for an angle of ascent is reported with a positive …";
CM_ BO_ 2566842878 "Fuel Consumption (Liquid) 1";
CM_ SG_ 2566842878 EngineTotalFuelUsed "Accumulated amount of fuel used during vehicle operation.  See SPN 5054 for alternate resolution.…";
CM_ SG_ 2566842878 EngineTripFuel "Fuel consumed during all or part of a journey.  See SPN 5053 for alternate resolution.…";
CM_ BO_ 2566843134 "Vehicle Weight";
CM_ SG_ 2566843134 AxleLocation "To identify to which of several similar devices (such as tires or fuel tanks) the information applies.The low order 4 bits represent a position number, counting…";
CM_ SG_ 2566843134 AxleWeight "Total mass imposed by the tires on the road surface at the specified axle.…";
CM_ SG_ 2566843134 CargoWeight "The mass of freight carried.…";
CM_ SG_ 2566843134 TrailerWeight "Total mass of freight-carrying vehicle designed to be pulled by truck, including the weight of the contents.…";
CM_ BO_ 2566843390 "Component Identification";
CM_ SG_ 2566843390 Make "Make of the component corresponding to the codes defined in the American Trucking Association Vehicle Maintenance Reporting Standard (ATA/VMRS).Note:  This para…";
CM_ SG_ 2566843390 Model "Model of the component.NOTE - The ASCII character * is reserved as a delimiter.…";
CM_ SG_ 2566843390 SerialNumber "Serial number of the component.NOTE - The ASCII character * is reserved as a delimiter.…";
CM_ SG_ 2566843390 UnitNumberPowerUnit "Owner assigned unit number for the power unit of the vehicle.NOTE: The ASCII character * is reserved as a delimiter.…";
CM_ BO_ 2566843646 "Vehicle Identification";
CM_ SG_ 2566843646 VehicleIdentificationNumber "Vehicle Identification Number (VIN) as assigned by the vehicle manufacturer.NOTE The ASCII character “*” is reserved as a delimiter.…";
CM_ BO_ 2566843902 "Cruise Control/Vehicle Speed Setup";
CM_ SG_ 2566843902 CruiseControlHighSetLimitSpeed "Maximum vehicle velocity at which cruise can be set.If Cruise Control Adjusted Maximum Speed (SPN 7495) is supported, then SPN 7495 has priority over SPN 87. Se…";
CM_ SG_ 2566843902 CruiseControlLowSetLimitSpeed "Minimum vehicle velocity at which cruise can be set or minimum vehicle velocity for cruise operation before it will exit cruise control operation.…";
CM_ SG_ 2566843902 MaximumVehicleSpeedLimit "Maximum vehicle velocity allowed.   See SPN 6808 for an alternate resolution.…";
CM_ SG_ 2566843902 MxmmVhlSpdLmtHghRsltn "Maximum vehicle velocity allowed. See SPN 74 for an alternate resolution.…";
CM_ BO_ 2566844158 "Engine Temperature 1";
CM_ SG_ 2566844158 EngineCoolantTemperature "Temperature of liquid found in engine cooling system.…";
CM_ SG_ 2566844158 EngineFuel1Temperature1 "Temperature of fuel (or gas) of the first fuel type. See SPN 3468 for a second temperature measurement of the first fuel type.…";
CM_ SG_ 2566844158 EngineIntercoolerTemperature "Temperature of liquid found in the intercooler located after the turbocharger.…";
CM_ SG_ 2566844158 EngineOilTemperature1 "Temperature of the engine lubricant.Note:  If there is only one engine oil temperature measurement, this SPN should be used.  This is the SPN that is typically …";
CM_ SG_ 2566844158 EngnChrgArClrThrmsttOpnng "The current position of the thermostat used to regulate the temperature of the engine charge air cooler.  A value of 0% represents the thermostat being complete…";
CM_ SG_ 2566844158 EngnTrhrgr1OlTmprtr "Temperature of the turbocharger lubricant.…";
CM_ BO_ 2566844414 "Engine Fluid Level/Pressure 1";
CM_ SG_ 2566844414 EngineCoolantLevel1 "Ratio of volume of liquid found in engine cooling system to total cooling system volume.  Typical monitoring location is in the coolant expansion tank.…";
CM_ SG_ 2566844414 EngineCoolantPressure1 "Gage pressure of liquid found in engine cooling system.See SPN 20 for alternate range and resolution.…";
CM_ SG_ 2566844414 EngineCrankcasePressure1 "First instance of the gage pressure inside engine crankcase.…";
CM_ SG_ 2566844414 EngineFuelDeliveryPressure "Gage pressure of fuel in system as delivered from supply pump to the injection pump.  See SPN 7469 for alternate resolution.See also SPN 5578 for Fuel Delivery …";
CM_ SG_ 2566844414 EngineOilLevel "Ratio of current volume of engine sump oil to maximum required volume.…";
CM_ SG_ 2566844414 EngnExtnddCrnksBlwPrssr "Differential crankcase blow-by pressure as measured through a tube with a venturi. (SPN 1264 is not to be used – obsolete)…";
CM_ SG_ 2566844414 EngineOilPressure1 "Gage pressure of oil in engine lubrication system as provided by oil pump.  See SPN 7468 for alternate resolution.…";
CM_ BO_ 2566844670 "Power Takeoff Information";
CM_ SG_ 2566844670 AuxiliaryInputIgnoreSwitch "Switch signal which overrides other switch input's ability to disable an engine's operating condition.00b = Off01b = On10b = Error11b = Not AvailableThis switch…";
CM_ SG_ 2566844670 EnginePTOGovernorDisableSwitch "Customer or body builder installed switch to prevent operation of engine in PTO mode.00b = Off (PTO mode allowed)01b = On (PTO mode is not allowed)10b = Error11…";
CM_ SG_ 2566844670 EnginePTOGovernorEnableSwitch "Switch signal which indicates that the PTO governor toggle switch is in the enabled (ON) position and therefore it is possible to manage the PTO control functio…";
CM_ SG_ 2566844670 EnginePTOGovernorResumeSwitch "Switch signal of the PTO control activator which indicates that the activator is in the position to resume a previously established PTO governor set speed.00b =…";
CM_ SG_ 2566844670 EnginePTOGovernorSetSwitch "Switch signal of the PTO control activator which indicates that the activator is in the position to set the engine PTO governor set speed.00b = Off01b = On10b =…";
CM_ SG_ 2566844670 EngnPTOGvrnrAlrtSwth "Switch signal of the PTO control activator which indicates that the activator is in the position to accelerate the PTO governor set speed.00b = Off01b = On10b =…";
CM_ SG_ 2566844670 EngnPTOGvrnrCstDlrtSwth "Switch signal of the PTO control activator which indicates that the activator is in the position to coast/decelerate the PTO governor set speed.00b = Off01b = O…";
CM_ SG_ 2566844670 EngnRmtPTOGvrnrVrlSpdCntrlSwth "Switch signal which indicates that the remote PTO governor toggle switch is in the enabled (ON) position.  If the toggle switch is enabled and other conditions …";
CM_ SG_ 2566844670 ERtPTOGvPpdSpdCtSwt "Switch signal which indicates that the remote PTO governor  toggle switch is in the enabled (ON) position.  If the toggle switch is enabled and other conditions…";
CM_ SG_ 2566844670 OprtrEngnPTOGvrnrMmrSltSwth "Measured state of the operator's engine PTO governor memory select switch. This switch selects which of the two available memory locations is to be used to stor…";
CM_ SG_ 2566844670 PowerTakeoffOilTemperature "Temperature of lubricant in device used to transmit engine power to auxiliary equipment.…";
CM_ SG_ 2566844670 PowerTakeoffSetSpeed "Rotational velocity selected by operator for device used to transmit engine power to auxiliary equipment.…";
CM_ SG_ 2566844670 PowerTakeoffSpeed "Rotational velocity of device used to transmit engine power to auxiliary equipment.…";
CM_ SG_ 2566844670 RtPTOGvPpdSpdCtSwt2 "Switch signal which indicates that the remote PTO governor toggle switch #2 is in the enabled (ON) position. If the toggle switch is enabled and other condition…";
CM_ BO_ 2566844926 "Cruise Control/Vehicle Speed 1";
CM_ SG_ 2566844926 BrakeSwitch "Switch signal which indicates that the driver operated brake foot pedal is being pressed.  This brake foot pedal is controlling the vehicles' service brake (tot…";
CM_ SG_ 2566844926 ClutchSwitch "Switch signal which indicates that the clutch pedal is being pressed. It is necessary for a safe drivetrain behavior that the clutch switch is set before the cl…";
CM_ SG_ 2566844926 CrsCntrlCstDlrtSwth "Switch signal of the cruise control activator which indicates that the activator is in the position coast (decelerate).00b = Cruise control activator not in the…";
CM_ SG_ 2566844926 CruiseControlAccelerateSwitch "Switch signal of the cruise control activator which indicates that the activator is in the position accelerate.00b = Cruise control activator not in the positio…";
CM_ SG_ 2566844926 CruiseControlActive "Cruise control is switched on.  It is not ensured that the engine is controlled by cruise control, as in the case of a large driver's demand the engine is contr…";
CM_ SG_ 2566844926 CruiseControlEnableSwitch "Switch signal which indicates that it is possible to manage the cruise control function.00b = Cruise control disabled01b = Cruise control enabled10b = Error11b …";
CM_ SG_ 2566844926 CruiseControlPauseSwitch "Switch signal which indicates the position of the Cruise Control Pause Switch used on Remote Cruise Control applications. The Cruise Control Pause Switch signal…";
CM_ SG_ 2566844926 CruiseControlResumeSwitch "Switch signal of the cruise control activator which indicates that the activator is in the position resume.00b = Cruise control activator not in the position re…";
CM_ SG_ 2566844926 CruiseControlSetSpeed "Value of set (chosen) velocity of velocity control system.  See SPN 6809 for an alternate resolution.If an algorithm that can modify the cruise control set poin…";
CM_ SG_ 2566844926 CruiseControlSetSwitch "Switch signal of the cruise control activator which indicates that the activator is in the position set.00b = Cruise control activator not in the position set01…";
CM_ SG_ 2566844926 CruiseControlStates "This parameter is used to indicate the current state, or mode, of operation by the cruise control device.  This is a status parameter.000b = Off/Disabled001b = …";
CM_ SG_ 2566844926 EngineDiagnosticTestModeSwitch "Switch signal which indicates the position of the engine diagnostic test mode switch.00b = Off01b = On10b = Error11b = Not available…";
CM_ SG_ 2566844926 EngineIdleDecrementSwitch "Switch signal which indicates the position of the idle decrement switch.00b = Off01b = On10b = Error11b = Not available…";
CM_ SG_ 2566844926 EngineIdleIncrementSwitch "Switch signal which indicates the position of the idle increment switch.00b = Off01b = On10b = Error11b = Not available…";
CM_ SG_ 2566844926 EngineShutdownOverrideSwitch "Switch signal which indicates the position of the engine shutdown override switch.  This switch function allows the operator to override an impending engine shu…";
CM_ SG_ 2566844926 ParkBrakeReleaseInhibitRequest "Park Brake Release Inhibit Request signals the desire that an applied park brake remain applied and limit the ability of the vehicle to be moved.  00b = Park Br…";
CM_ SG_ 2566844926 ParkingBrakeSwitch "Switch signal which indicates when the parking brake is set. In general the switch actuated by the operator's park brake control, whether a pedal, lever or othe…";
CM_ SG_ 2566844926 PTOGovernorState "This parameter is used to indicate the current state or mode of operation by the power takeoff (PTO) governor.  In lieu of support for PTO Drive Engagement para…";
CM_ SG_ 2566844926 TwoSpeedAxleSwitch "Switch signal which indicates the current axle range.00b = Low speed range01b = High speed range10b = Error11b = Not available…";
CM_ SG_ 2566844926 WheelBasedVehicleSpeed "Speed of the vehicle as calculated from wheel or tailshaft speed.…";
CM_ BO_ 2566845182 "Fuel Economy (Liquid)";
CM_ SG_ 2566845182 EngineAverageFuelEconomy "Average of instantaneous fuel economy for that segment of vehicle operation of interest.…";
CM_ SG_ 2566845182 EngineFuelRate "Amount of fuel consumed by engine per unit of time.NOTE - See SPN 1600 for alternate resolution.…";
CM_ SG_ 2566845182 EngineInstantaneousFuelEconomy "Current fuel economy at current vehicle velocity.FB00h = Infinite (for example, during engine motoring)…";
CM_ SG_ 2566845182 EngineThrottleValve1Position1 "The position of the valve used to regulate the supply of a fluid, usually air or fuel/air mixture, to an engine.  0% represents no supply and 100% is full suppl…";
CM_ SG_ 2566845182 EngineThrottleValve2Position "The sensed position feedback of the valve, coming from a second electrical actuator for a second throttle plate, used to regulate the supply of a fluid, usually…";
CM_ BO_ 2566845438 "Vehicle Position 1";
CM_ SG_ 2566845438 Latitude "Latitude position of the vehicle.…";
CM_ SG_ 2566845438 Longitude "Longitude position of the vehicle.…";
CM_ BO_ 2566845694 "Tire Condition Message 1";
CM_ SG_ 2566845694 ExtendedTirePressureSupport "Defines the choice of using the tire pressure (PGN 65268) or Extended Tire Pressure (PGN 64578). The state value '01b' indicates the extended tire pressure SPN …";
CM_ SG_ 2566845694 TireAirLeakageRate "The pressure loss rate of a tire.…";
CM_ SG_ 2566845694 TireLocation "Identifies which tire is associated with the parametric data in this PGN.The low order 4 bits represent a position number, counting left to right when facing in…";
CM_ SG_ 2566845694 TirePressure "Pressure at which air is contained in cavity formed by tire and rim.…";
CM_ SG_ 2566845694 TirePressureThresholdDetection "Signal indicating the pressure level of the tire.  The levels defined represent different pressure conditions of the tire:000b = Extreme over pressure - The tir…";
CM_ SG_ 2566845694 TireSensorElectricalFault "Indicates the status of electrical fault on the tire sensor.00b = Ok (No Fault)01b = Not Defined (Fault)10b = Error11b = Not Supported…";
CM_ SG_ 2566845694 TireSensorEnableStatus "Indicates whether the tire sensor is being monitored by the controller or is Enabled/Disabled.00b = Off / Isolated / Disabled01b = On (tire is polled) / Enabled…";
CM_ SG_ 2566845694 TireStatus "Indicates the status of the tire.00b = Ok (no fault)01b = Tire leak detected10b = Error11b = Not Supported…";
CM_ SG_ 2566845694 TireTemperature "Temperature at the surface of the tire sidewall.…";
CM_ BO_ 2566845950 "Ambient Conditions";
CM_ SG_ 2566845950 AmbientAirTemperature "Temperature of air surrounding vehicle.…";
CM_ SG_ 2566845950 BarometricPressure "Absolute air pressure of the atmosphere.…";
CM_ SG_ 2566845950 CabInteriorTemperature "Temperature of air inside the part of the vehicle that encloses the driver and vehicle operating controls.Note: See also SPN 1691.  SPN 1662 is an additional di…";
CM_ SG_ 2566845950 EngineIntake1AirTemperature "Temperature of air entering vehicle air induction system.…";
CM_ SG_ 2566845950 RoadSurfaceTemperature "Indicated temperature of road surface over which vehicle is operating.…";
CM_ BO_ 2566846206 "Intake/Exhaust Conditions 1";
CM_ SG_ 2566846206 Atttt1DsPttFtItPsssSPN3609 "Exhaust pressure as a result of particle accumulation on filter media placed in the exhaust stream.  It is recommended that SPN 3609 be used as it has better re…";
CM_ SG_ 2566846206 EngineExhaustTemperature "Temperature of combustion byproducts leaving the engine.  See SPNs 2433, 2434, 5969 and 5970 for engines with more than one exhaust temperature measurement.…";
CM_ SG_ 2566846206 EngineIntakeAirPressure "Absolute air pressure at input port to intake manifold or air box.…";
CM_ SG_ 2566846206 EngineIntakeManifold1Pressure "The gage pressure measurement of the air intake manifold. If there are multiple air pressure sensors in the intake stream, this is the last one in flow directio…";
CM_ SG_ 2566846206 EngnArFltr1DffrntlPrssr "Change in engine air system pressure, measured across the filter, due to the filter and any accumulation of solid foreign matter on or in the filter.This is the…";
CM_ SG_ 2566846206 EngnClntFltrDffrntlPrssr "Change in coolant pressure, measured across the filter, due to the filter and any accumulation of solid or semisolid matter on or in the filter.…";
CM_ SG_ 2566846206 EngnIntkMnfld1Tmprtr "Temperature of pre-combustion air found in intake manifold of engine air supply system.…";
CM_ BO_ 2566846462 "Vehicle Electrical Power 1";
CM_ SG_ 2566846462 AlternatorCurrent "Measure of electrical current flow from the alternator.  Alternator Current (High Range/Resolution) parameter SPN 1795 has a higher range and resolution of the …";
CM_ SG_ 2566846462 BatteryPotentialPowerInput1 "This parameter measures the first source of battery potential as measured at the input of the ECU/actuator etc. coming from one or more batteries, irrespective …";
CM_ SG_ 2566846462 ChargingSystemPotentialVoltage "Electrical potential measured at the charging system output.  The charging system may be any device charging the batteries.  This includes alternators, generato…";
CM_ SG_ 2566846462 KeySwitchBatteryPotential "Battery potential measured at the input of the electronic control unit supplied through a key switch or similar switching device.…";
CM_ SG_ 2566846462 SLIBattery1NetCurrent "Net flow of electrical current into/out of the first battery or first set of batteries used for starting the engine, for lighting, and for ignition (SLI).  If m…";
CM_ BO_ 2566846718 "Transmission Fluids 1";
CM_ SG_ 2566846718 Transmission1OilPressure "Gage pressure of lubrication fluid in transmission 1, measured after pump.…";
CM_ SG_ 2566846718 TransmissionClutch1Pressure "Gage pressure of oil within a wet clutch.…";
CM_ SG_ 2566846718 TransmissionOilLevel1 "First instance of a transmission oil level indicator. Conveys the ratio of volume of transmission sump oil to recommended volume.…";
CM_ SG_ 2566846718 TransmissionOilLevel1HighLow "First instance of a transmission oil level indicator. Conveys the amount of current volume of transmission sump oil compared to recommended volume. Positive val…";
CM_ SG_ 2566846718 TransmissionOilTemperature1 "First instance of transmission lubricant temperature.…";
CM_ SG_ 2566846718 TrnsmssnFltrDffrntlPrssr "Change in transmission fluid pressure, measured after the filter, due to accumulation of solid or semisolid material on or in the filter.…";
CM_ SG_ 2566846718 TrnsmssnOlLvl1CntdwnTmr "Countdown timer for the first instance of a transmission oil level indicator.  Once all vehicle conditions (such as vehicle stopped, etc) are met, some transmis…";
CM_ SG_ 2566846718 TrnsmssnOlLvl1MsrmntStts "Measurement status for the first instance of a transmission oil level indicator.  Indicates if conditions are acceptable to obtain a valid transmission oil leve…";
CM_ BO_ 2566846974 "Axle Information";
CM_ SG_ 2566846974 DriveAxleLiftAirPressure "Gage pressure of air in system that utilizes compressed air to provide force between axle and frame.…";
CM_ SG_ 2566846974 DriveAxleLocation "To identify to which of several similar devices (such as tires or fuel tanks) the information applies.The low order 4 bits represent a position number, counting…";
CM_ SG_ 2566846974 DriveAxleLubePressure "The drive axle lubricant pressure with location determined by Drive Axle Location (SPN 930).…";
CM_ SG_ 2566846974 DriveAxleTemperature "Temperature of axle lubricant in drive axle.…";
CM_ SG_ 2566846974 SteeringAxleLubePressure "The steering axle lubricant pressure.…";
CM_ SG_ 2566846974 SteeringAxleTemperature "Temperature of lubricant in steering axle.…";
CM_ BO_ 2566847230 "Brakes 1";
CM_ SG_ 2566847230 BrakeApplicationPressure "Gage pressure of compressed air or fluid in vehicle braking system measured at the brake chamber when brake shoe (or pad) is placed against brake drum (or disc)…";
CM_ SG_ 2566847230 BrakePrimaryPressure "Gage pressure of air in the primary, or supply side, of the air brake system.…";
CM_ SG_ 2566847230 BrakeSecondaryPressure "Gage pressure of air in the secondary, or service side, of the air brake system.…";
CM_ SG_ 2566847230 ParkBrakeReleaseInhibitStatus "This parameter provides reports on the status of the Park Brake Release Inhibit function.00b = Park Brake release is not inhibited01b = Park Brake release is in…";
CM_ SG_ 2566847230 ParkingBrakeActuator "Signal which indicates the current state of the actuator(s) that control the parking brake (see also SPN 70 and 5275).00b = Parking brake actuator inactive01b =…";
CM_ SG_ 2566847230 ParkingBrakeRedWarningSignal "This parameter commands the Parking Brake red optical warning signal.00b = off01b = on10b = Reserved 11b = Take no action…";
CM_ BO_ 2566847486 "Retarder fluids";
CM_ SG_ 2566847486 DrvlnRtrdrOvrhtIndtr "Signal from the driveline retarder indicating that its fluid temperature is above normal acceptable limits, and as a result, retarder operation may be altered o…";
CM_ SG_ 2566847486 HydraulicRetarderOilTemperature "Temperature of oil found in a hydraulic retarder.…";
CM_ SG_ 2566847486 HydraulicRetarderPressure "Gage pressure of oil in hydraulic retarder system.…";
CM_ SG_ 2566847486 RtrdrClntOtltTmprtr "Temperature of liquid found in retarder cooling system.…";
CM_ BO_ 2566847742 "Dash Display 1";
CM_ SG_ 2566847742 CargoAmbientTemperature "Temperature of air inside vehicle container used to accommodate cargo.…";
CM_ SG_ 2566847742 EngnFlFltrDffrntlPrssr "Change in fuel delivery pressure, measured across the filter, due to accumulation of solid or semisolid matter on the filter element.…";
CM_ SG_ 2566847742 EngnOlFltrDffrntlPrssr "Change in engine oil pressure, measured across the filter, due to the filter and any accumulation of solid or semisolid material on or in the filter.  See SPN 7…";
CM_ SG_ 2566847742 EngnOlFltrDffrntlPrssrExtnddRng "Change in engine oil pressure, measured across the filter, due to the filter and any accumulation of solid or semisolid material on or in the filter. See SPN 99…";
CM_ SG_ 2566847742 FuelLevel1 "Ratio of volume of fuel to the total volume of fuel storage container.When Fuel Level 2 (SPN 38) is not used, Fuel Level 1 represents the total fuel in all fuel…";
CM_ SG_ 2566847742 FuelLevel2 "Ratio of volume of fuel to the total volume of fuel in the second or right-side storage container.  When Fuel Level 2 is not used, Fuel Level 1 (SPN 96) represe…";
CM_ SG_ 2566847742 WasherFluidLevel "Ratio of volume of liquid to total container volume of fluid reservoir in windshield wash system.…";
CM_ BO_ 2566847998 "Alternate Fuel 1";
CM_ SG_ 2566847998 EngineBlowerBypassValvePosition "Relative position of the blower bypass valve.…";
CM_ SG_ 2566847998 EngineGaseousFuelVentPressure "Gaseous fuel pressure through a vent pipe.…";
CM_ SG_ 2566847998 EngnGssFlPrssrRgltrIntkPrssr "The pressure of the fuel at the intake of the pressure regulator.…";
CM_ SG_ 2566847998 EngnGssFlSpplPrssr1 "Gage pressure of gaseous fuel supply to fuel metering device.…";
CM_ SG_ 2566847998 LNGVprzrClntOtltTmprtr "Temperature of coolant at outlet of liquified natural gas vaporizer. This parameter is also used to determine if coolant has reached freezing temperature.…";
CM_ BO_ 2566848254 "Auxiliary Water Pump Pressure";
CM_ SG_ 2566848254 AuxiliaryPumpPressure "Gage pressure of auxiliary water pump driven as a PTO device.…";
CM_ BO_ 2566848510 "Operator indicators";
CM_ SG_ 2566848510 AtmtStrtRqstInhtIndtr "State signal indicating an engine request for the Automatic Start Request Inhibit Indicator to be active or inactive. The start inhibit indicator can be of lamp…";
CM_ SG_ 2566848510 DrvrWrnngSstmIndtrStts "The desired illumination of the Euro VI defined driver warning system indicator for relevant malfunctions and diesel exhaust fluid (reagent) tank low level.  Us…";
CM_ SG_ 2566848510 EmssnCntrlSstmOprtrIndmntSvrt "Severity status of the operator inducement system for anomalies with the emission control system, such as tampering, low diesel exhaust fluid (reagent) quality,…";
CM_ SG_ 2566848510 EngineOverloadedIndicator "Signal which indicates that the engine is overloaded.00b = No01b = Yes10b = Error11b = Not available…";
CM_ SG_ 2566848510 FlSpplEstmtdRmnngDstn "Estimated remaining distance based on existing fuel supply.…";
CM_ SG_ 2566848510 OperatorShiftPrompt "Command to activate an indicator that advises the operator to shift to a different gear.  Typically this would be used as part of a fuel economy improvement or …";
CM_ SG_ 2566848510 WaterInFuelIndicator1 "Signal which indicates the presence of water in the fuel.00b = No01b = Yes10b = Error11b = Not available…";
CM_ SG_ 2566848510 WaterinFuelIndicator2 "A second indicator of the presense of water in the fuel.  See also SPN 97.00b = No01b = Yes10b = Error11b = Not available…";
CM_ SG_ 2566848510 WtrInChrgArDtAftrChrgArClrIndtr "Signal which indicates the presence of water in charge air duct after charge air cooler.00b = No01b = Yes10b = Error11b = Not available…";
CM_ SG_ 2566848510 EngineOilLifeRemaining "Signal which indicates the actual oil life remaining in percent. 100% means the engine oil is brand new, and 0% means the engine oil is at the end of its life.…";
CM_ BO_ 2624716542 "Configurable Transmit PGNs Command";
CM_ SG_ 2624716542 CmmnddTrnsmtPGNRqstdStt "Identifies the transmit enable state being commanded for the specified PGN on the port identified in SPN 8595.  This parameter is only valid when SPN 8596 is se…";
CM_ SG_ 2624716542 CommandedTransmitPGN "Identifies the PGN to be acted on by the associated SPN 8598.…";
CM_ SG_ 2624716542 TransmitPGNsCommandedPort "Identifies the ECU communication port of the target Configurable ECU for this instance of PGN 28928.  The identification of each ECU communication port is ECU s…";
CM_ SG_ 2624716542 TransmitPGNsTransactionMode "Identifies the command or action being commanded to the target Configurable ECU of this instance of PGN 28928.0000b = Request Port Transmit Status – Identifies …";
CM_ BO_ 2631728894 "Anti-theft Status";
CM_ SG_ 2631728894 AntitheftComponentStatusStates "Indicates whether or not the component can be started.  00b = Unlocked01b = Locked10b = Blocked11b = Not defined00b -  Unlocked = This state indicates that the …";
CM_ SG_ 2631728894 AntitheftModifyPasswordStates "This parameter is used to indicate whether a password request was successfully performed, or if the request could not be perform due to system constraints or if…";
CM_ SG_ 2631728894 AntitheftPasswordValidIndicator "Indicates the presence of a validated password.00b = Password is not a validated password01b = Password is a validated password10b = Error11b = Not available…";
CM_ SG_ 2631728894 AntitheftRandomNumber "A seven byte random numeric code provided by the component in response to an anti-theft request.  This parameter is sent as a numeric value utilizing the full r…";
CM_ SG_ 2631728894 AntthftEnrptnSdPrsntIndtr "Indicates the presence of the encryption seed random number.00b = Random number is not present01b = Random number is present10b = Error11b = Not available…";
CM_ BO_ 2631794430 "Anti-theft Request";
CM_ SG_ 2631794430 AntitheftCommandStates "This parameter is used to identify the specific requests being sent to the component. 000b = Add_Password001b = Delete_Password010b = Change_Password011b = Lock…";
CM_ SG_ 2631794430 AntitheftDesiredExitModeStates "This parameter is used to specify the desired triggers that are to be used by the component in deciding when to transition to the Locked state. 00b = Lock_Upon_…";
CM_ SG_ 2631794430 AntitheftPasswordRepresentation "This parameter is the seven byte numeric code (i.e., 'encrypted password' or 'key') that is generated based on the encryption algorithm, the password supplied b…";
CM_ SG_ 2631794430 AntthftEnrptnIndtrStts "This parameter is used to indicate if a random number seed is being requested, or if an encrypted password is being provided to the component. 00b = Encryption_…";
CM_ BO_ 2631859966 "Reset";
CM_ SG_ 2631859966 BinLiftCountReset "Used to reset the bin lift count as reported in PGN 64594.00b = Do not reset01b = Reset10b = Reserved11b = Take no action…";
CM_ SG_ 2631859966 EngineBuildHoursReset "Command signal used to reset the engine rebuild hours.00b = Do not reset01b = Reset10b = Reserved11b = Take no action…";
CM_ SG_ 2631859966 EngnIgntnCntrlMntnnHrsRst "Used to reset the maintenance hour counter for an engine ignition control module.  The hours remaining until required maintenance is performed are reported in P…";
CM_ SG_ 2631859966 EngnSprkPlgSndrVltgTrkngRst "Command signal used to reset the ignition controller average, maximum, and minimum level tracking of the spark plug secondary voltages and to reset the learned …";
CM_ SG_ 2631859966 ServiceComponentIdentification "Identification of component needing service.  See Table SPN911_A.…";
CM_ SG_ 2631859966 StrngStrghtAhdPstnRst "Used to reset the straight ahead position for a steering sensor in the steering column or a steering controller's straight ahead position on any steerable axle.…";
CM_ SG_ 2631859966 TireConfigurationInformation "Command signal used to initiate change in the tire configuration of the vehicle system. On receipt of this reset, necessary changes will be made in the tire con…";
CM_ SG_ 2631859966 TireSensorInformation "Command signal used to initiate change in the tire sensor identification information.00b = Take no action01b = Reset10b = Reserved11b = Not applicable…";
CM_ SG_ 2631859966 TripGroup1 "Command signal used to reset the PGNs and parameters as defined in Table SPN988_A.00b = Take no action01b = Reset10b = Reserved11b = Not applicable…";
CM_ SG_ 2631859966 TripGroup2Proprietary "Command signal used to reset proprietary parameters associated with a trip but not defined within this document.00b = Take no action01b = Reset10b = Reserved11b…";
CM_ BO_ 2633734398 "Exhaust Oxygen 2";
CM_ SG_ 2633734398 EngineActualExhaust2Oxygen "The actual amount of oxygen in the second exhaust represented as a percentage by volume with respect to the total volume of exhaust gases leaving the engine.…";
CM_ BO_ 2633749502 "Well Stimulation Pump System Lifetime Totals";
CM_ SG_ 2633749502 WellStimulationPumpCycleCount "The total number of cycles on the well stimulation pump. A cycle is defined as a working stage from start to finish.…";
CM_ SG_ 2633749502 WellStimulationPumpWorkingHours "The accumulated amount of time the Well Stimulation Pump has spent working.…";
CM_ SG_ 2633749502 WllStmltnPmpFldEndWrkngHrs "The accumulated time of operation of the fluid end of the pump while under operating conditions.…";
CM_ SG_ 2633749502 WllStmltnPmpPwrEndWrkngHrs "The accumulated time of operation of the power end of the pump while under operating conditions.…";
CM_ BO_ 2633749758 "Well Stimulation Pump System Configuration";
CM_ SG_ 2633749758 WellStimulationPumpGearRatio "Actual ratio of input shaft speed to output shaft speed.…";
CM_ SG_ 2633749758 WellStimulationPumpRatedSpeed "The rated speed of the well stimulation pump.…";
CM_ SG_ 2633749758 WellStimulationPumpStrokeLength "The stroke length of the plunger in a well stimulation pump.…";
CM_ SG_ 2633749758 WllStmltnPmpPlngrDmtr "The diameter of the well stimulation pump plungers…";
CM_ BO_ 2633750526 "Configurable Transmit PGNs Status";
CM_ SG_ 2633750526 CnfgrlTrnsmtPGNCrrntTrnsmtStts "Indicates the current transmit status of the associated PGN on the port identified in SPN 8599.00b = PGN is currently configured for transmit on the port identi…";
CM_ SG_ 2633750526 CnfgrlTrnsmtPGNMdfdStts "Indicates if able to honor the transmit status change request issued in the triggering PGN 28928 message for the associated PGN on the port identified in SPN 85…";
CM_ SG_ 2633750526 CnfgrlTrnsmtPGNPndngChngStts "Indicates if there is a pending change to the transmit capability of the associated PGN on the port identified in SPN 8599.00b = Pending transmit change to disa…";
CM_ SG_ 2633750526 ConfigurableTransmitPGN "Identifies the PGN for which the associated SPNs 8603, 8604, & 8605 apply.…";
CM_ SG_ 2633750526 TransmitPGNsPort "Identifies the ECU communications port of the responding Configurable ECU that is in context for this instance of PGN 64471.  If changes are accepted by the Con…";
CM_ SG_ 2633750526 TransmitPGNsPortCommandStatus "Indicates the overall success in performing the commanded transaction in PGN 28928.  000b = Positive Acknowledgment – PGN 28928 commanded transaction was proces…";
CM_ SG_ 2633750526 TrnsmtPGNsPrtPndngChngsStts "Indicates if there are any pending transmit changes for the specified ECU communication port. 0b = No pending changes to the transmit status for any supported P…";
CM_ BO_ 2633752830 "Aftercooler and Oil Cooler Fluids 1";
CM_ SG_ 2633752830 AltrntrAftrlrClntOtltTmprtr "Temperature of liquid at the aftercooler outlet.…";
CM_ SG_ 2633752830 AltrntrAftrlrClntPmpOtltPrssr "Pressure of liquid at the aftercooler pump outlet…";
CM_ SG_ 2633752830 AltrntrAftrlrClntPmpOtltTmprtr "Temperature of liquid at the aftercooler coolant pump outlet.…";
CM_ SG_ 2633752830 AltrntrOlClrClntIntkTmprtr "Temperature of liquid as it enters the oil cooler of an alternator.…";
CM_ SG_ 2633752830 AltrntrOlClrClntOtltTmprtr "Temperature of liquid after it exits the oil cooler of an alternator.…";
CM_ SG_ 2633752830 AltrntrOlClrOlIntkTmprtr "Temperature of lubricant as it enters the oil cooler of an alternator.…";
CM_ SG_ 2633752830 AltrntrOlClrOlOtltTmprtr "Temperature of lubricant after it exits the oil cooler of an alternator.…";
CM_ SG_ 2633752830 EngnOlClrClntOtltTmprtr "Temperature of liquid after it exits the engine oil cooler.…";
CM_ BO_ 2633753086 "Diode Temperature 2";
CM_ SG_ 2633753086 PowerRectifierDiode9Temperature "Temperature of this diode used in power rectifier.…";
CM_ SG_ 2633753086 PwrRtfrDd10Tmprtr "Temperature of this diode used in power rectifier.…";
CM_ SG_ 2633753086 PwrRtfrDd11Tmprtr "Temperature of this diode used in power rectifier.…";
CM_ SG_ 2633753086 PwrRtfrDd12Tmprtr "Temperature of this diode used in power rectifier.…";
CM_ BO_ 2633753342 "Diode Temperature 1";
CM_ SG_ 2633753342 PowerRectifierDiode1Temperature "Temperature of this diode used in power rectifier.…";
CM_ SG_ 2633753342 PowerRectifierDiode2Temperature "Temperature of this diode used in power rectifier.…";
CM_ SG_ 2633753342 PowerRectifierDiode3Temperature "Temperature of this diode used in power rectifier.…";
CM_ SG_ 2633753342 PowerRectifierDiode4Temperature "Temperature of this diode used in power rectifier.…";
CM_ SG_ 2633753342 PowerRectifierDiode5Temperature "Temperature of this diode used in power rectifier.…";
CM_ SG_ 2633753342 PowerRectifierDiode6Temperature "Temperature of this diode used in power rectifier.…";
CM_ SG_ 2633753342 PowerRectifierDiode7Temperature "Temperature of this diode used in power rectifier.…";
CM_ SG_ 2633753342 PowerRectifierDiode8Temperature "Temperature of this diode used in power rectifier.…";
BA_DEF_ SG_  "SPN" INT 0 524287;
BA_DEF_ BO_  "VFrameFormat" ENUM  "StandardCAN","ExtendedCAN","reserved","J1939PG";
BA_DEF_DEF_  "SPN" 0;
BA_DEF_DEF_  "VFrameFormat" "J1939PG";
BA_ "SPN" SG_ 2566785022 EngnExhstMnfldBnk1Tmprtr1 2434;
BA_ "SPN" SG_ 2566785022 EngnExhstMnfldBnk1Tmprtr2 5970;
BA_ "SPN" SG_ 2566785022 EngnExhstMnfldBnk2Tmprtr1 2433;
BA_ "SPN" SG_ 2566785022 EngnExhstMnfldBnk2Tmprtr2 5969;
BA_ "SPN" SG_ 2566799614 AlternateBeamHeadLightData 2352;
BA_ "SPN" SG_ 2566799614 BackUpLightandAlarmHorn 2392;
BA_ "SPN" SG_ 2566799614 CenterStopLight 2376;
BA_ "SPN" SG_ 2566799614 HighBeamHeadLightData 2348;
BA_ "SPN" SG_ 2566799614 ImplementClearanceLight 2384;
BA_ "SPN" SG_ 2566799614 ImplementLeftFacingWorkLight 2400;
BA_ "SPN" SG_ 2566799614 ImplementLeftForwardWorkLight 2598;
BA_ "SPN" SG_ 2566799614 ImplementMarkerLight 2380;
BA_ "SPN" SG_ 2566799614 ImplementOEMOption1Light 2396;
BA_ "SPN" SG_ 2566799614 ImplementOEMOption2Light 2398;
BA_ "SPN" SG_ 2566799614 ImplementRearWorkLight 2394;
BA_ "SPN" SG_ 2566799614 ImplementRightFacingWorkLight 2407;
BA_ "SPN" SG_ 2566799614 ImplementRightForwardWorkLight 2402;
BA_ "SPN" SG_ 2566799614 LeftStopLight 2372;
BA_ "SPN" SG_ 2566799614 LeftTurnSignalLights 2368;
BA_ "SPN" SG_ 2566799614 LowBeamHeadLightData 2350;
BA_ "SPN" SG_ 2566799614 RearFogLights 2390;
BA_ "SPN" SG_ 2566799614 RightStopLight 2374;
BA_ "SPN" SG_ 2566799614 RightTurnSignalLights 2370;
BA_ "SPN" SG_ 2566799614 RotatingBeaconLight 2386;
BA_ "SPN" SG_ 2566799614 RunningLight 2404;
BA_ "SPN" SG_ 2566799614 TractorClearanceLight 2382;
BA_ "SPN" SG_ 2566799614 TractorFrontFogLights 2388;
BA_ "SPN" SG_ 2566799614 TractorMarkerLight 2378;
BA_ "SPN" SG_ 2566799614 TractorRearLowMountedWorkLights 2360;
BA_ "SPN" SG_ 2566799614 TractorSideLowMountedWorkLights 2364;
BA_ "SPN" SG_ 2566799614 TrtrFrntHghMntdWrkLghts 2356;
BA_ "SPN" SG_ 2566799614 TrtrFrntLwMntdWrkLghts 2354;
BA_ "SPN" SG_ 2566799614 TrtrRrHghMntdWrkLghts 2362;
BA_ "SPN" SG_ 2566799614 TrtrSdHghMntdWrkLghts 2366;
BA_ "SPN" SG_ 2566799614 TrtrUndrsdMntdWrkLghts 2358;
BA_ "SPN" SG_ 2566802174 ActiveShiftConsoleIndicator 2945;
BA_ "SPN" SG_ 2566802174 TransmissionEngineCrankEnable 2900;
BA_ "SPN" SG_ 2566802174 TransmissionManualModeIndicator 8291;
BA_ "SPN" SG_ 2566802174 TransmissionMode10Indicator 6568;
BA_ "SPN" SG_ 2566802174 TransmissionMode1Indicator 2536;
BA_ "SPN" SG_ 2566802174 TransmissionMode2Indicator 2537;
BA_ "SPN" SG_ 2566802174 TransmissionMode3Indicator 2538;
BA_ "SPN" SG_ 2566802174 TransmissionMode4Indicator 2539;
BA_ "SPN" SG_ 2566802174 TransmissionMode5Indicator 4250;
BA_ "SPN" SG_ 2566802174 TransmissionMode6Indicator 4251;
BA_ "SPN" SG_ 2566802174 TransmissionMode7Indicator 4252;
BA_ "SPN" SG_ 2566802174 TransmissionMode8Indicator 4253;
BA_ "SPN" SG_ 2566802174 TransmissionMode9Indicator 6567;
BA_ "SPN" SG_ 2566802174 TransmissionServiceIndicator 4178;
BA_ "SPN" SG_ 2566802174 TransmissionWarningIndicator 5344;
BA_ "SPN" SG_ 2566802174 TrnsmssnArSpplPrssrIndtr 6566;
BA_ "SPN" SG_ 2566802174 TrnsmssnAtNtrlMnlRtrnStt 7696;
BA_ "SPN" SG_ 2566802174 TrnsmssnCrrntRngDsplBlnkStt 4176;
BA_ "SPN" SG_ 2566802174 TrnsmssnRdfrBrkRls 3086;
BA_ "SPN" SG_ 2566802174 TrnsmssnRqstdGrFdk 3289;
BA_ "SPN" SG_ 2566802174 TrnsmssnRqstdRngDsplBlnkStt 1850;
BA_ "SPN" SG_ 2566802174 TrnsmssnRqstdRngDsplFlshStt 1849;
BA_ "SPN" SG_ 2566802174 TrnsmssnRvrsGrShftInhtStts 4261;
BA_ "SPN" SG_ 2566802174 TrnsmssnShftInhtIndtr 1851;
BA_ "SPN" SG_ 2566802430 TransmissionReferenceTorque 7778;
BA_ "SPN" SG_ 2566802430 TransmissionTorqueLimit 1845;
BA_ "SPN" SG_ 2566802430 TrnsmssnCmmntnsFlrIdlTrqLmt 7827;
BA_ "SPN" SG_ 2566802686 BlackOutBrakeStopLampSelect 1841;
BA_ "SPN" SG_ 2566802686 BlackOutWorkLampSelect 1842;
BA_ "SPN" SG_ 2566802686 ConvoyDrivingLampSelect 1837;
BA_ "SPN" SG_ 2566802686 ConvoyLampSelect 1838;
BA_ "SPN" SG_ 2566802686 FrontBlackOutMarkerLampSelect 1839;
BA_ "SPN" SG_ 2566802686 NightVisionIlluminatorSelect 1843;
BA_ "SPN" SG_ 2566802686 OprtrsBlkOtIntnstSltn 1844;
BA_ "SPN" SG_ 2566802686 RearBlackOutMarkerSelect 1840;
BA_ "SPN" SG_ 2566803198 Positionofdoors 1821;
BA_ "SPN" SG_ 2566803198 RampWheelChairLiftPosition 1820;
BA_ "SPN" SG_ 2566803198 Status2ofdoors 3411;
BA_ "SPN" SG_ 2566803454 ROPBrakeControlactive 1818;
BA_ "SPN" SG_ 2566803454 ROPEngineControlactive 1816;
BA_ "SPN" SG_ 2566803454 TrailerVDCActive 5624;
BA_ "SPN" SG_ 2566803454 VDCbrakelightrequest 1815;
BA_ "SPN" SG_ 2566803454 VDCFullyOperational 1814;
BA_ "SPN" SG_ 2566803454 VDCInformationSignal 1813;
BA_ "SPN" SG_ 2566803454 YCBrakeControlactive 1819;
BA_ "SPN" SG_ 2566803454 YCEngineControlactive 1817;
BA_ "SPN" SG_ 2566803710 SLIBattery1Temperature 1800;
BA_ "SPN" SG_ 2566803710 SLIBattery2Temperature 1801;
BA_ "SPN" SG_ 2566803710 SLIBattery3Temperature 2779;
BA_ "SPN" SG_ 2566803710 SLIBattery4Temperature 2780;
BA_ "SPN" SG_ 2566803966 ACCusagedemand 5023;
BA_ "SPN" SG_ 2566803966 RequestedACCDistanceMode 1799;
BA_ "SPN" SG_ 2566804222 AltrntrCrrntHghRngRsltn 1795;
BA_ "SPN" SG_ 2566804222 SLIBattery2NetCurrent 7498;
BA_ "SPN" SG_ 2566804222 SLIBttr1NtCrrntHghRngRsltn 2579;
BA_ "SPN" SG_ 2566804478 HLtTsdMCtsRPMRtd 1777;
BA_ "SPN" SG_ 2566804478 HLtTsdMCtsTqRtd 1779;
BA_ "SPN" SG_ 2566804478 LwLmtThrshldfrMxmmRPMfrmRtrdr 1776;
BA_ "SPN" SG_ 2566804478 LwLmtThrshldfrMxmmTrqfrmRtrdr 1778;
BA_ "SPN" SG_ 2566804478 MaximumContinuousRetarderSpeed 1780;
BA_ "SPN" SG_ 2566804478 MaximumContinuousRetarderTorque 1782;
BA_ "SPN" SG_ 2566804478 MinimumContinuousRetarderSpeed 1781;
BA_ "SPN" SG_ 2566804478 MinimumContinuousRetarderTorque 1783;
BA_ "SPN" SG_ 2566804734 EHLtTsdMCtsERPM 1769;
BA_ "SPN" SG_ 2566804734 EHLtTsdMCtsTqE 1771;
BA_ "SPN" SG_ 2566804734 ELwLtTsdMxRPME 1768;
BA_ "SPN" SG_ 2566804734 ELwLtTsdMxTqE 1770;
BA_ "SPN" SG_ 2566804734 EngineMaximumContinuousRPM 1772;
BA_ "SPN" SG_ 2566804734 EngineMaximumContinuousTorque 1774;
BA_ "SPN" SG_ 2566804734 EngineMinimumContinuousRPM 1773;
BA_ "SPN" SG_ 2566804734 EngineMinimumContinuousTorque 1775;
BA_ "SPN" SG_ 2566804990 Fuelenergycontent 4245;
BA_ "SPN" SG_ 2566804990 ReferenceEngineGasMassFlowRate 5684;
BA_ "SPN" SG_ 2566804990 SpecificHeatRatio 1767;
BA_ "SPN" SG_ 2566805246 Aftrtrtmnt1DslExhstFldTnkHtr 3363;
BA_ "SPN" SG_ 2566805246 Aftrtrtmnt1DslExhstFldTnkLvl 3517;
BA_ "SPN" SG_ 2566805246 Aftrtrtmnt1DslExhstFldTnkVlm 1761;
BA_ "SPN" SG_ 2566805246 AftrtrtmntSCROprtrIndmntSvrt 5246;
BA_ "SPN" SG_ 2566805246 Atttt1DsExstFdT1HtPFMI 4366;
BA_ "SPN" SG_ 2566805246 Atttt1DsExstFdT1TptPFMI 4365;
BA_ "SPN" SG_ 2566805246 Atttt1DsExstFdTLvVPFMI 3532;
BA_ "SPN" SG_ 2566805246 Atttt1DsExstFdTTpt1 3031;
BA_ "SPN" SG_ 2566805246 AttttDsExstFdTLwLvIdt 5245;
BA_ "SPN" SG_ 2566805758 BellowPressureFrontAxleLeft 1725;
BA_ "SPN" SG_ 2566805758 BellowPressureFrontAxleRight 1726;
BA_ "SPN" SG_ 2566805758 BellowPressureRearAxleLeft 1727;
BA_ "SPN" SG_ 2566805758 BellowPressureRearAxleRight 1728;
BA_ "SPN" SG_ 2566806014 RelativeLevelFrontAxleLeft 1721;
BA_ "SPN" SG_ 2566806014 RelativeLevelFrontAxleRight 1722;
BA_ "SPN" SG_ 2566806014 RelativeLevelRearAxleLeft 1724;
BA_ "SPN" SG_ 2566806014 RelativeLevelRearAxleRight 1723;
BA_ "SPN" SG_ 2566806526 DriverAlertnessLevel 7474;
BA_ "SPN" SG_ 2566806526 DrvrAlrtnssWrnngSstmStt 7475;
BA_ "SPN" SG_ 2566806526 ForwardLaneImagerStatus 8142;
BA_ "SPN" SG_ 2566806526 LaneDepartureWarningSystemState 8141;
BA_ "SPN" SG_ 2566806526 LaneTrackingStatusLeftSide 1710;
BA_ "SPN" SG_ 2566806526 LaneTrackingStatusRightSide 1711;
BA_ "SPN" SG_ 2566806526 LeftWheelLaneDepartureDistance 8139;
BA_ "SPN" SG_ 2566806526 LnDprtrIndtnEnlStts 1702;
BA_ "SPN" SG_ 2566806526 RightWheelLaneDepartureDistance 8140;
BA_ "SPN" SG_ 2566809342 BatteryMainSwitchHoldState 1681;
BA_ "SPN" SG_ 2566809598 AxlrHtrMxmmOtptPwr 1690;
BA_ "SPN" SG_ 2566809854 HdrlOlFltrRstrtnSwth 1713;
BA_ "SPN" SG_ 2566809854 HydraulicOilLevel 2602;
BA_ "SPN" SG_ 2566809854 HydraulicTemperature 1638;
BA_ "SPN" SG_ 2566809854 WinchOilPressureSwitch 1857;
BA_ "SPN" SG_ 2566810110 EngnChrgArClr1OtltTmprtr 2630;
BA_ "SPN" SG_ 2566810110 EngnClntTmprtrHghRsltn 1637;
BA_ "SPN" SG_ 2566810110 EngnIntkMnfld1TmprtrHghRsltn 1636;
BA_ "SPN" SG_ 2566810110 EngnIntkVlvAttnSstmOlTmprtr 2986;
BA_ "SPN" SG_ 2566810366 EngineCoolantPreheatedState 3553;
BA_ "SPN" SG_ 2566810366 EngineOilFilterOutletPressure 3549;
BA_ "SPN" SG_ 2566810366 EngineOilLevelRemoteReservoir 1380;
BA_ "SPN" SG_ 2566810366 EngineOilPreHeatedState 3552;
BA_ "SPN" SG_ 2566810366 EngineOilPrimingPumpSwitch 3550;
BA_ "SPN" SG_ 2566810366 EngineOilPrimingState 3551;
BA_ "SPN" SG_ 2566810366 EngineVentilationStatus 3554;
BA_ "SPN" SG_ 2566810366 EngineWasteOilReservoirLevel 3548;
BA_ "SPN" SG_ 2566810366 EngnFlFltrstnsdDffrntlPrssr 1382;
BA_ "SPN" SG_ 2566810366 EngnFlSpplPmpIntkAsltPrssr 1381;
BA_ "SPN" SG_ 2566810366 EngnFlSpplPmpIntkPrssr 7104;
BA_ "SPN" SG_ 2566810366 FuelPumpPrimerStatus 4083;
BA_ "SPN" SG_ 2566810622 Driver1identification 1625;
BA_ "SPN" SG_ 2566810622 Driver2identification 1626;
BA_ "SPN" SG_ 2566811134 ADRCompliantHeaterInstallation 6821;
BA_ "SPN" SG_ 2566811134 AuxiliaryHeaterMode 1677;
BA_ "SPN" SG_ 2566811134 AuxiliaryHeaterWaterPumpStatus 1676;
BA_ "SPN" SG_ 2566811134 AxlrHtrInptArTmprtr 1688;
BA_ "SPN" SG_ 2566811134 AxlrHtrOtptClntTmprtr 1687;
BA_ "SPN" SG_ 2566811134 AxlrHtrOtptPwrPrnt 1689;
BA_ "SPN" SG_ 2566811134 CabHeatingZone 1680;
BA_ "SPN" SG_ 2566811134 CabVentilation 1678;
BA_ "SPN" SG_ 2566811134 EngineHeatingZone 1679;
BA_ "SPN" SG_ 2566811902 GrossCombinationVehicleWeight 1760;
BA_ "SPN" SG_ 2566811902 PoweredVehicleWeight 1585;
BA_ "SPN" SG_ 2566819326 BatteryPotentialPowerInput2 444;
BA_ "SPN" SG_ 2566819326 ECUPowerOutputSupplyVoltage1 3597;
BA_ "SPN" SG_ 2566819326 ECUPowerOutputSupplyVoltage2 3598;
BA_ "SPN" SG_ 2566819326 ECUPowerOutputSupplyVoltage3 3599;
BA_ "SPN" SG_ 2566819838 EngnExtrnlShtdwnArSpplPrssr 1320;
BA_ "SPN" SG_ 2566820094 CalibrationRecordDurationTime 1253;
BA_ "SPN" SG_ 2566820094 CalibrationRecordStartDay 1251;
BA_ "SPN" SG_ 2566820094 CalibrationRecordStartMonth 1250;
BA_ "SPN" SG_ 2566820094 CalibrationRecordStartYear 1252;
BA_ "SPN" SG_ 2566820094 EnginePeakTorque1 1248;
BA_ "SPN" SG_ 2566820094 EnginePeakTorque2 1249;
BA_ "SPN" SG_ 2566820094 EnginePower 1247;
BA_ "SPN" SG_ 2566820094 EngineTorqueLimit1Transmission 1256;
BA_ "SPN" SG_ 2566820094 EngineTorqueLimit2Transmission 1258;
BA_ "SPN" SG_ 2566820094 EngineTorqueLimit3Transmission 1260;
BA_ "SPN" SG_ 2566820094 EngineTorqueLimit4Transmission 1261;
BA_ "SPN" SG_ 2566820094 EngineTorqueLimit5Switch 1262;
BA_ "SPN" SG_ 2566820094 EngineTorqueLimit6AxleInput 1263;
BA_ "SPN" SG_ 2566820094 EngineTorqueLimitFeature 1632;
BA_ "SPN" SG_ 2566820094 NmrfEngnTrqHstrRrds 1246;
BA_ "SPN" SG_ 2566820094 TorqueLimitingFeatureStatus 1254;
BA_ "SPN" SG_ 2566820094 TransmissionGearRatio1 1255;
BA_ "SPN" SG_ 2566820094 TransmissionGearRatio2 1257;
BA_ "SPN" SG_ 2566820094 TransmissionGearRatio3 1259;
BA_ "SPN" SG_ 2566821118 EngineAuxiliaryCoolantPressure 1203;
BA_ "SPN" SG_ 2566821118 EngnAxlrClntTmprtr 1212;
BA_ "SPN" SG_ 2566821118 EngnClntPmpClntOtltPrssr 8473;
BA_ "SPN" SG_ 2566821118 EngnClntPrssr1ExtnddRng 20;
BA_ "SPN" SG_ 2566821118 EngnClntPrssr2ExtnddRng 7313;
BA_ "SPN" SG_ 2566821118 SeaWaterPumpOutletPressure 2435;
BA_ "SPN" SG_ 2566821630 EngnTrhrgrWstgtAttr1DsrdPstn 5370;
BA_ "SPN" SG_ 2566821630 EngnTrhrgrWstgtAttr1PrlmnrFMI 5371;
BA_ "SPN" SG_ 2566821630 EngnTrhrgrWstgtAttr1Pstn 1188;
BA_ "SPN" SG_ 2566821630 EngnTrhrgrWstgtAttr1TmprtrStts 5372;
BA_ "SPN" SG_ 2566821630 EngnTrhrgrWstgtAttr2DsrdPstn 5373;
BA_ "SPN" SG_ 2566821630 EngnTrhrgrWstgtAttr2Pstn 1189;
BA_ "SPN" SG_ 2566821630 EngnTrhrgrWstgtAttr3Pstn 1190;
BA_ "SPN" SG_ 2566821630 EngnTrhrgrWstgtAttr4Pstn 1191;
BA_ "SPN" SG_ 2566821630 EngnTrhrgrWstgtAttrCntrlArPrssr 1192;
BA_ "SPN" SG_ 2566821886 EngnTrhrgr1TrnOtltTmprtr 1184;
BA_ "SPN" SG_ 2566821886 EngnTrhrgr2TrnOtltTmprtr 1185;
BA_ "SPN" SG_ 2566821886 EngnTrhrgr3TrnOtltTmprtr 1186;
BA_ "SPN" SG_ 2566821886 EngnTrhrgr4TrnOtltTmprtr 1187;
BA_ "SPN" SG_ 2566822142 EngnTrhrgr1TrnIntkTmprtr 1180;
BA_ "SPN" SG_ 2566822142 EngnTrhrgr2TrnIntkTmprtr 1181;
BA_ "SPN" SG_ 2566822142 EngnTrhrgr3TrnIntkTmprtr 1182;
BA_ "SPN" SG_ 2566822142 EngnTrhrgr4TrnIntkTmprtr 1183;
BA_ "SPN" SG_ 2566822398 EngnTrhrgr1CmprssrIntkPrssr 1176;
BA_ "SPN" SG_ 2566822398 EngnTrhrgr2CmprssrIntkPrssr 1177;
BA_ "SPN" SG_ 2566822398 EngnTrhrgr3CmprssrIntkPrssr 1178;
BA_ "SPN" SG_ 2566822398 EngnTrhrgr4CmprssrIntkPrssr 1179;
BA_ "SPN" SG_ 2566822654 EngnTrhrgr1CmprssrIntkTmprtr 1172;
BA_ "SPN" SG_ 2566822654 EngnTrhrgr2CmprssrIntkTmprtr 1173;
BA_ "SPN" SG_ 2566822654 EngnTrhrgr3CmprssrIntkTmprtr 1174;
BA_ "SPN" SG_ 2566822654 EngnTrhrgr4CmprssrIntkTmprtr 1175;
BA_ "SPN" SG_ 2566823166 EngineMainBearing10Temperature 1166;
BA_ "SPN" SG_ 2566823166 EngineMainBearing11Temperature 1167;
BA_ "SPN" SG_ 2566823166 EngineMainBearing12Temperature 6830;
BA_ "SPN" SG_ 2566823166 EngineMainBearing9Temperature 1165;
BA_ "SPN" SG_ 2566823422 EngineMainBearing5Temperature 1161;
BA_ "SPN" SG_ 2566823422 EngineMainBearing6Temperature 1162;
BA_ "SPN" SG_ 2566823422 EngineMainBearing7Temperature 1163;
BA_ "SPN" SG_ 2566823422 EngineMainBearing8Temperature 1164;
BA_ "SPN" SG_ 2566823678 EngineMainBearing1Temperature 1157;
BA_ "SPN" SG_ 2566823678 EngineMainBearing2Temperature 1158;
BA_ "SPN" SG_ 2566823678 EngineMainBearing3Temperature 1159;
BA_ "SPN" SG_ 2566823678 EngineMainBearing4Temperature 1160;
BA_ "SPN" SG_ 2566824190 EngnExhstGsPrt13Tmprtr 1149;
BA_ "SPN" SG_ 2566824190 EngnExhstGsPrt14Tmprtr 1150;
BA_ "SPN" SG_ 2566824190 EngnExhstGsPrt15Tmprtr 1151;
BA_ "SPN" SG_ 2566824190 EngnExhstGsPrt16Tmprtr 1152;
BA_ "SPN" SG_ 2566825214 EngineECUTemperature 1136;
BA_ "SPN" SG_ 2566825214 EngineOilTemperature2 1135;
BA_ "SPN" SG_ 2566825214 EngnExhstGsRrltn1DffrntlPrssr 411;
BA_ "SPN" SG_ 2566825214 EngnExhstGsRrltn1Tmprtr 412;
BA_ "SPN" SG_ 2566825726 EngnTrhrgr1BstPrssr 1127;
BA_ "SPN" SG_ 2566825726 EngnTrhrgr2BstPrssr 1128;
BA_ "SPN" SG_ 2566825726 EngnTrhrgr3BstPrssr 1129;
BA_ "SPN" SG_ 2566825726 EngnTrhrgr4BstPrssr 1130;
BA_ "SPN" SG_ 2566827518 BApptPssHRFtAxLtW 1091;
BA_ "SPN" SG_ 2566827518 BApptPssHRFtAxRtW 1092;
BA_ "SPN" SG_ 2566827518 BApptPssHRRAx1LtW 1093;
BA_ "SPN" SG_ 2566827518 BApptPssHRRAx1RtW 1094;
BA_ "SPN" SG_ 2566827518 BApptPssHRRAx2LtW 1095;
BA_ "SPN" SG_ 2566827518 BApptPssHRRAx2RtW 1096;
BA_ "SPN" SG_ 2566827518 BApptPssHRRAx3LtW 1097;
BA_ "SPN" SG_ 2566827518 BApptPssHRRAx3RtW 1098;
BA_ "SPN" SG_ 2566827774 AirCompressorStatus 1351;
BA_ "SPN" SG_ 2566827774 AirSuspensionSupplyPressure 1090;
BA_ "SPN" SG_ 2566827774 AxlrEqpmntSpplPrssr 1089;
BA_ "SPN" SG_ 2566827774 ParkingandorTrailerAirPressure 1086;
BA_ "SPN" SG_ 2566827774 PneumaticSupplyPressure 46;
BA_ "SPN" SG_ 2566827774 PwrtrnCrtArSpplPrssr 6305;
BA_ "SPN" SG_ 2566827774 ServiceBrakeCircuit1AirPressure 1087;
BA_ "SPN" SG_ 2566827774 ServiceBrakeCircuit2AirPressure 1088;
BA_ "SPN" SG_ 2566831614 EngineFan1EstimatedPercentSpeed 975;
BA_ "SPN" SG_ 2566831614 FanDriveBypassCommandStatus 4212;
BA_ "SPN" SG_ 2566831614 FanDriveState 977;
BA_ "SPN" SG_ 2566831614 FanSpeed 1639;
BA_ "SPN" SG_ 2566831614 HydraulicFanMotorPressure 4211;
BA_ "SPN" SG_ 2566832126 FrontAxleSpeed 904;
BA_ "SPN" SG_ 2566832126 RelativeSpeedFrontAxleLeftWheel 905;
BA_ "SPN" SG_ 2566832126 RltvSpdFrntAxlRghtWhl 906;
BA_ "SPN" SG_ 2566832126 RelativeSpeedRearAxle1LeftWheel 907;
BA_ "SPN" SG_ 2566832126 RltvSpdRrAxl1RghtWhl 908;
BA_ "SPN" SG_ 2566832126 RelativeSpeedRearAxle2LeftWheel 909;
BA_ "SPN" SG_ 2566832126 RltvSpdRrAxl2RghtWhl 910;
BA_ "SPN" SG_ 2566832382 ServiceDelayCalendarTimeBased 915;
BA_ "SPN" SG_ 2566832382 ServiceDistance 914;
BA_ "SPN" SG_ 2566832382 SrvDlOprtnlTmBsd 916;
BA_ "SPN" SG_ 2566832382 ServiceComponentIdentificationA 911;
BA_ "SPN" SG_ 2566832382 ServiceComponentIdentificationB 912;
BA_ "SPN" SG_ 2566832382 ServiceComponentIdentificationC 913;
BA_ "SPN" SG_ 2566832638 TripDistanceHighResolution 918;
BA_ "SPN" SG_ 2566832638 TtlVhlDstnHghRsltn 917;
BA_ "SPN" SG_ 2566837758 Alternator1Status 3353;
BA_ "SPN" SG_ 2566837758 Alternator2Status 3354;
BA_ "SPN" SG_ 2566837758 Alternator3Status 3355;
BA_ "SPN" SG_ 2566837758 Alternator4Status 3356;
BA_ "SPN" SG_ 2566837758 AlternatorSpeed 589;
BA_ "SPN" SG_ 2566838014 HrdSstmBrkPdlRgnrtvBrkngDslSwth 7553;
BA_ "SPN" SG_ 2566838014 HrdSstmCstngRgnrtvBrkngLvlSltr 7556;
BA_ "SPN" SG_ 2566838014 HrdSstmOffBrdChrgrCnntnStts 7551;
BA_ "SPN" SG_ 2566838014 HrdSstmPrplsnClntLvlSwth 7549;
BA_ "SPN" SG_ 2566838014 HrdSstmPrplsnDslSwth 7554;
BA_ "SPN" SG_ 2566838014 HrdSstmPrttnOvrrdSwth 7548;
BA_ "SPN" SG_ 2566838014 HrdSstmPwrEltrnsClntLvlSwth 7550;
BA_ "SPN" SG_ 2566838014 HrdSstmRgnrtvBrkngDslSwth 7552;
BA_ "SPN" SG_ 2566838014 HybridSystemShutdownSwitch 7555;
BA_ "SPN" SG_ 2566838014 PrplsnMtrClntFllSwth 8476;
BA_ "SPN" SG_ 2566838014 PwrEltrnsClntFllSwth 8475;
BA_ "SPN" SG_ 2566838782 AuxiliaryIO01 701;
BA_ "SPN" SG_ 2566838782 AuxiliaryIO02 702;
BA_ "SPN" SG_ 2566838782 AuxiliaryIO03 703;
BA_ "SPN" SG_ 2566838782 AuxiliaryIO04 704;
BA_ "SPN" SG_ 2566838782 AuxiliaryIO05 705;
BA_ "SPN" SG_ 2566838782 AuxiliaryIO06 706;
BA_ "SPN" SG_ 2566838782 AuxiliaryIO07 707;
BA_ "SPN" SG_ 2566838782 AuxiliaryIO08 708;
BA_ "SPN" SG_ 2566838782 AuxiliaryIO09 709;
BA_ "SPN" SG_ 2566838782 AuxiliaryIO10 710;
BA_ "SPN" SG_ 2566838782 AuxiliaryIO11 711;
BA_ "SPN" SG_ 2566838782 AuxiliaryIO12 712;
BA_ "SPN" SG_ 2566838782 AuxiliaryIO13 713;
BA_ "SPN" SG_ 2566838782 AuxiliaryIO14 714;
BA_ "SPN" SG_ 2566838782 AuxiliaryIO15 715;
BA_ "SPN" SG_ 2566838782 AuxiliaryIO16 716;
BA_ "SPN" SG_ 2566838782 AuxiliaryIOChannel1 1083;
BA_ "SPN" SG_ 2566838782 AuxiliaryIOChannel2 1084;
BA_ "SPN" SG_ 2566839038 NmrfSftwrIdntftnFlds 965;
BA_ "SPN" SG_ 2566839038 SoftwareIdentification 234;
BA_ "SPN" SG_ 2566839294 EngnFl1InjtrMtrngRl1Prssr 157;
BA_ "SPN" SG_ 2566839294 EngnFl1InjtrMtrngRl2Prssr 1349;
BA_ "SPN" SG_ 2566839294 EngnFl1InjtrTmngRl1Prssr 156;
BA_ "SPN" SG_ 2566839294 EngnFlInjtnCntrlPrssr 164;
BA_ "SPN" SG_ 2566839550 EngineTotalIdleFuelUsed 236;
BA_ "SPN" SG_ 2566839550 EngineTotalIdleHours 235;
BA_ "SPN" SG_ 2566839806 EngineTurbocharger1Speed 103;
BA_ "SPN" SG_ 2566839806 EngnTrhrgrDffrntlSpd 5980;
BA_ "SPN" SG_ 2566839806 EngnTrhrgrLOlPrssr1 104;
BA_ "SPN" SG_ 2566839806 EngnTrhrgrOlLvlSwth 1665;
BA_ "SPN" SG_ 2566840062 EngineAirStartPressure 82;
BA_ "SPN" SG_ 2566840062 EngineAirStopPressure 6832;
BA_ "SPN" SG_ 2566840062 EngnArStrtPrssrExtnddRng 6831;
BA_ "SPN" SG_ 2566840318 Aftertreatment1ExhaustDewPoint 3238;
BA_ "SPN" SG_ 2566840318 Aftertreatment1IntakeDewPoint 3237;
BA_ "SPN" SG_ 2566840318 Aftertreatment2ExhaustDewPoint 3240;
BA_ "SPN" SG_ 2566840318 Aftertreatment2IntakeDewPoint 3239;
BA_ "SPN" SG_ 2566840318 Aftrtrtmnt1ExhstGsMssFlwRt 3236;
BA_ "SPN" SG_ 2566840318 EnginesDesiredOperatingSpeed 515;
BA_ "SPN" SG_ 2566840318 EsDsdOptSpdAstAdstt 519;
BA_ "SPN" SG_ 2566840318 EstmtdEngnPrstLsssPrntTrq 2978;
BA_ "SPN" SG_ 2566840318 NominalFrictionPercentTorque 514;
BA_ "SPN" SG_ 2566840574 TotalVehicleDistance 245;
BA_ "SPN" SG_ 2566840574 TripDistance 244;
BA_ "SPN" SG_ 2566840830 MaximumRetarderSpeedPoint2 548;
BA_ "SPN" SG_ 2566840830 RetarderControlMethod 557;
BA_ "SPN" SG_ 2566840830 RetarderLocation 902;
BA_ "SPN" SG_ 2566840830 RetarderPercentTorqueAtPoint3 553;
BA_ "SPN" SG_ 2566840830 RetarderPercentTorqueAtPoint4 554;
BA_ "SPN" SG_ 2566840830 RetarderReferenceTorque 556;
BA_ "SPN" SG_ 2566840830 RetarderSpeedAtIdlePoint1 546;
BA_ "SPN" SG_ 2566840830 RetarderSpeedAtPeakTorquePoint5 547;
BA_ "SPN" SG_ 2566840830 RetarderSpeedAtPoint3 549;
BA_ "SPN" SG_ 2566840830 RetarderSpeedAtPoint4 550;
BA_ "SPN" SG_ 2566840830 RetarderType 901;
BA_ "SPN" SG_ 2566840830 RtrdrPrntTrqAtIdlPnt1 551;
BA_ "SPN" SG_ 2566840830 RtrdrPrntTrqAtMxmmSpdPnt2 552;
BA_ "SPN" SG_ 2566840830 RtrdrPrntTrqAtPkTrqPnt5 555;
BA_ "SPN" SG_ 2566841086 NumberofForwardGearRatios 957;
BA_ "SPN" SG_ 2566841086 NumberofReverseGearRatios 958;
BA_ "SPN" SG_ 2566841086 TransmissionGearRatio 581;
BA_ "SPN" SG_ 2566841342 EngineDefaultIdleTorqueLimit 7828;
BA_ "SPN" SG_ 2566841342 EngineDefaultTorqueLimit 1846;
BA_ "SPN" SG_ 2566841342 EngineMomentofInertia 1794;
BA_ "SPN" SG_ 2566841342 EnginePercentTorqueAtIdlePoint1 539;
BA_ "SPN" SG_ 2566841342 EnginePercentTorqueAtPoint2 540;
BA_ "SPN" SG_ 2566841342 EnginePercentTorqueAtPoint3 541;
BA_ "SPN" SG_ 2566841342 EnginePercentTorqueAtPoint4 542;
BA_ "SPN" SG_ 2566841342 EnginePercentTorqueAtPoint5 543;
BA_ "SPN" SG_ 2566841342 EngineReferenceTorque 544;
BA_ "SPN" SG_ 2566841342 EngineSpeedAtHighIdlePoint6 532;
BA_ "SPN" SG_ 2566841342 EngineSpeedAtIdlePoint1 188;
BA_ "SPN" SG_ 2566841342 EngineSpeedAtPoint2 528;
BA_ "SPN" SG_ 2566841342 EngineSpeedAtPoint3 529;
BA_ "SPN" SG_ 2566841342 EngineSpeedAtPoint4 530;
BA_ "SPN" SG_ 2566841342 EngineSpeedAtPoint5 531;
BA_ "SPN" SG_ 2566841342 EngnGnKpOfThEndspdGvrnr 545;
BA_ "SPN" SG_ 2566841342 EngnMxmmMmntrOvrrdSpdPnt7 533;
BA_ "SPN" SG_ 2566841342 EngnMxmmMmntrOvrrdTmLmt 534;
BA_ "SPN" SG_ 2566841342 EngnRqstdSpdCntrlRngLwrLmt 535;
BA_ "SPN" SG_ 2566841342 EngnRqstdSpdCntrlRngUpprLmt 536;
BA_ "SPN" SG_ 2566841342 EngnRqstdTrqCntrlRngLwrLmt 537;
BA_ "SPN" SG_ 2566841342 EngnRqstdTrqCntrlRngUpprLmt 538;
BA_ "SPN" SG_ 2566841342 ERqstdSpdCtRUppLtExtddR 1712;
BA_ "SPN" SG_ 2566841342 SupportTSC1ControlPurposeGroup1 3345;
BA_ "SPN" SG_ 2566841342 SupportTSC1ControlPurposeGroup2 3346;
BA_ "SPN" SG_ 2566841342 SupportTSC1ControlPurposeGroup3 3347;
BA_ "SPN" SG_ 2566841342 SupportTSC1ControlPurposeGroup4 3348;
BA_ "SPN" SG_ 2566841342 SupportVariableRateTSC1Message 3344;
BA_ "SPN" SG_ 2566841598 ACHighPressureFanSwitch 985;
BA_ "SPN" SG_ 2566841598 ClntLvlEngnPrttnShtdwnStts 5566;
BA_ "SPN" SG_ 2566841598 EngineAirShutoffCommandStatus 2813;
BA_ "SPN" SG_ 2566841598 EngineAirShutoffStatus 3667;
BA_ "SPN" SG_ 2566841598 EngineAlarmAcknowledge 2815;
BA_ "SPN" SG_ 2566841598 EngineAlarmOutputCommandStatus 2814;
BA_ "SPN" SG_ 2566841598 EngineIdleShutdownTimerFunction 591;
BA_ "SPN" SG_ 2566841598 EngineIdleShutdownTimerOverride 592;
BA_ "SPN" SG_ 2566841598 EngineIdleShutdownTimerState 590;
BA_ "SPN" SG_ 2566841598 EngineOilPressureSwitch 8159;
BA_ "SPN" SG_ 2566841598 EngineOverspeedTest 2812;
BA_ "SPN" SG_ 2566841598 EngineWaittoStartLamp 1081;
BA_ "SPN" SG_ 2566841598 EngnIdlShtdwnDrvrAlrtMd 594;
BA_ "SPN" SG_ 2566841598 EngnIdlShtdwnhsShtdwnEngn 593;
BA_ "SPN" SG_ 2566841598 EngnPrttnSstmApprhngShtdwn 1109;
BA_ "SPN" SG_ 2566841598 EngnPrttnSstmCnfgrtn 1111;
BA_ "SPN" SG_ 2566841598 EngnPrttnSstmhsShtdwnEngn 1110;
BA_ "SPN" SG_ 2566841598 EngnPrttnSstmTmrOvrrd 1108;
BA_ "SPN" SG_ 2566841598 EngnPrttnSstmTmrStt 1107;
BA_ "SPN" SG_ 2566841598 PTOShutdownhasShutdownEngine 5404;
BA_ "SPN" SG_ 2566841598 RefrigerantHighPressureSwitch 605;
BA_ "SPN" SG_ 2566841598 RefrigerantLowPressureSwitch 875;
BA_ "SPN" SG_ 2566841854 EngineTotalHoursofOperation 247;
BA_ "SPN" SG_ 2566841854 EngineTotalRevolutions 249;
BA_ "SPN" SG_ 2566842110 Day 962;
BA_ "SPN" SG_ 2566842110 Hours 961;
BA_ "SPN" SG_ 2566842110 Localhouroffset 1602;
BA_ "SPN" SG_ 2566842110 Localminuteoffset 1601;
BA_ "SPN" SG_ 2566842110 Minutes 960;
BA_ "SPN" SG_ 2566842110 Month 963;
BA_ "SPN" SG_ 2566842110 Seconds 959;
BA_ "SPN" SG_ 2566842110 Year 964;
BA_ "SPN" SG_ 2566842366 TotalPowerTakeoffHours 248;
BA_ "SPN" SG_ 2566842366 TotalVehicleHours 246;
BA_ "SPN" SG_ 2566842622 Altitude 580;
BA_ "SPN" SG_ 2566842622 CompassBearing 165;
BA_ "SPN" SG_ 2566842622 NavigationBasedVehicleSpeed 517;
BA_ "SPN" SG_ 2566842622 Pitch 583;
BA_ "SPN" SG_ 2566842878 EngineTotalFuelUsed 250;
BA_ "SPN" SG_ 2566842878 EngineTripFuel 182;
BA_ "SPN" SG_ 2566843134 AxleLocation 928;
BA_ "SPN" SG_ 2566843134 AxleWeight 582;
BA_ "SPN" SG_ 2566843134 CargoWeight 181;
BA_ "SPN" SG_ 2566843134 TrailerWeight 180;
BA_ "SPN" SG_ 2566843390 Make 586;
BA_ "SPN" SG_ 2566843390 Model 587;
BA_ "SPN" SG_ 2566843390 SerialNumber 588;
BA_ "SPN" SG_ 2566843390 UnitNumberPowerUnit 233;
BA_ "SPN" SG_ 2566843646 VehicleIdentificationNumber 237;
BA_ "SPN" SG_ 2566843902 CruiseControlHighSetLimitSpeed 87;
BA_ "SPN" SG_ 2566843902 CruiseControlLowSetLimitSpeed 88;
BA_ "SPN" SG_ 2566843902 MaximumVehicleSpeedLimit 74;
BA_ "SPN" SG_ 2566843902 MxmmVhlSpdLmtHghRsltn 6808;
BA_ "SPN" SG_ 2566844158 EngineCoolantTemperature 110;
BA_ "SPN" SG_ 2566844158 EngineFuel1Temperature1 174;
BA_ "SPN" SG_ 2566844158 EngineIntercoolerTemperature 52;
BA_ "SPN" SG_ 2566844158 EngineOilTemperature1 175;
BA_ "SPN" SG_ 2566844158 EngnChrgArClrThrmsttOpnng 1134;
BA_ "SPN" SG_ 2566844158 EngnTrhrgr1OlTmprtr 176;
BA_ "SPN" SG_ 2566844414 EngineCoolantLevel1 111;
BA_ "SPN" SG_ 2566844414 EngineCoolantPressure1 109;
BA_ "SPN" SG_ 2566844414 EngineCrankcasePressure1 101;
BA_ "SPN" SG_ 2566844414 EngineFuelDeliveryPressure 94;
BA_ "SPN" SG_ 2566844414 EngineOilLevel 98;
BA_ "SPN" SG_ 2566844414 EngnExtnddCrnksBlwPrssr 22;
BA_ "SPN" SG_ 2566844414 EngineOilPressure1 100;
BA_ "SPN" SG_ 2566844670 AuxiliaryInputIgnoreSwitch 3448;
BA_ "SPN" SG_ 2566844670 EnginePTOGovernorDisableSwitch 8639;
BA_ "SPN" SG_ 2566844670 EnginePTOGovernorEnableSwitch 980;
BA_ "SPN" SG_ 2566844670 EnginePTOGovernorResumeSwitch 982;
BA_ "SPN" SG_ 2566844670 EnginePTOGovernorSetSwitch 984;
BA_ "SPN" SG_ 2566844670 EngnPTOGvrnrAlrtSwth 981;
BA_ "SPN" SG_ 2566844670 EngnPTOGvrnrCstDlrtSwth 983;
BA_ "SPN" SG_ 2566844670 EngnRmtPTOGvrnrVrlSpdCntrlSwth 978;
BA_ "SPN" SG_ 2566844670 ERtPTOGvPpdSpdCtSwt 979;
BA_ "SPN" SG_ 2566844670 OprtrEngnPTOGvrnrMmrSltSwth 2897;
BA_ "SPN" SG_ 2566844670 PowerTakeoffOilTemperature 90;
BA_ "SPN" SG_ 2566844670 PowerTakeoffSetSpeed 187;
BA_ "SPN" SG_ 2566844670 PowerTakeoffSpeed 186;
BA_ "SPN" SG_ 2566844670 RtPTOGvPpdSpdCtSwt2 3447;
BA_ "SPN" SG_ 2566844926 BrakeSwitch 597;
BA_ "SPN" SG_ 2566844926 ClutchSwitch 598;
BA_ "SPN" SG_ 2566844926 CrsCntrlCstDlrtSwth 600;
BA_ "SPN" SG_ 2566844926 CruiseControlAccelerateSwitch 602;
BA_ "SPN" SG_ 2566844926 CruiseControlActive 595;
BA_ "SPN" SG_ 2566844926 CruiseControlEnableSwitch 596;
BA_ "SPN" SG_ 2566844926 CruiseControlPauseSwitch 1633;
BA_ "SPN" SG_ 2566844926 CruiseControlResumeSwitch 601;
BA_ "SPN" SG_ 2566844926 CruiseControlSetSpeed 86;
BA_ "SPN" SG_ 2566844926 CruiseControlSetSwitch 599;
BA_ "SPN" SG_ 2566844926 CruiseControlStates 527;
BA_ "SPN" SG_ 2566844926 EngineDiagnosticTestModeSwitch 966;
BA_ "SPN" SG_ 2566844926 EngineIdleDecrementSwitch 967;
BA_ "SPN" SG_ 2566844926 EngineIdleIncrementSwitch 968;
BA_ "SPN" SG_ 2566844926 EngineShutdownOverrideSwitch 1237;
BA_ "SPN" SG_ 2566844926 ParkBrakeReleaseInhibitRequest 3807;
BA_ "SPN" SG_ 2566844926 ParkingBrakeSwitch 70;
BA_ "SPN" SG_ 2566844926 PTOGovernorState 976;
BA_ "SPN" SG_ 2566844926 TwoSpeedAxleSwitch 69;
BA_ "SPN" SG_ 2566844926 WheelBasedVehicleSpeed 84;
BA_ "SPN" SG_ 2566845182 EngineAverageFuelEconomy 185;
BA_ "SPN" SG_ 2566845182 EngineFuelRate 183;
BA_ "SPN" SG_ 2566845182 EngineInstantaneousFuelEconomy 184;
BA_ "SPN" SG_ 2566845182 EngineThrottleValve1Position1 51;
BA_ "SPN" SG_ 2566845182 EngineThrottleValve2Position 3673;
BA_ "SPN" SG_ 2566845438 Latitude 584;
BA_ "SPN" SG_ 2566845438 Longitude 585;
BA_ "SPN" SG_ 2566845694 ExtendedTirePressureSupport 6990;
BA_ "SPN" SG_ 2566845694 TireAirLeakageRate 2586;
BA_ "SPN" SG_ 2566845694 TireLocation 929;
BA_ "SPN" SG_ 2566845694 TirePressure 241;
BA_ "SPN" SG_ 2566845694 TirePressureThresholdDetection 2587;
BA_ "SPN" SG_ 2566845694 TireSensorElectricalFault 1697;
BA_ "SPN" SG_ 2566845694 TireSensorEnableStatus 1699;
BA_ "SPN" SG_ 2566845694 TireStatus 1698;
BA_ "SPN" SG_ 2566845694 TireTemperature 242;
BA_ "SPN" SG_ 2566845950 AmbientAirTemperature 171;
BA_ "SPN" SG_ 2566845950 BarometricPressure 108;
BA_ "SPN" SG_ 2566845950 CabInteriorTemperature 170;
BA_ "SPN" SG_ 2566845950 EngineIntake1AirTemperature 172;
BA_ "SPN" SG_ 2566845950 RoadSurfaceTemperature 79;
BA_ "SPN" SG_ 2566846206 Atttt1DsPttFtItPsssSPN3609 81;
BA_ "SPN" SG_ 2566846206 EngineExhaustTemperature 173;
BA_ "SPN" SG_ 2566846206 EngineIntakeAirPressure 106;
BA_ "SPN" SG_ 2566846206 EngineIntakeManifold1Pressure 102;
BA_ "SPN" SG_ 2566846206 EngnArFltr1DffrntlPrssr 107;
BA_ "SPN" SG_ 2566846206 EngnClntFltrDffrntlPrssr 112;
BA_ "SPN" SG_ 2566846206 EngnIntkMnfld1Tmprtr 105;
BA_ "SPN" SG_ 2566846462 AlternatorCurrent 115;
BA_ "SPN" SG_ 2566846462 BatteryPotentialPowerInput1 168;
BA_ "SPN" SG_ 2566846462 ChargingSystemPotentialVoltage 167;
BA_ "SPN" SG_ 2566846462 KeySwitchBatteryPotential 158;
BA_ "SPN" SG_ 2566846462 SLIBattery1NetCurrent 114;
BA_ "SPN" SG_ 2566846718 Transmission1OilPressure 127;
BA_ "SPN" SG_ 2566846718 TransmissionClutch1Pressure 123;
BA_ "SPN" SG_ 2566846718 TransmissionOilLevel1 124;
BA_ "SPN" SG_ 2566846718 TransmissionOilLevel1HighLow 3027;
BA_ "SPN" SG_ 2566846718 TransmissionOilTemperature1 177;
BA_ "SPN" SG_ 2566846718 TrnsmssnFltrDffrntlPrssr 126;
BA_ "SPN" SG_ 2566846718 TrnsmssnOlLvl1CntdwnTmr 3028;
BA_ "SPN" SG_ 2566846718 TrnsmssnOlLvl1MsrmntStts 3026;
BA_ "SPN" SG_ 2566846974 DriveAxleLiftAirPressure 579;
BA_ "SPN" SG_ 2566846974 DriveAxleLocation 930;
BA_ "SPN" SG_ 2566846974 DriveAxleLubePressure 2613;
BA_ "SPN" SG_ 2566846974 DriveAxleTemperature 578;
BA_ "SPN" SG_ 2566846974 SteeringAxleLubePressure 2614;
BA_ "SPN" SG_ 2566846974 SteeringAxleTemperature 75;
BA_ "SPN" SG_ 2566847230 BrakeApplicationPressure 116;
BA_ "SPN" SG_ 2566847230 BrakePrimaryPressure 117;
BA_ "SPN" SG_ 2566847230 BrakeSecondaryPressure 118;
BA_ "SPN" SG_ 2566847230 ParkBrakeReleaseInhibitStatus 3808;
BA_ "SPN" SG_ 2566847230 ParkingBrakeActuator 619;
BA_ "SPN" SG_ 2566847230 ParkingBrakeRedWarningSignal 3557;
BA_ "SPN" SG_ 2566847486 DrvlnRtrdrOvrhtIndtr 5346;
BA_ "SPN" SG_ 2566847486 HydraulicRetarderOilTemperature 120;
BA_ "SPN" SG_ 2566847486 HydraulicRetarderPressure 119;
BA_ "SPN" SG_ 2566847486 RtrdrClntOtltTmprtr 5656;
BA_ "SPN" SG_ 2566847742 CargoAmbientTemperature 169;
BA_ "SPN" SG_ 2566847742 EngnFlFltrDffrntlPrssr 95;
BA_ "SPN" SG_ 2566847742 EngnOlFltrDffrntlPrssr 99;
BA_ "SPN" SG_ 2566847742 EngnOlFltrDffrntlPrssrExtnddRng 7471;
BA_ "SPN" SG_ 2566847742 FuelLevel1 96;
BA_ "SPN" SG_ 2566847742 FuelLevel2 38;
BA_ "SPN" SG_ 2566847742 WasherFluidLevel 80;
BA_ "SPN" SG_ 2566847998 EngineBlowerBypassValvePosition 72;
BA_ "SPN" SG_ 2566847998 EngineGaseousFuelVentPressure 6814;
BA_ "SPN" SG_ 2566847998 EngnGssFlPrssrRgltrIntkPrssr 7581;
BA_ "SPN" SG_ 2566847998 EngnGssFlSpplPrssr1 159;
BA_ "SPN" SG_ 2566847998 LNGVprzrClntOtltTmprtr 7020;
BA_ "SPN" SG_ 2566848254 AuxiliaryPumpPressure 73;
BA_ "SPN" SG_ 2566848510 AtmtStrtRqstInhtIndtr 9373;
BA_ "SPN" SG_ 2566848510 DrvrWrnngSstmIndtrStts 5825;
BA_ "SPN" SG_ 2566848510 EmssnCntrlSstmOprtrIndmntSvrt 5826;
BA_ "SPN" SG_ 2566848510 EngineOverloadedIndicator 8612;
BA_ "SPN" SG_ 2566848510 FlSpplEstmtdRmnngDstn 8428;
BA_ "SPN" SG_ 2566848510 OperatorShiftPrompt 5675;
BA_ "SPN" SG_ 2566848510 WaterInFuelIndicator1 97;
BA_ "SPN" SG_ 2566848510 WaterinFuelIndicator2 6301;
BA_ "SPN" SG_ 2566848510 WtrInChrgArDtAftrChrgArClrIndtr 8611;
BA_ "SPN" SG_ 2566848510 EngineOilLifeRemaining 355;
BA_ "SPN" SG_ 2624716542 CmmnddTrnsmtPGNRqstdStt 8598;
BA_ "SPN" SG_ 2624716542 CommandedTransmitPGN 8597;
BA_ "SPN" SG_ 2624716542 TransmitPGNsCommandedPort 8595;
BA_ "SPN" SG_ 2624716542 TransmitPGNsTransactionMode 8596;
BA_ "SPN" SG_ 2631728894 AntitheftComponentStatusStates 1196;
BA_ "SPN" SG_ 2631728894 AntitheftModifyPasswordStates 1197;
BA_ "SPN" SG_ 2631728894 AntitheftPasswordValidIndicator 1195;
BA_ "SPN" SG_ 2631728894 AntitheftRandomNumber 1198;
BA_ "SPN" SG_ 2631728894 AntthftEnrptnSdPrsntIndtr 1194;
BA_ "SPN" SG_ 2631794430 AntitheftCommandStates 1201;
BA_ "SPN" SG_ 2631794430 AntitheftDesiredExitModeStates 1200;
BA_ "SPN" SG_ 2631794430 AntitheftPasswordRepresentation 1202;
BA_ "SPN" SG_ 2631794430 AntthftEnrptnIndtrStts 1199;
BA_ "SPN" SG_ 2631859966 BinLiftCountReset 6898;
BA_ "SPN" SG_ 2631859966 EngineBuildHoursReset 1211;
BA_ "SPN" SG_ 2631859966 EngnIgntnCntrlMntnnHrsRst 6219;
BA_ "SPN" SG_ 2631859966 EngnSprkPlgSndrVltgTrkngRst 6218;
BA_ "SPN" SG_ 2631859966 ServiceComponentIdentification 1584;
BA_ "SPN" SG_ 2631859966 StrngStrghtAhdPstnRst 3600;
BA_ "SPN" SG_ 2631859966 TireConfigurationInformation 6985;
BA_ "SPN" SG_ 2631859966 TireSensorInformation 6986;
BA_ "SPN" SG_ 2631859966 TripGroup1 988;
BA_ "SPN" SG_ 2631859966 TripGroup2Proprietary 989;
BA_ "SPN" SG_ 2633734398 EngineActualExhaust2Oxygen 9367;
BA_ "SPN" SG_ 2633749502 WellStimulationPumpCycleCount 8659;
BA_ "SPN" SG_ 2633749502 WellStimulationPumpWorkingHours 8658;
BA_ "SPN" SG_ 2633749502 WllStmltnPmpFldEndWrkngHrs 8656;
BA_ "SPN" SG_ 2633749502 WllStmltnPmpPwrEndWrkngHrs 8657;
BA_ "SPN" SG_ 2633749758 WellStimulationPumpGearRatio 8654;
BA_ "SPN" SG_ 2633749758 WellStimulationPumpRatedSpeed 8655;
BA_ "SPN" SG_ 2633749758 WellStimulationPumpStrokeLength 8653;
BA_ "SPN" SG_ 2633749758 WllStmltnPmpPlngrDmtr 8652;
BA_ "SPN" SG_ 2633750526 CnfgrlTrnsmtPGNCrrntTrnsmtStts 8603;
BA_ "SPN" SG_ 2633750526 CnfgrlTrnsmtPGNMdfdStts 8605;
BA_ "SPN" SG_ 2633750526 CnfgrlTrnsmtPGNPndngChngStts 8604;
BA_ "SPN" SG_ 2633750526 ConfigurableTransmitPGN 8602;
BA_ "SPN" SG_ 2633750526 TransmitPGNsPort 8599;
BA_ "SPN" SG_ 2633750526 TransmitPGNsPortCommandStatus 8601;
BA_ "SPN" SG_ 2633750526 TrnsmtPGNsPrtPndngChngsStts 8600;
BA_ "SPN" SG_ 2633752830 AltrntrAftrlrClntOtltTmprtr 8471;
BA_ "SPN" SG_ 2633752830 AltrntrAftrlrClntPmpOtltPrssr 8472;
BA_ "SPN" SG_ 2633752830 AltrntrAftrlrClntPmpOtltTmprtr 8470;
BA_ "SPN" SG_ 2633752830 AltrntrOlClrClntIntkTmprtr 8468;
BA_ "SPN" SG_ 2633752830 AltrntrOlClrClntOtltTmprtr 8469;
BA_ "SPN" SG_ 2633752830 AltrntrOlClrOlIntkTmprtr 8466;
BA_ "SPN" SG_ 2633752830 AltrntrOlClrOlOtltTmprtr 8467;
BA_ "SPN" SG_ 2633752830 EngnOlClrClntOtltTmprtr 728;
BA_ "SPN" SG_ 2633753086 PowerRectifierDiode9Temperature 8459;
BA_ "SPN" SG_ 2633753086 PwrRtfrDd10Tmprtr 8460;
BA_ "SPN" SG_ 2633753086 PwrRtfrDd11Tmprtr 8461;
BA_ "SPN" SG_ 2633753086 PwrRtfrDd12Tmprtr 8462;
BA_ "SPN" SG_ 2633753342 PowerRectifierDiode1Temperature 8451;
BA_ "SPN" SG_ 2633753342 PowerRectifierDiode2Temperature 8452;
BA_ "SPN" SG_ 2633753342 PowerRectifierDiode3Temperature 8453;
BA_ "SPN" SG_ 2633753342 PowerRectifierDiode4Temperature 8454;
BA_ "SPN" SG_ 2633753342 PowerRectifierDiode5Temperature 8455;
BA_ "SPN" SG_ 2633753342 PowerRectifierDiode6Temperature 8456;
BA_ "SPN" SG_ 2633753342 PowerRectifierDiode7Temperature 8457;
BA_ "SPN" SG_ 2633753342 PowerRectifierDiode8Temperature 8458;
